VERSION ""

NS_ :

BS_:

BU_: HVESP01 HVESS

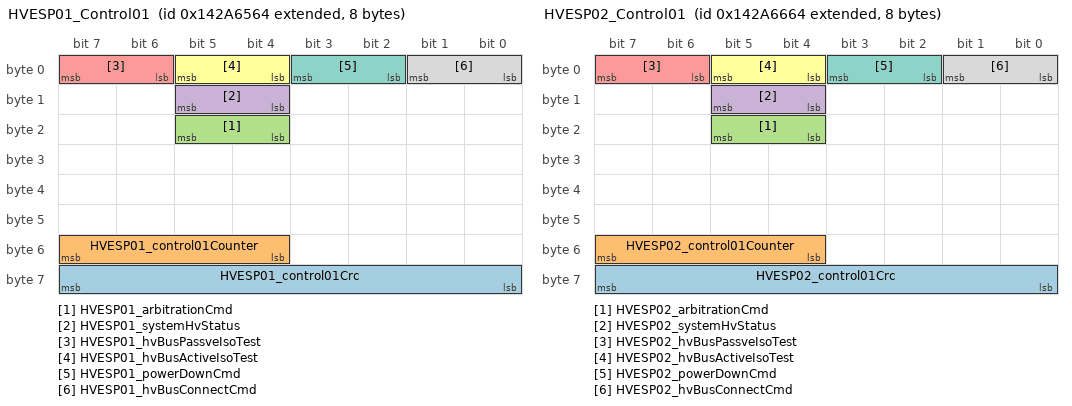
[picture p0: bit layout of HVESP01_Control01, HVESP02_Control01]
BO_ 2485806436 HVESP01_Control01: 8 HVESS
 SG_ HVESP01_control01Crc : 56|8@1+ (1,0) [0|255] ""  HVESS
 SG_ HVESP01_control01Counter : 52|4@1+ (1,0) [0|15] ""  HVESS
 SG_ HVESP01_arbitrationCmd : 20|2@1+ (1,0) [0|3] ""  HVESS
 SG_ HVESP01_systemHvStatus : 12|2@1+ (1,0) [0|3] ""  HVESS
 SG_ HVESP01_hvBusPassveIsoTest : 6|2@1+ (1,0) [0|3] ""  HVESS
 SG_ HVESP01_hvBusActiveIsoTest : 4|2@1+ (1,0) [0|3] ""  HVESS
 SG_ HVESP01_powerDownCmd : 2|2@1+ (1,0) [0|3] ""  HVESS
 SG_ HVESP01_hvBusConnectCmd : 0|2@1+ (1,0) [0|3] ""  HVESS

BO_ 2485806692 HVESP02_Control01: 8 HVESS
 SG_ HVESP02_control01Crc : 56|8@1+ (1,0) [0|255] ""  HVESS
 SG_ HVESP02_control01Counter : 52|4@1+ (1,0) [0|15] ""  HVESS
 SG_ HVESP02_arbitrationCmd : 20|2@1+ (1,0) [0|3] ""  HVESS
 SG_ HVESP02_systemHvStatus : 12|2@1+ (1,0) [0|3] ""  HVESS
 SG_ HVESP02_hvBusPassveIsoTest : 6|2@1+ (1,0) [0|3] ""  HVESS
 SG_ HVESP02_hvBusActiveIsoTest : 4|2@1+ (1,0) [0|3] ""  HVESS
 SG_ HVESP02_powerDownCmd : 2|2@1+ (1,0) [0|3] ""  HVESS
 SG_ HVESP02_hvBusConnectCmd : 0|2@1+ (1,0) [0|3] ""  HVESS

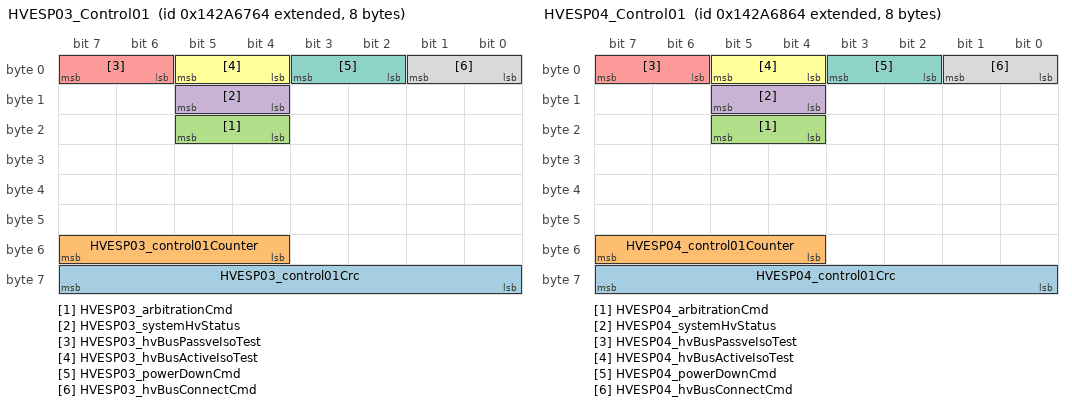
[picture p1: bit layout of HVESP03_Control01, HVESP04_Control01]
BO_ 2485806948 HVESP03_Control01: 8 HVESS
 SG_ HVESP03_control01Crc : 56|8@1+ (1,0) [0|255] ""  HVESS
 SG_ HVESP03_control01Counter : 52|4@1+ (1,0) [0|15] ""  HVESS
 SG_ HVESP03_arbitrationCmd : 20|2@1+ (1,0) [0|3] ""  HVESS
 SG_ HVESP03_systemHvStatus : 12|2@1+ (1,0) [0|3] ""  HVESS
 SG_ HVESP03_hvBusPassveIsoTest : 6|2@1+ (1,0) [0|3] ""  HVESS
 SG_ HVESP03_hvBusActiveIsoTest : 4|2@1+ (1,0) [0|3] ""  HVESS
 SG_ HVESP03_powerDownCmd : 2|2@1+ (1,0) [0|3] ""  HVESS
 SG_ HVESP03_hvBusConnectCmd : 0|2@1+ (1,0) [0|3] ""  HVESS

BO_ 2485807204 HVESP04_Control01: 8 HVESS
 SG_ HVESP04_control01Crc : 56|8@1+ (1,0) [0|255] ""  HVESS
 SG_ HVESP04_control01Counter : 52|4@1+ (1,0) [0|15] ""  HVESS
 SG_ HVESP04_arbitrationCmd : 20|2@1+ (1,0) [0|3] ""  HVESS
 SG_ HVESP04_systemHvStatus : 12|2@1+ (1,0) [0|3] ""  HVESS
 SG_ HVESP04_hvBusPassveIsoTest : 6|2@1+ (1,0) [0|3] ""  HVESS
 SG_ HVESP04_hvBusActiveIsoTest : 4|2@1+ (1,0) [0|3] ""  HVESS
 SG_ HVESP04_powerDownCmd : 2|2@1+ (1,0) [0|3] ""  HVESS
 SG_ HVESP04_hvBusConnectCmd : 0|2@1+ (1,0) [0|3] ""  HVESS

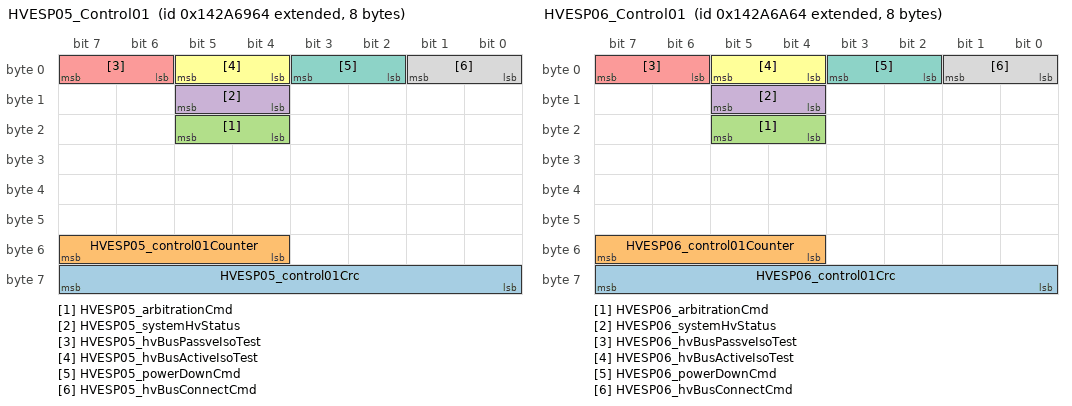
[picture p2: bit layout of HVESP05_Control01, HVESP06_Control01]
BO_ 2485807460 HVESP05_Control01: 8 HVESS
 SG_ HVESP05_control01Crc : 56|8@1+ (1,0) [0|255] ""  HVESS
 SG_ HVESP05_control01Counter : 52|4@1+ (1,0) [0|15] ""  HVESS
 SG_ HVESP05_arbitrationCmd : 20|2@1+ (1,0) [0|3] ""  HVESS
 SG_ HVESP05_systemHvStatus : 12|2@1+ (1,0) [0|3] ""  HVESS
 SG_ HVESP05_hvBusPassveIsoTest : 6|2@1+ (1,0) [0|3] ""  HVESS
 SG_ HVESP05_hvBusActiveIsoTest : 4|2@1+ (1,0) [0|3] ""  HVESS
 SG_ HVESP05_powerDownCmd : 2|2@1+ (1,0) [0|3] ""  HVESS
 SG_ HVESP05_hvBusConnectCmd : 0|2@1+ (1,0) [0|3] ""  HVESS

BO_ 2485807716 HVESP06_Control01: 8 HVESS
 SG_ HVESP06_control01Crc : 56|8@1+ (1,0) [0|255] ""  HVESS
 SG_ HVESP06_control01Counter : 52|4@1+ (1,0) [0|15] ""  HVESS
 SG_ HVESP06_arbitrationCmd : 20|2@1+ (1,0) [0|3] ""  HVESS
 SG_ HVESP06_systemHvStatus : 12|2@1+ (1,0) [0|3] ""  HVESS
 SG_ HVESP06_hvBusPassveIsoTest : 6|2@1+ (1,0) [0|3] ""  HVESS
 SG_ HVESP06_hvBusActiveIsoTest : 4|2@1+ (1,0) [0|3] ""  HVESS
 SG_ HVESP06_powerDownCmd : 2|2@1+ (1,0) [0|3] ""  HVESS
 SG_ HVESP06_hvBusConnectCmd : 0|2@1+ (1,0) [0|3] ""  HVESS

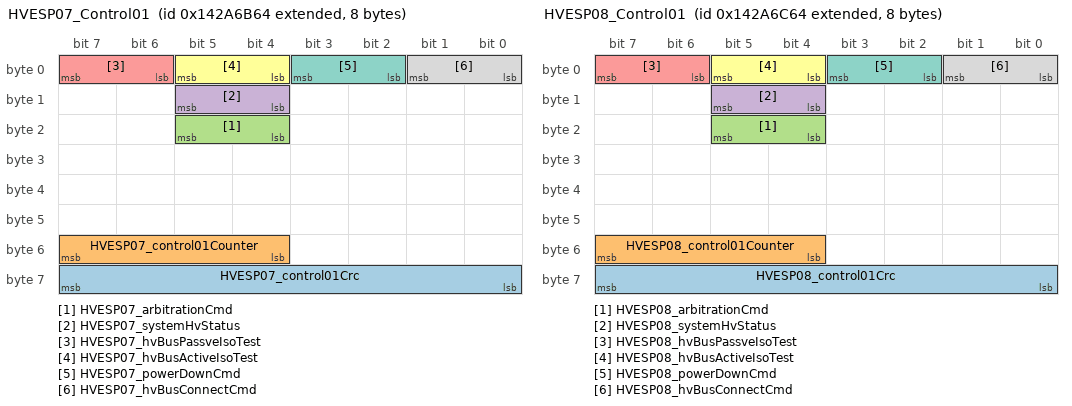
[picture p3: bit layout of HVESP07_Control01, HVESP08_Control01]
BO_ 2485807972 HVESP07_Control01: 8 HVESS
 SG_ HVESP07_control01Crc : 56|8@1+ (1,0) [0|255] ""  HVESS
 SG_ HVESP07_control01Counter : 52|4@1+ (1,0) [0|15] ""  HVESS
 SG_ HVESP07_arbitrationCmd : 20|2@1+ (1,0) [0|3] ""  HVESS
 SG_ HVESP07_systemHvStatus : 12|2@1+ (1,0) [0|3] ""  HVESS
 SG_ HVESP07_hvBusPassveIsoTest : 6|2@1+ (1,0) [0|3] ""  HVESS
 SG_ HVESP07_hvBusActiveIsoTest : 4|2@1+ (1,0) [0|3] ""  HVESS
 SG_ HVESP07_powerDownCmd : 2|2@1+ (1,0) [0|3] ""  HVESS
 SG_ HVESP07_hvBusConnectCmd : 0|2@1+ (1,0) [0|3] ""  HVESS

BO_ 2485808228 HVESP08_Control01: 8 HVESS
 SG_ HVESP08_control01Crc : 56|8@1+ (1,0) [0|255] ""  HVESS
 SG_ HVESP08_control01Counter : 52|4@1+ (1,0) [0|15] ""  HVESS
 SG_ HVESP08_arbitrationCmd : 20|2@1+ (1,0) [0|3] ""  HVESS
 SG_ HVESP08_systemHvStatus : 12|2@1+ (1,0) [0|3] ""  HVESS
 SG_ HVESP08_hvBusPassveIsoTest : 6|2@1+ (1,0) [0|3] ""  HVESS
 SG_ HVESP08_hvBusActiveIsoTest : 4|2@1+ (1,0) [0|3] ""  HVESS
 SG_ HVESP08_powerDownCmd : 2|2@1+ (1,0) [0|3] ""  HVESS
 SG_ HVESP08_hvBusConnectCmd : 0|2@1+ (1,0) [0|3] ""  HVESS

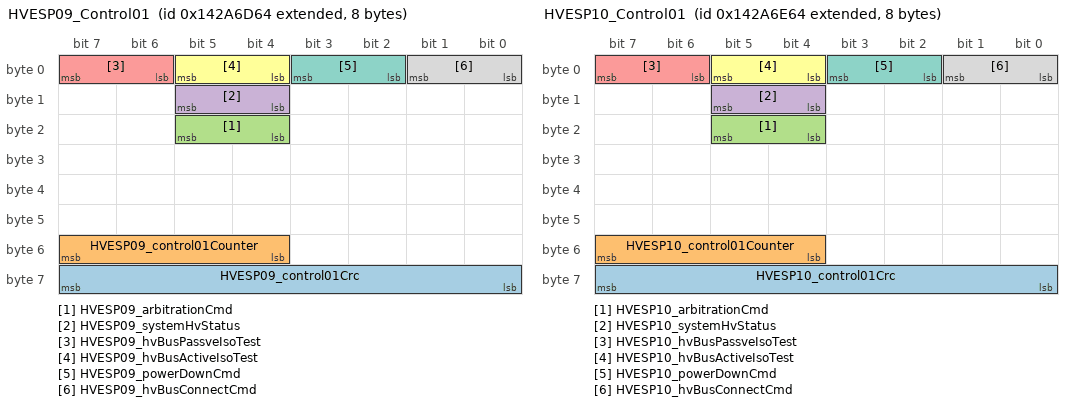
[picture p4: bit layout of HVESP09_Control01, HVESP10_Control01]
BO_ 2485808484 HVESP09_Control01: 8 HVESS
 SG_ HVESP09_control01Crc : 56|8@1+ (1,0) [0|255] ""  HVESS
 SG_ HVESP09_control01Counter : 52|4@1+ (1,0) [0|15] ""  HVESS
 SG_ HVESP09_arbitrationCmd : 20|2@1+ (1,0) [0|3] ""  HVESS
 SG_ HVESP09_systemHvStatus : 12|2@1+ (1,0) [0|3] ""  HVESS
 SG_ HVESP09_hvBusPassveIsoTest : 6|2@1+ (1,0) [0|3] ""  HVESS
 SG_ HVESP09_hvBusActiveIsoTest : 4|2@1+ (1,0) [0|3] ""  HVESS
 SG_ HVESP09_powerDownCmd : 2|2@1+ (1,0) [0|3] ""  HVESS
 SG_ HVESP09_hvBusConnectCmd : 0|2@1+ (1,0) [0|3] ""  HVESS

BO_ 2485808740 HVESP10_Control01: 8 HVESS
 SG_ HVESP10_control01Crc : 56|8@1+ (1,0) [0|255] ""  HVESS
 SG_ HVESP10_control01Counter : 52|4@1+ (1,0) [0|15] ""  HVESS
 SG_ HVESP10_arbitrationCmd : 20|2@1+ (1,0) [0|3] ""  HVESS
 SG_ HVESP10_systemHvStatus : 12|2@1+ (1,0) [0|3] ""  HVESS
 SG_ HVESP10_hvBusPassveIsoTest : 6|2@1+ (1,0) [0|3] ""  HVESS
 SG_ HVESP10_hvBusActiveIsoTest : 4|2@1+ (1,0) [0|3] ""  HVESS
 SG_ HVESP10_powerDownCmd : 2|2@1+ (1,0) [0|3] ""  HVESS
 SG_ HVESP10_hvBusConnectCmd : 0|2@1+ (1,0) [0|3] ""  HVESS

BO_ 2498859365 HVESP01_Data01_1: 8 HVESP01
 SG_ HVESP01_current_1 : 48|16@1+ (0.05,-1600) [-1600|1612.75] "A"  HVESP01
 SG_ HVESP01_voltageLevel_1 : 32|16@1+ (0.05,0) [0|3212.75] "V"  HVESP01
 SG_ HVESP01_availableDischargePower_1 : 0|16@1+ (0.05,0) [0|3212.75] "kW"  HVESP01
 SG_ HVESP01_availableChargePower_1 : 16|16@1+ (0.05,0) [0|3212.75] "kW"  HVESP01

BO_ 2498859366 HVESP01_Data01_2: 8 HVESP01
 SG_ HVESP01_current_2 : 48|16@1+ (0.05,-1600) [-1600|1612.75] "A"  HVESP01
 SG_ HVESP01_voltageLevel_2 : 32|16@1+ (0.05,0) [0|3212.75] "V"  HVESP01
 SG_ HVESP01_availableDischargePower_2 : 0|16@1+ (0.05,0) [0|3212.75] "kW"  HVESP01
 SG_ HVESP01_availableChargePower_2 : 16|16@1+ (0.05,0) [0|3212.75] "kW"  HVESP01

BO_ 2498859367 HVESP01_Data01_3: 8 HVESP01
 SG_ HVESP01_current_3 : 48|16@1+ (0.05,-1600) [-1600|1612.75] "A"  HVESP01
 SG_ HVESP01_voltageLevel_3 : 32|16@1+ (0.05,0) [0|3212.75] "V"  HVESP01
 SG_ HVESP01_availableDischargePower_3 : 0|16@1+ (0.05,0) [0|3212.75] "kW"  HVESP01
 SG_ HVESP01_availableChargePower_3 : 16|16@1+ (0.05,0) [0|3212.75] "kW"  HVESP01

BO_ 2498859368 HVESP01_Data01_4: 8 HVESP01
 SG_ HVESP01_current_4 : 48|16@1+ (0.05,-1600) [-1600|1612.75] "A"  HVESP01
 SG_ HVESP01_voltageLevel_4 : 32|16@1+ (0.05,0) [0|3212.75] "V"  HVESP01
 SG_ HVESP01_availableDischargePower_4 : 0|16@1+ (0.05,0) [0|3212.75] "kW"  HVESP01
 SG_ HVESP01_availableChargePower_4 : 16|16@1+ (0.05,0) [0|3212.75] "kW"  HVESP01

BO_ 2498859369 HVESP01_Data01_5: 8 HVESP01
 SG_ HVESP01_current_5 : 48|16@1+ (0.05,-1600) [-1600|1612.75] "A"  HVESP01
 SG_ HVESP01_voltageLevel_5 : 32|16@1+ (0.05,0) [0|3212.75] "V"  HVESP01
 SG_ HVESP01_availableDischargePower_5 : 0|16@1+ (0.05,0) [0|3212.75] "kW"  HVESP01
 SG_ HVESP01_availableChargePower_5 : 16|16@1+ (0.05,0) [0|3212.75] "kW"  HVESP01

BO_ 2498859370 HVESP01_Data01_6: 8 HVESP01
 SG_ HVESP01_current_6 : 48|16@1+ (0.05,-1600) [-1600|1612.75] "A"  HVESP01
 SG_ HVESP01_voltageLevel_6 : 32|16@1+ (0.05,0) [0|3212.75] "V"  HVESP01
 SG_ HVESP01_availableDischargePower_6 : 0|16@1+ (0.05,0) [0|3212.75] "kW"  HVESP01
 SG_ HVESP01_availableChargePower_6 : 16|16@1+ (0.05,0) [0|3212.75] "kW"  HVESP01

BO_ 2498859371 HVESP01_Data01_7: 8 HVESP01
 SG_ HVESP01_current_7 : 48|16@1+ (0.05,-1600) [-1600|1612.75] "A"  HVESP01
 SG_ HVESP01_voltageLevel_7 : 32|16@1+ (0.05,0) [0|3212.75] "V"  HVESP01
 SG_ HVESP01_availableDischargePower_7 : 0|16@1+ (0.05,0) [0|3212.75] "kW"  HVESP01
 SG_ HVESP01_availableChargePower_7 : 16|16@1+ (0.05,0) [0|3212.75] "kW"  HVESP01

BO_ 2498859372 HVESP01_Data01_8: 8 HVESP01
 SG_ HVESP01_current_8 : 48|16@1+ (0.05,-1600) [-1600|1612.75] "A"  HVESP01
 SG_ HVESP01_voltageLevel_8 : 32|16@1+ (0.05,0) [0|3212.75] "V"  HVESP01
 SG_ HVESP01_availableDischargePower_8 : 0|16@1+ (0.05,0) [0|3212.75] "kW"  HVESP01
 SG_ HVESP01_availableChargePower_8 : 16|16@1+ (0.05,0) [0|3212.75] "kW"  HVESP01

BO_ 2498859621 HVESP01_Data02_1: 8 HVESP01
 SG_ HVESP01_FaultLevel_1 : 56|4@1+ (1,0) [0|15] ""  HVESP01
 SG_ HVESP01_lowestCellVoltage_1 : 32|16@1+ (0.001,0) [0|64.255] "V"  HVESP01
 SG_ HVESP01_highestCellVoltage_1 : 16|16@1+ (0.001,0) [0|64.255] "V"  HVESP01
 SG_ HVESP01_fastUpdateSoc_1 : 0|16@1+ (0.0015625,0) [0|100.3984375] "%"  HVESP01

BO_ 2498859622 HVESP01_Data02_2: 8 HVESP01
 SG_ HVESP01_FaultLevel_2 : 56|4@1+ (1,0) [0|15] ""  HVESP01
 SG_ HVESP01_lowestCellVoltage_2 : 32|16@1+ (0.001,0) [0|64.255] "V"  HVESP01
 SG_ HVESP01_highestCellVoltage_2 : 16|16@1+ (0.001,0) [0|64.255] "V"  HVESP01
 SG_ HVESP01_fastUpdateSoc_2 : 0|16@1+ (0.0015625,0) [0|100.3984375] "%"  HVESP01

BO_ 2498859623 HVESP01_Data02_3: 8 HVESP01
 SG_ HVESP01_FaultLevel_3 : 56|4@1+ (1,0) [0|15] ""  HVESP01
 SG_ HVESP01_lowestCellVoltage_3 : 32|16@1+ (0.001,0) [0|64.255] "V"  HVESP01
 SG_ HVESP01_highestCellVoltage_3 : 16|16@1+ (0.001,0) [0|64.255] "V"  HVESP01
 SG_ HVESP01_fastUpdateSoc_3 : 0|16@1+ (0.0015625,0) [0|100.3984375] "%"  HVESP01

BO_ 2498859624 HVESP01_Data02_4: 8 HVESP01
 SG_ HVESP01_FaultLevel_4 : 56|4@1+ (1,0) [0|15] ""  HVESP01
 SG_ HVESP01_lowestCellVoltage_4 : 32|16@1+ (0.001,0) [0|64.255] "V"  HVESP01
 SG_ HVESP01_highestCellVoltage_4 : 16|16@1+ (0.001,0) [0|64.255] "V"  HVESP01
 SG_ HVESP01_fastUpdateSoc_4 : 0|16@1+ (0.0015625,0) [0|100.3984375] "%"  HVESP01

BO_ 2498859625 HVESP01_Data02_5: 8 HVESP01
 SG_ HVESP01_FaultLevel_5 : 56|4@1+ (1,0) [0|15] ""  HVESP01
 SG_ HVESP01_lowestCellVoltage_5 : 32|16@1+ (0.001,0) [0|64.255] "V"  HVESP01
 SG_ HVESP01_highestCellVoltage_5 : 16|16@1+ (0.001,0) [0|64.255] "V"  HVESP01
 SG_ HVESP01_fastUpdateSoc_5 : 0|16@1+ (0.0015625,0) [0|100.3984375] "%"  HVESP01

BO_ 2498859626 HVESP01_Data02_6: 8 HVESP01
 SG_ HVESP01_FaultLevel_6 : 56|4@1+ (1,0) [0|15] ""  HVESP01
 SG_ HVESP01_lowestCellVoltage_6 : 32|16@1+ (0.001,0) [0|64.255] "V"  HVESP01
 SG_ HVESP01_highestCellVoltage_6 : 16|16@1+ (0.001,0) [0|64.255] "V"  HVESP01
 SG_ HVESP01_fastUpdateSoc_6 : 0|16@1+ (0.0015625,0) [0|100.3984375] "%"  HVESP01

BO_ 2498859627 HVESP01_Data02_7: 8 HVESP01
 SG_ HVESP01_FaultLevel_7 : 56|4@1+ (1,0) [0|15] ""  HVESP01
 SG_ HVESP01_lowestCellVoltage_7 : 32|16@1+ (0.001,0) [0|64.255] "V"  HVESP01
 SG_ HVESP01_highestCellVoltage_7 : 16|16@1+ (0.001,0) [0|64.255] "V"  HVESP01
 SG_ HVESP01_fastUpdateSoc_7 : 0|16@1+ (0.0015625,0) [0|100.3984375] "%"  HVESP01

BO_ 2498859628 HVESP01_Data02_8: 8 HVESP01
 SG_ HVESP01_FaultLevel_8 : 56|4@1+ (1,0) [0|15] ""  HVESP01
 SG_ HVESP01_lowestCellVoltage_8 : 32|16@1+ (0.001,0) [0|64.255] "V"  HVESP01
 SG_ HVESP01_highestCellVoltage_8 : 16|16@1+ (0.001,0) [0|64.255] "V"  HVESP01
 SG_ HVESP01_fastUpdateSoc_8 : 0|16@1+ (0.0015625,0) [0|100.3984375] "%"  HVESP01

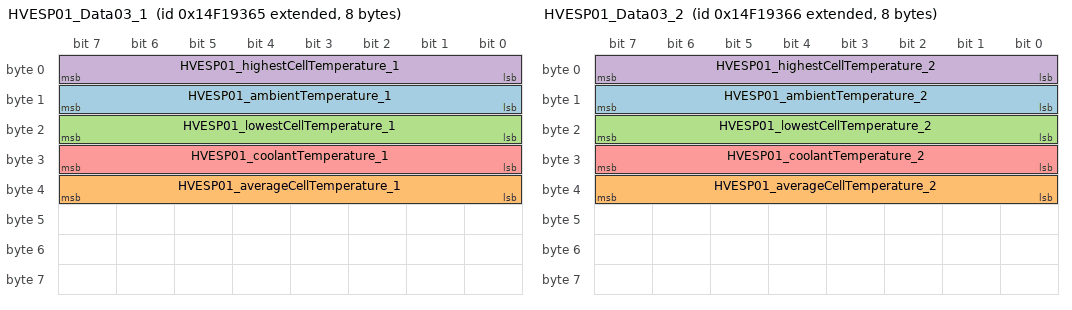
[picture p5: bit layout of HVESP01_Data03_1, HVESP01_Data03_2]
BO_ 2498859877 HVESP01_Data03_1: 8 HVESP01
 SG_ HVESP01_ambientTemperature_1 : 8|8@1- (1,25) [-103|152] "C"  HVESP01
 SG_ HVESP01_averageCellTemperature_1 : 32|8@1- (1,25) [-103|152] "C"  HVESP01
 SG_ HVESP01_lowestCellTemperature_1 : 16|8@1- (1,25) [-103|152] "C"  HVESP01
 SG_ HVESP01_highestCellTemperature_1 : 0|8@1- (1,25) [-103|152] "C"  HVESP01
 SG_ HVESP01_coolantTemperature_1 : 24|8@1- (1,25) [-103|152] "C"  HVESP01

BO_ 2498859878 HVESP01_Data03_2: 8 HVESP01
 SG_ HVESP01_ambientTemperature_2 : 8|8@1- (1,25) [-103|152] "C"  HVESP01
 SG_ HVESP01_averageCellTemperature_2 : 32|8@1- (1,25) [-103|152] "C"  HVESP01
 SG_ HVESP01_lowestCellTemperature_2 : 16|8@1- (1,25) [-103|152] "C"  HVESP01
 SG_ HVESP01_highestCellTemperature_2 : 0|8@1- (1,25) [-103|152] "C"  HVESP01
 SG_ HVESP01_coolantTemperature_2 : 24|8@1- (1,25) [-103|152] "C"  HVESP01

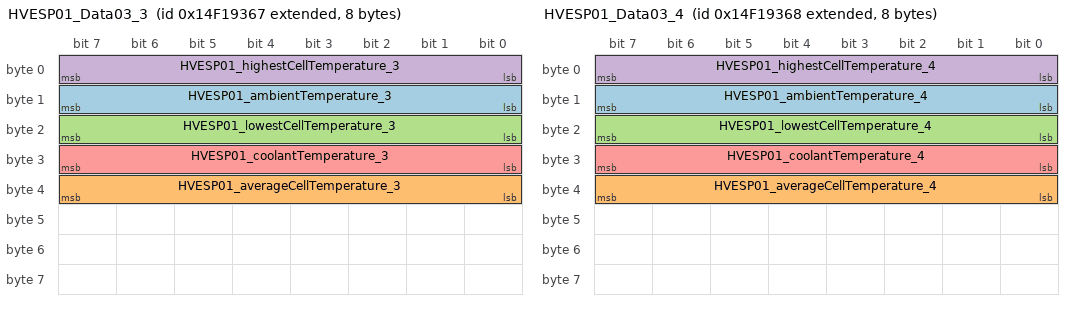
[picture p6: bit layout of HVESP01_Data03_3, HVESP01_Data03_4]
BO_ 2498859879 HVESP01_Data03_3: 8 HVESP01
 SG_ HVESP01_ambientTemperature_3 : 8|8@1- (1,25) [-103|152] "C"  HVESP01
 SG_ HVESP01_averageCellTemperature_3 : 32|8@1- (1,25) [-103|152] "C"  HVESP01
 SG_ HVESP01_lowestCellTemperature_3 : 16|8@1- (1,25) [-103|152] "C"  HVESP01
 SG_ HVESP01_highestCellTemperature_3 : 0|8@1- (1,25) [-103|152] "C"  HVESP01
 SG_ HVESP01_coolantTemperature_3 : 24|8@1- (1,25) [-103|152] "C"  HVESP01

BO_ 2498859880 HVESP01_Data03_4: 8 HVESP01
 SG_ HVESP01_ambientTemperature_4 : 8|8@1- (1,25) [-103|152] "C"  HVESP01
 SG_ HVESP01_averageCellTemperature_4 : 32|8@1- (1,25) [-103|152] "C"  HVESP01
 SG_ HVESP01_lowestCellTemperature_4 : 16|8@1- (1,25) [-103|152] "C"  HVESP01
 SG_ HVESP01_highestCellTemperature_4 : 0|8@1- (1,25) [-103|152] "C"  HVESP01
 SG_ HVESP01_coolantTemperature_4 : 24|8@1- (1,25) [-103|152] "C"  HVESP01

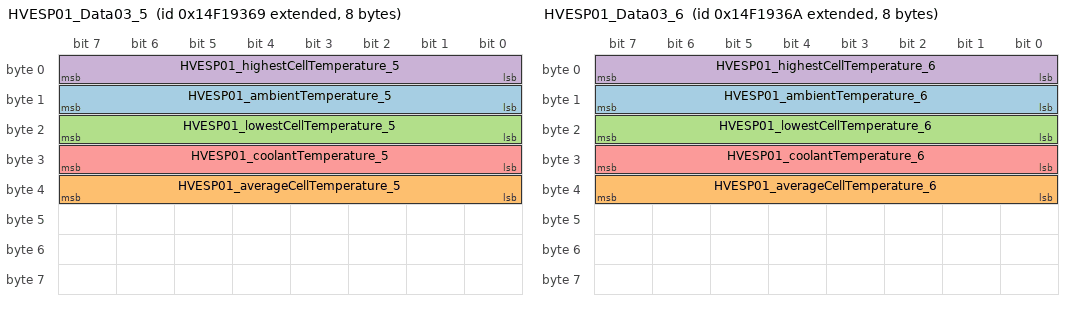
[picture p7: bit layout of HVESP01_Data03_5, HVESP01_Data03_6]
BO_ 2498859881 HVESP01_Data03_5: 8 HVESP01
 SG_ HVESP01_ambientTemperature_5 : 8|8@1- (1,25) [-103|152] "C"  HVESP01
 SG_ HVESP01_averageCellTemperature_5 : 32|8@1- (1,25) [-103|152] "C"  HVESP01
 SG_ HVESP01_lowestCellTemperature_5 : 16|8@1- (1,25) [-103|152] "C"  HVESP01
 SG_ HVESP01_highestCellTemperature_5 : 0|8@1- (1,25) [-103|152] "C"  HVESP01
 SG_ HVESP01_coolantTemperature_5 : 24|8@1- (1,25) [-103|152] "C"  HVESP01

BO_ 2498859882 HVESP01_Data03_6: 8 HVESP01
 SG_ HVESP01_ambientTemperature_6 : 8|8@1- (1,25) [-103|152] "C"  HVESP01
 SG_ HVESP01_averageCellTemperature_6 : 32|8@1- (1,25) [-103|152] "C"  HVESP01
 SG_ HVESP01_lowestCellTemperature_6 : 16|8@1- (1,25) [-103|152] "C"  HVESP01
 SG_ HVESP01_highestCellTemperature_6 : 0|8@1- (1,25) [-103|152] "C"  HVESP01
 SG_ HVESP01_coolantTemperature_6 : 24|8@1- (1,25) [-103|152] "C"  HVESP01

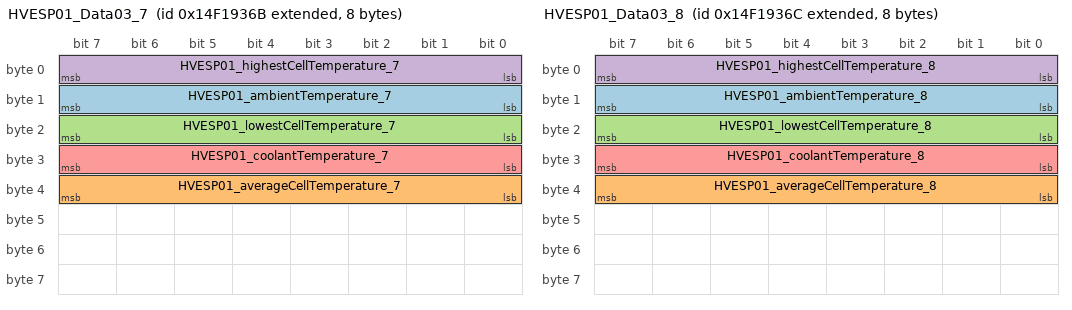
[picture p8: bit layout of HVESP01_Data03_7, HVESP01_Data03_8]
BO_ 2498859883 HVESP01_Data03_7: 8 HVESP01
 SG_ HVESP01_ambientTemperature_7 : 8|8@1- (1,25) [-103|152] "C"  HVESP01
 SG_ HVESP01_averageCellTemperature_7 : 32|8@1- (1,25) [-103|152] "C"  HVESP01
 SG_ HVESP01_lowestCellTemperature_7 : 16|8@1- (1,25) [-103|152] "C"  HVESP01
 SG_ HVESP01_highestCellTemperature_7 : 0|8@1- (1,25) [-103|152] "C"  HVESP01
 SG_ HVESP01_coolantTemperature_7 : 24|8@1- (1,25) [-103|152] "C"  HVESP01

BO_ 2498859884 HVESP01_Data03_8: 8 HVESP01
 SG_ HVESP01_ambientTemperature_8 : 8|8@1- (1,25) [-103|152] "C"  HVESP01
 SG_ HVESP01_averageCellTemperature_8 : 32|8@1- (1,25) [-103|152] "C"  HVESP01
 SG_ HVESP01_lowestCellTemperature_8 : 16|8@1- (1,25) [-103|152] "C"  HVESP01
 SG_ HVESP01_highestCellTemperature_8 : 0|8@1- (1,25) [-103|152] "C"  HVESP01
 SG_ HVESP01_coolantTemperature_8 : 24|8@1- (1,25) [-103|152] "C"  HVESP01

BO_ 2498860389 HVESP01_Data05_1: 8 HVESP01
 SG_ HVESP01_highestSoc_1 : 48|16@1+ (0.0015625,0) [0|100.3984375] "%"  HVESP01
 SG_ HVESP01_lowestSoc_1 : 32|16@1+ (0.0015625,0) [0|100.3984375] "%"  HVESP01
 SG_ HVESP01_chargeCurrentLimit_1 : 16|16@1+ (0.05,-1600) [-1600|1612.75] "A"  HVESP01
 SG_ HVESP01_dischargeCurrentLimit_1 : 0|16@1+ (0.05,-1600) [-1600|1612.75] "A"  HVESP01

BO_ 2498860390 HVESP01_Data05_2: 8 HVESP01
 SG_ HVESP01_highestSoc_2 : 48|16@1+ (0.0015625,0) [0|100.3984375] "%"  HVESP01
 SG_ HVESP01_lowestSoc_2 : 32|16@1+ (0.0015625,0) [0|100.3984375] "%"  HVESP01
 SG_ HVESP01_chargeCurrentLimit_2 : 16|16@1+ (0.05,-1600) [-1600|1612.75] "A"  HVESP01
 SG_ HVESP01_dischargeCurrentLimit_2 : 0|16@1+ (0.05,-1600) [-1600|1612.75] "A"  HVESP01

BO_ 2498860391 HVESP01_Data05_3: 8 HVESP01
 SG_ HVESP01_highestSoc_3 : 48|16@1+ (0.0015625,0) [0|100.3984375] "%"  HVESP01
 SG_ HVESP01_lowestSoc_3 : 32|16@1+ (0.0015625,0) [0|100.3984375] "%"  HVESP01
 SG_ HVESP01_chargeCurrentLimit_3 : 16|16@1+ (0.05,-1600) [-1600|1612.75] "A"  HVESP01
 SG_ HVESP01_dischargeCurrentLimit_3 : 0|16@1+ (0.05,-1600) [-1600|1612.75] "A"  HVESP01

BO_ 2498860392 HVESP01_Data05_4: 8 HVESP01
 SG_ HVESP01_highestSoc_4 : 48|16@1+ (0.0015625,0) [0|100.3984375] "%"  HVESP01
 SG_ HVESP01_lowestSoc_4 : 32|16@1+ (0.0015625,0) [0|100.3984375] "%"  HVESP01
 SG_ HVESP01_chargeCurrentLimit_4 : 16|16@1+ (0.05,-1600) [-1600|1612.75] "A"  HVESP01
 SG_ HVESP01_dischargeCurrentLimit_4 : 0|16@1+ (0.05,-1600) [-1600|1612.75] "A"  HVESP01

BO_ 2498860393 HVESP01_Data05_5: 8 HVESP01
 SG_ HVESP01_highestSoc_5 : 48|16@1+ (0.0015625,0) [0|100.3984375] "%"  HVESP01
 SG_ HVESP01_lowestSoc_5 : 32|16@1+ (0.0015625,0) [0|100.3984375] "%"  HVESP01
 SG_ HVESP01_chargeCurrentLimit_5 : 16|16@1+ (0.05,-1600) [-1600|1612.75] "A"  HVESP01
 SG_ HVESP01_dischargeCurrentLimit_5 : 0|16@1+ (0.05,-1600) [-1600|1612.75] "A"  HVESP01

BO_ 2498860394 HVESP01_Data05_6: 8 HVESP01
 SG_ HVESP01_highestSoc_6 : 48|16@1+ (0.0015625,0) [0|100.3984375] "%"  HVESP01
 SG_ HVESP01_lowestSoc_6 : 32|16@1+ (0.0015625,0) [0|100.3984375] "%"  HVESP01
 SG_ HVESP01_chargeCurrentLimit_6 : 16|16@1+ (0.05,-1600) [-1600|1612.75] "A"  HVESP01
 SG_ HVESP01_dischargeCurrentLimit_6 : 0|16@1+ (0.05,-1600) [-1600|1612.75] "A"  HVESP01

BO_ 2498860395 HVESP01_Data05_7: 8 HVESP01
 SG_ HVESP01_highestSoc_7 : 48|16@1+ (0.0015625,0) [0|100.3984375] "%"  HVESP01
 SG_ HVESP01_lowestSoc_7 : 32|16@1+ (0.0015625,0) [0|100.3984375] "%"  HVESP01
 SG_ HVESP01_chargeCurrentLimit_7 : 16|16@1+ (0.05,-1600) [-1600|1612.75] "A"  HVESP01
 SG_ HVESP01_dischargeCurrentLimit_7 : 0|16@1+ (0.05,-1600) [-1600|1612.75] "A"  HVESP01

BO_ 2498860396 HVESP01_Data05_8: 8 HVESP01
 SG_ HVESP01_highestSoc_8 : 48|16@1+ (0.0015625,0) [0|100.3984375] "%"  HVESP01
 SG_ HVESP01_lowestSoc_8 : 32|16@1+ (0.0015625,0) [0|100.3984375] "%"  HVESP01
 SG_ HVESP01_chargeCurrentLimit_8 : 16|16@1+ (0.05,-1600) [-1600|1612.75] "A"  HVESP01
 SG_ HVESP01_dischargeCurrentLimit_8 : 0|16@1+ (0.05,-1600) [-1600|1612.75] "A"  HVESP01

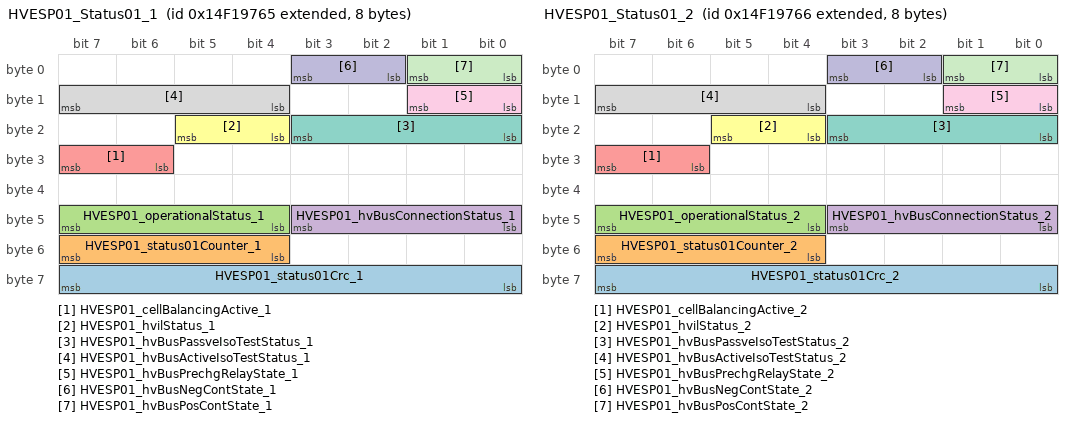
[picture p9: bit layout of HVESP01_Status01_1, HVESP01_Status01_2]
BO_ 2498860901 HVESP01_Status01_1: 8 HVESP01
 SG_ HVESP01_status01Crc_1 : 56|8@1+ (1,0) [0|255] "count"  HVESP01
 SG_ HVESP01_status01Counter_1 : 52|4@1+ (1,0) [0|15] ""  HVESP01
 SG_ HVESP01_operationalStatus_1 : 44|4@1+ (1,0) [0|15] ""  HVESP01
 SG_ HVESP01_hvBusConnectionStatus_1 : 40|4@1+ (1,0) [0|15] ""  HVESP01
 SG_ HVESP01_cellBalancingActive_1 : 30|2@1+ (1,0) [0|3] ""  HVESP01
 SG_ HVESP01_hvilStatus_1 : 20|2@1+ (1,0) [0|3] ""  HVESP01
 SG_ HVESP01_hvBusPassveIsoTestStatus_1 : 16|4@1+ (1,0) [0|15] ""  HVESP01
 SG_ HVESP01_hvBusActiveIsoTestStatus_1 : 12|4@1+ (1,0) [0|15] ""  HVESP01
 SG_ HVESP01_hvBusPrechgRelayState_1 : 8|2@1+ (1,0) [0|3] "V"  HVESP01
 SG_ HVESP01_hvBusNegContState_1 : 2|2@1+ (1,0) [0|3] "V"  HVESP01
 SG_ HVESP01_hvBusPosContState_1 : 0|2@1+ (1,0) [0|3] "V"  HVESP01

BO_ 2498860902 HVESP01_Status01_2: 8 HVESP01
 SG_ HVESP01_status01Crc_2 : 56|8@1+ (1,0) [0|255] "count"  HVESP01
 SG_ HVESP01_status01Counter_2 : 52|4@1+ (1,0) [0|15] ""  HVESP01
 SG_ HVESP01_operationalStatus_2 : 44|4@1+ (1,0) [0|15] ""  HVESP01
 SG_ HVESP01_hvBusConnectionStatus_2 : 40|4@1+ (1,0) [0|15] ""  HVESP01
 SG_ HVESP01_cellBalancingActive_2 : 30|2@1+ (1,0) [0|3] ""  HVESP01
 SG_ HVESP01_hvilStatus_2 : 20|2@1+ (1,0) [0|3] ""  HVESP01
 SG_ HVESP01_hvBusPassveIsoTestStatus_2 : 16|4@1+ (1,0) [0|15] ""  HVESP01
 SG_ HVESP01_hvBusActiveIsoTestStatus_2 : 12|4@1+ (1,0) [0|15] ""  HVESP01
 SG_ HVESP01_hvBusPrechgRelayState_2 : 8|2@1+ (1,0) [0|3] "V"  HVESP01
 SG_ HVESP01_hvBusNegContState_2 : 2|2@1+ (1,0) [0|3] "V"  HVESP01
 SG_ HVESP01_hvBusPosContState_2 : 0|2@1+ (1,0) [0|3] "V"  HVESP01

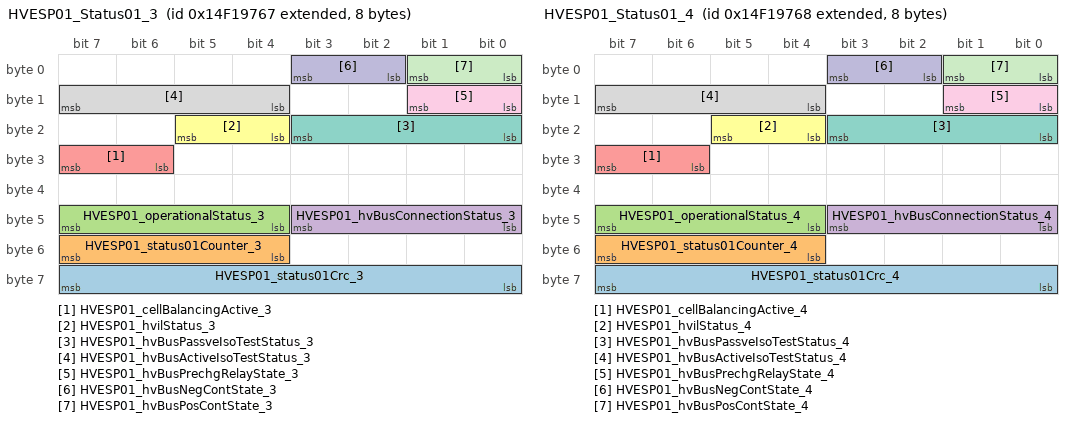
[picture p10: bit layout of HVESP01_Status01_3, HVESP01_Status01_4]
BO_ 2498860903 HVESP01_Status01_3: 8 HVESP01
 SG_ HVESP01_status01Crc_3 : 56|8@1+ (1,0) [0|255] "count"  HVESP01
 SG_ HVESP01_status01Counter_3 : 52|4@1+ (1,0) [0|15] ""  HVESP01
 SG_ HVESP01_operationalStatus_3 : 44|4@1+ (1,0) [0|15] ""  HVESP01
 SG_ HVESP01_hvBusConnectionStatus_3 : 40|4@1+ (1,0) [0|15] ""  HVESP01
 SG_ HVESP01_cellBalancingActive_3 : 30|2@1+ (1,0) [0|3] ""  HVESP01
 SG_ HVESP01_hvilStatus_3 : 20|2@1+ (1,0) [0|3] ""  HVESP01
 SG_ HVESP01_hvBusPassveIsoTestStatus_3 : 16|4@1+ (1,0) [0|15] ""  HVESP01
 SG_ HVESP01_hvBusActiveIsoTestStatus_3 : 12|4@1+ (1,0) [0|15] ""  HVESP01
 SG_ HVESP01_hvBusPrechgRelayState_3 : 8|2@1+ (1,0) [0|3] "V"  HVESP01
 SG_ HVESP01_hvBusNegContState_3 : 2|2@1+ (1,0) [0|3] "V"  HVESP01
 SG_ HVESP01_hvBusPosContState_3 : 0|2@1+ (1,0) [0|3] "V"  HVESP01

BO_ 2498860904 HVESP01_Status01_4: 8 HVESP01
 SG_ HVESP01_status01Crc_4 : 56|8@1+ (1,0) [0|255] "count"  HVESP01
 SG_ HVESP01_status01Counter_4 : 52|4@1+ (1,0) [0|15] ""  HVESP01
 SG_ HVESP01_operationalStatus_4 : 44|4@1+ (1,0) [0|15] ""  HVESP01
 SG_ HVESP01_hvBusConnectionStatus_4 : 40|4@1+ (1,0) [0|15] ""  HVESP01
 SG_ HVESP01_cellBalancingActive_4 : 30|2@1+ (1,0) [0|3] ""  HVESP01
 SG_ HVESP01_hvilStatus_4 : 20|2@1+ (1,0) [0|3] ""  HVESP01
 SG_ HVESP01_hvBusPassveIsoTestStatus_4 : 16|4@1+ (1,0) [0|15] ""  HVESP01
 SG_ HVESP01_hvBusActiveIsoTestStatus_4 : 12|4@1+ (1,0) [0|15] ""  HVESP01
 SG_ HVESP01_hvBusPrechgRelayState_4 : 8|2@1+ (1,0) [0|3] "V"  HVESP01
 SG_ HVESP01_hvBusNegContState_4 : 2|2@1+ (1,0) [0|3] "V"  HVESP01
 SG_ HVESP01_hvBusPosContState_4 : 0|2@1+ (1,0) [0|3] "V"  HVESP01

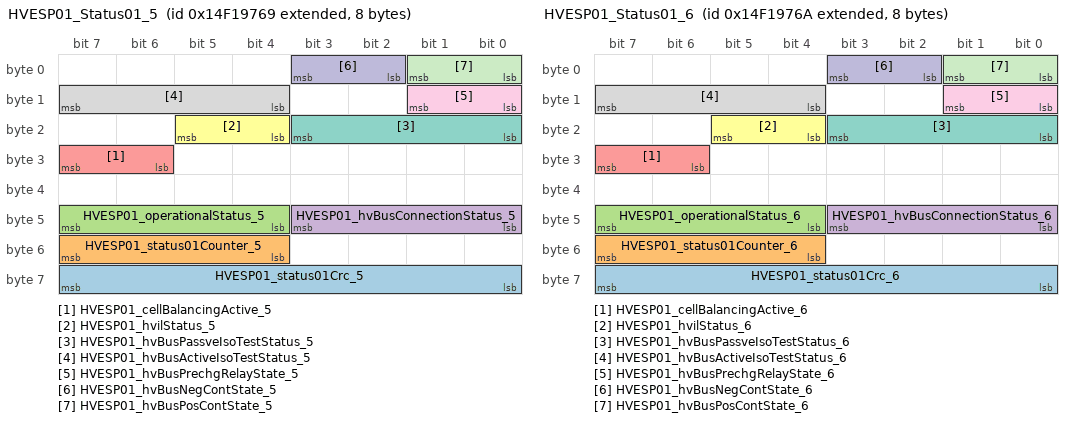
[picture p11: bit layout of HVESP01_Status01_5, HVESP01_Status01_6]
BO_ 2498860905 HVESP01_Status01_5: 8 HVESP01
 SG_ HVESP01_status01Crc_5 : 56|8@1+ (1,0) [0|255] "count"  HVESP01
 SG_ HVESP01_status01Counter_5 : 52|4@1+ (1,0) [0|15] ""  HVESP01
 SG_ HVESP01_operationalStatus_5 : 44|4@1+ (1,0) [0|15] ""  HVESP01
 SG_ HVESP01_hvBusConnectionStatus_5 : 40|4@1+ (1,0) [0|15] ""  HVESP01
 SG_ HVESP01_cellBalancingActive_5 : 30|2@1+ (1,0) [0|3] ""  HVESP01
 SG_ HVESP01_hvilStatus_5 : 20|2@1+ (1,0) [0|3] ""  HVESP01
 SG_ HVESP01_hvBusPassveIsoTestStatus_5 : 16|4@1+ (1,0) [0|15] ""  HVESP01
 SG_ HVESP01_hvBusActiveIsoTestStatus_5 : 12|4@1+ (1,0) [0|15] ""  HVESP01
 SG_ HVESP01_hvBusPrechgRelayState_5 : 8|2@1+ (1,0) [0|3] "V"  HVESP01
 SG_ HVESP01_hvBusNegContState_5 : 2|2@1+ (1,0) [0|3] "V"  HVESP01
 SG_ HVESP01_hvBusPosContState_5 : 0|2@1+ (1,0) [0|3] "V"  HVESP01

BO_ 2498860906 HVESP01_Status01_6: 8 HVESP01
 SG_ HVESP01_status01Crc_6 : 56|8@1+ (1,0) [0|255] "count"  HVESP01
 SG_ HVESP01_status01Counter_6 : 52|4@1+ (1,0) [0|15] ""  HVESP01
 SG_ HVESP01_operationalStatus_6 : 44|4@1+ (1,0) [0|15] ""  HVESP01
 SG_ HVESP01_hvBusConnectionStatus_6 : 40|4@1+ (1,0) [0|15] ""  HVESP01
 SG_ HVESP01_cellBalancingActive_6 : 30|2@1+ (1,0) [0|3] ""  HVESP01
 SG_ HVESP01_hvilStatus_6 : 20|2@1+ (1,0) [0|3] ""  HVESP01
 SG_ HVESP01_hvBusPassveIsoTestStatus_6 : 16|4@1+ (1,0) [0|15] ""  HVESP01
 SG_ HVESP01_hvBusActiveIsoTestStatus_6 : 12|4@1+ (1,0) [0|15] ""  HVESP01
 SG_ HVESP01_hvBusPrechgRelayState_6 : 8|2@1+ (1,0) [0|3] "V"  HVESP01
 SG_ HVESP01_hvBusNegContState_6 : 2|2@1+ (1,0) [0|3] "V"  HVESP01
 SG_ HVESP01_hvBusPosContState_6 : 0|2@1+ (1,0) [0|3] "V"  HVESP01

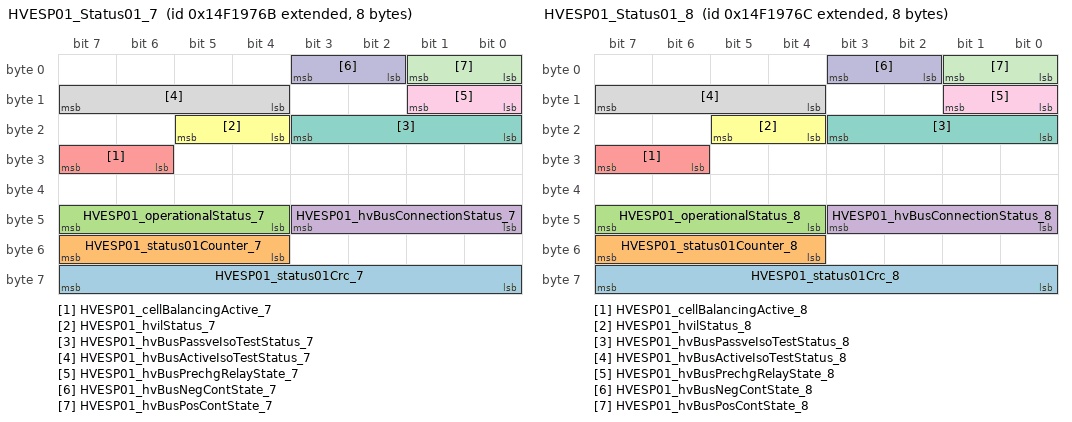
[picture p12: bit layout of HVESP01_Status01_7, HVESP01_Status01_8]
BO_ 2498860907 HVESP01_Status01_7: 8 HVESP01
 SG_ HVESP01_status01Crc_7 : 56|8@1+ (1,0) [0|255] "count"  HVESP01
 SG_ HVESP01_status01Counter_7 : 52|4@1+ (1,0) [0|15] ""  HVESP01
 SG_ HVESP01_operationalStatus_7 : 44|4@1+ (1,0) [0|15] ""  HVESP01
 SG_ HVESP01_hvBusConnectionStatus_7 : 40|4@1+ (1,0) [0|15] ""  HVESP01
 SG_ HVESP01_cellBalancingActive_7 : 30|2@1+ (1,0) [0|3] ""  HVESP01
 SG_ HVESP01_hvilStatus_7 : 20|2@1+ (1,0) [0|3] ""  HVESP01
 SG_ HVESP01_hvBusPassveIsoTestStatus_7 : 16|4@1+ (1,0) [0|15] ""  HVESP01
 SG_ HVESP01_hvBusActiveIsoTestStatus_7 : 12|4@1+ (1,0) [0|15] ""  HVESP01
 SG_ HVESP01_hvBusPrechgRelayState_7 : 8|2@1+ (1,0) [0|3] "V"  HVESP01
 SG_ HVESP01_hvBusNegContState_7 : 2|2@1+ (1,0) [0|3] "V"  HVESP01
 SG_ HVESP01_hvBusPosContState_7 : 0|2@1+ (1,0) [0|3] "V"  HVESP01

BO_ 2498860908 HVESP01_Status01_8: 8 HVESP01
 SG_ HVESP01_status01Crc_8 : 56|8@1+ (1,0) [0|255] "count"  HVESP01
 SG_ HVESP01_status01Counter_8 : 52|4@1+ (1,0) [0|15] ""  HVESP01
 SG_ HVESP01_operationalStatus_8 : 44|4@1+ (1,0) [0|15] ""  HVESP01
 SG_ HVESP01_hvBusConnectionStatus_8 : 40|4@1+ (1,0) [0|15] ""  HVESP01
 SG_ HVESP01_cellBalancingActive_8 : 30|2@1+ (1,0) [0|3] ""  HVESP01
 SG_ HVESP01_hvilStatus_8 : 20|2@1+ (1,0) [0|3] ""  HVESP01
 SG_ HVESP01_hvBusPassveIsoTestStatus_8 : 16|4@1+ (1,0) [0|15] ""  HVESP01
 SG_ HVESP01_hvBusActiveIsoTestStatus_8 : 12|4@1+ (1,0) [0|15] ""  HVESP01
 SG_ HVESP01_hvBusPrechgRelayState_8 : 8|2@1+ (1,0) [0|3] "V"  HVESP01
 SG_ HVESP01_hvBusNegContState_8 : 2|2@1+ (1,0) [0|3] "V"  HVESP01
 SG_ HVESP01_hvBusPosContState_8 : 0|2@1+ (1,0) [0|3] "V"  HVESP01

BO_ 2498861157 HVESP01_Data07_1: 8 HVESP01
 SG_ HVESP01_maxChargeVoltageLimit_1 : 48|16@1+ (0.05,0) [0|3212.75] "V"  HVESP01
 SG_ HVESP01_chargeEnergyCapacity_1 : 24|24@1+ (0.001,0) [0|16449.535] "kWh"  HVESP01
 SG_ HVESP01_dischargeEnergyCapacity_1 : 0|24@1+ (0.001,0) [0|16449.535] "kWh"  HVESP01

BO_ 2498861158 HVESP01_Data07_2: 8 HVESP01
 SG_ HVESP01_maxChargeVoltageLimit_2 : 48|16@1+ (0.05,0) [0|3212.75] "V"  HVESP01
 SG_ HVESP01_chargeEnergyCapacity_2 : 24|24@1+ (0.001,0) [0|16449.535] "kWh"  HVESP01
 SG_ HVESP01_dischargeEnergyCapacity_2 : 0|24@1+ (0.001,0) [0|16449.535] "kWh"  HVESP01

BO_ 2498861159 HVESP01_Data07_3: 8 HVESP01
 SG_ HVESP01_maxChargeVoltageLimit_3 : 48|16@1+ (0.05,0) [0|3212.75] "V"  HVESP01
 SG_ HVESP01_chargeEnergyCapacity_3 : 24|24@1+ (0.001,0) [0|16449.535] "kWh"  HVESP01
 SG_ HVESP01_dischargeEnergyCapacity_3 : 0|24@1+ (0.001,0) [0|16449.535] "kWh"  HVESP01

BO_ 2498861160 HVESP01_Data07_4: 8 HVESP01
 SG_ HVESP01_maxChargeVoltageLimit_4 : 48|16@1+ (0.05,0) [0|3212.75] "V"  HVESP01
 SG_ HVESP01_chargeEnergyCapacity_4 : 24|24@1+ (0.001,0) [0|16449.535] "kWh"  HVESP01
 SG_ HVESP01_dischargeEnergyCapacity_4 : 0|24@1+ (0.001,0) [0|16449.535] "kWh"  HVESP01

BO_ 2498861161 HVESP01_Data07_5: 8 HVESP01
 SG_ HVESP01_maxChargeVoltageLimit_5 : 48|16@1+ (0.05,0) [0|3212.75] "V"  HVESP01
 SG_ HVESP01_chargeEnergyCapacity_5 : 24|24@1+ (0.001,0) [0|16449.535] "kWh"  HVESP01
 SG_ HVESP01_dischargeEnergyCapacity_5 : 0|24@1+ (0.001,0) [0|16449.535] "kWh"  HVESP01

BO_ 2498861162 HVESP01_Data07_6: 8 HVESP01
 SG_ HVESP01_maxChargeVoltageLimit_6 : 48|16@1+ (0.05,0) [0|3212.75] "V"  HVESP01
 SG_ HVESP01_chargeEnergyCapacity_6 : 24|24@1+ (0.001,0) [0|16449.535] "kWh"  HVESP01
 SG_ HVESP01_dischargeEnergyCapacity_6 : 0|24@1+ (0.001,0) [0|16449.535] "kWh"  HVESP01

BO_ 2498861163 HVESP01_Data07_7: 8 HVESP01
 SG_ HVESP01_maxChargeVoltageLimit_7 : 48|16@1+ (0.05,0) [0|3212.75] "V"  HVESP01
 SG_ HVESP01_chargeEnergyCapacity_7 : 24|24@1+ (0.001,0) [0|16449.535] "kWh"  HVESP01
 SG_ HVESP01_dischargeEnergyCapacity_7 : 0|24@1+ (0.001,0) [0|16449.535] "kWh"  HVESP01

BO_ 2498861164 HVESP01_Data07_8: 8 HVESP01
 SG_ HVESP01_maxChargeVoltageLimit_8 : 48|16@1+ (0.05,0) [0|3212.75] "V"  HVESP01
 SG_ HVESP01_chargeEnergyCapacity_8 : 24|24@1+ (0.001,0) [0|16449.535] "kWh"  HVESP01
 SG_ HVESP01_dischargeEnergyCapacity_8 : 0|24@1+ (0.001,0) [0|16449.535] "kWh"  HVESP01

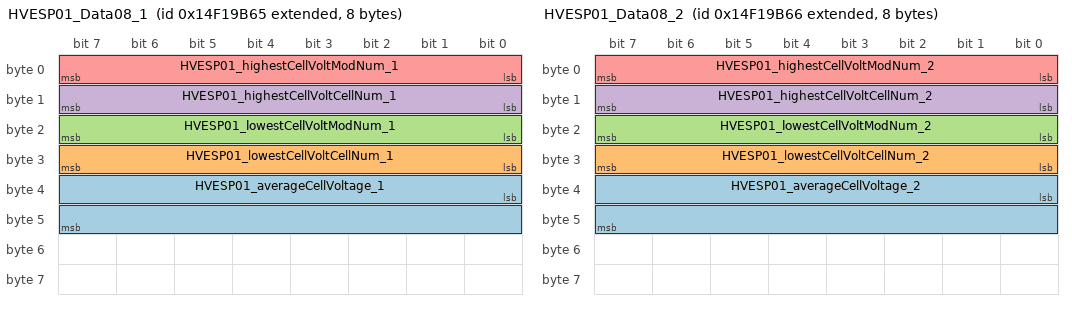
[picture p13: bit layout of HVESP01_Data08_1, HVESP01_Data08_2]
BO_ 2498861925 HVESP01_Data08_1: 8 HVESP01
 SG_ HVESP01_averageCellVoltage_1 : 32|16@1+ (0.001,0) [0|64.255] "V"  HVESP01
 SG_ HVESP01_lowestCellVoltCellNum_1 : 24|8@1+ (1,0) [0|250] "count"  HVESP01
 SG_ HVESP01_lowestCellVoltModNum_1 : 16|8@1+ (1,0) [0|250] "count"  HVESP01
 SG_ HVESP01_highestCellVoltCellNum_1 : 8|8@1+ (1,0) [0|250] "count"  HVESP01
 SG_ HVESP01_highestCellVoltModNum_1 : 0|8@1+ (1,0) [0|250] "count"  HVESP01

BO_ 2498861926 HVESP01_Data08_2: 8 HVESP01
 SG_ HVESP01_averageCellVoltage_2 : 32|16@1+ (0.001,0) [0|64.255] "V"  HVESP01
 SG_ HVESP01_lowestCellVoltCellNum_2 : 24|8@1+ (1,0) [0|250] "count"  HVESP01
 SG_ HVESP01_lowestCellVoltModNum_2 : 16|8@1+ (1,0) [0|250] "count"  HVESP01
 SG_ HVESP01_highestCellVoltCellNum_2 : 8|8@1+ (1,0) [0|250] "count"  HVESP01
 SG_ HVESP01_highestCellVoltModNum_2 : 0|8@1+ (1,0) [0|250] "count"  HVESP01

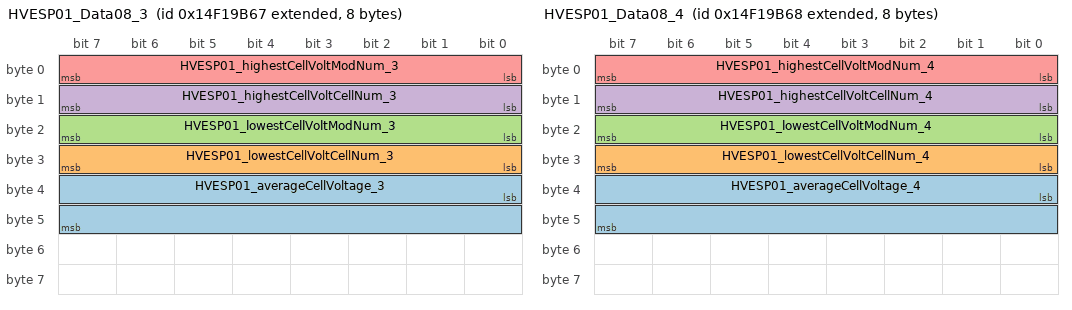
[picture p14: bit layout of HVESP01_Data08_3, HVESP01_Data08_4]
BO_ 2498861927 HVESP01_Data08_3: 8 HVESP01
 SG_ HVESP01_averageCellVoltage_3 : 32|16@1+ (0.001,0) [0|64.255] "V"  HVESP01
 SG_ HVESP01_lowestCellVoltCellNum_3 : 24|8@1+ (1,0) [0|250] "count"  HVESP01
 SG_ HVESP01_lowestCellVoltModNum_3 : 16|8@1+ (1,0) [0|250] "count"  HVESP01
 SG_ HVESP01_highestCellVoltCellNum_3 : 8|8@1+ (1,0) [0|250] "count"  HVESP01
 SG_ HVESP01_highestCellVoltModNum_3 : 0|8@1+ (1,0) [0|250] "count"  HVESP01

BO_ 2498861928 HVESP01_Data08_4: 8 HVESP01
 SG_ HVESP01_averageCellVoltage_4 : 32|16@1+ (0.001,0) [0|64.255] "V"  HVESP01
 SG_ HVESP01_lowestCellVoltCellNum_4 : 24|8@1+ (1,0) [0|250] "count"  HVESP01
 SG_ HVESP01_lowestCellVoltModNum_4 : 16|8@1+ (1,0) [0|250] "count"  HVESP01
 SG_ HVESP01_highestCellVoltCellNum_4 : 8|8@1+ (1,0) [0|250] "count"  HVESP01
 SG_ HVESP01_highestCellVoltModNum_4 : 0|8@1+ (1,0) [0|250] "count"  HVESP01

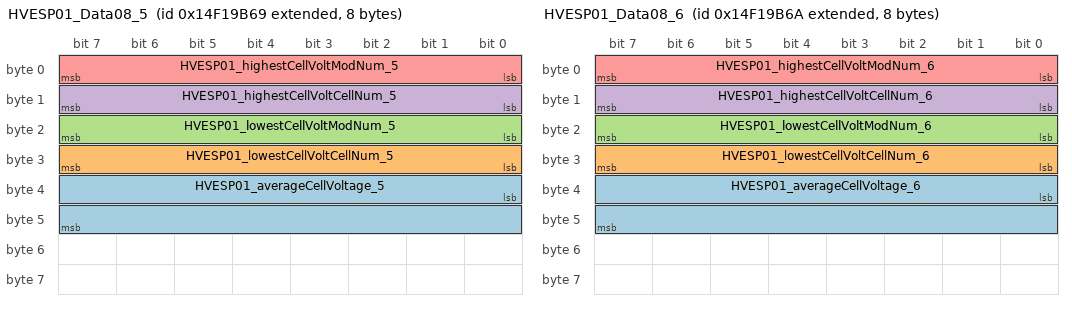
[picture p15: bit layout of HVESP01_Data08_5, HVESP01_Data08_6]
BO_ 2498861929 HVESP01_Data08_5: 8 HVESP01
 SG_ HVESP01_averageCellVoltage_5 : 32|16@1+ (0.001,0) [0|64.255] "V"  HVESP01
 SG_ HVESP01_lowestCellVoltCellNum_5 : 24|8@1+ (1,0) [0|250] "count"  HVESP01
 SG_ HVESP01_lowestCellVoltModNum_5 : 16|8@1+ (1,0) [0|250] "count"  HVESP01
 SG_ HVESP01_highestCellVoltCellNum_5 : 8|8@1+ (1,0) [0|250] "count"  HVESP01
 SG_ HVESP01_highestCellVoltModNum_5 : 0|8@1+ (1,0) [0|250] "count"  HVESP01

BO_ 2498861930 HVESP01_Data08_6: 8 HVESP01
 SG_ HVESP01_averageCellVoltage_6 : 32|16@1+ (0.001,0) [0|64.255] "V"  HVESP01
 SG_ HVESP01_lowestCellVoltCellNum_6 : 24|8@1+ (1,0) [0|250] "count"  HVESP01
 SG_ HVESP01_lowestCellVoltModNum_6 : 16|8@1+ (1,0) [0|250] "count"  HVESP01
 SG_ HVESP01_highestCellVoltCellNum_6 : 8|8@1+ (1,0) [0|250] "count"  HVESP01
 SG_ HVESP01_highestCellVoltModNum_6 : 0|8@1+ (1,0) [0|250] "count"  HVESP01

BO_ 2498861931 HVESP01_Data08_7: 8 HVESP01
 SG_ HVESP01_averageCellVoltage_7 : 32|16@1+ (0.001,0) [0|64.255] "V"  HVESP01
 SG_ HVESP01_lowestCellVoltCellNum_7 : 24|8@1+ (1,0) [0|250] "count"  HVESP01
 SG_ HVESP01_lowestCellVoltModNum_7 : 16|8@1+ (1,0) [0|250] "count"  HVESP01
 SG_ HVESP01_highestCellVoltCellNum_7 : 8|8@1+ (1,0) [0|250] "count"  HVESP01
 SG_ HVESP01_highestCellVoltModNum_7 : 0|8@1+ (1,0) [0|250] "count"  HVESP01

BO_ 2498861932 HVESP01_Data08_8: 8 HVESP01
 SG_ HVESP01_averageCellVoltage_8 : 32|16@1+ (0.001,0) [0|64.255] "V"  HVESP01
 SG_ HVESP01_lowestCellVoltCellNum_8 : 24|8@1+ (1,0) [0|250] "count"  HVESP01
 SG_ HVESP01_lowestCellVoltModNum_8 : 16|8@1+ (1,0) [0|250] "count"  HVESP01
 SG_ HVESP01_highestCellVoltCellNum_8 : 8|8@1+ (1,0) [0|250] "count"  HVESP01
 SG_ HVESP01_highestCellVoltModNum_8 : 0|8@1+ (1,0) [0|250] "count"  HVESP01

BO_ 2498862181 HVESP01_Data09_1: 8 HVESP01
 SG_ HVESP01_lowestCellTempModNum_1 : 16|8@1+ (1,0) [0|250] "count"  HVESP01
 SG_ HVESP01_highestCellTempModNum_1 : 0|8@1+ (1,0) [0|250] "count"  HVESP01

BO_ 2498862182 HVESP01_Data09_2: 8 HVESP01
 SG_ HVESP01_lowestCellTempModNum_2 : 16|8@1+ (1,0) [0|250] "count"  HVESP01
 SG_ HVESP01_highestCellTempModNum_2 : 0|8@1+ (1,0) [0|250] "count"  HVESP01

BO_ 2498862183 HVESP01_Data09_3: 8 HVESP01
 SG_ HVESP01_lowestCellTempModNum_3 : 16|8@1+ (1,0) [0|250] "count"  HVESP01
 SG_ HVESP01_highestCellTempModNum_3 : 0|8@1+ (1,0) [0|250] "count"  HVESP01

BO_ 2498862184 HVESP01_Data09_4: 8 HVESP01
 SG_ HVESP01_lowestCellTempModNum_4 : 16|8@1+ (1,0) [0|250] "count"  HVESP01
 SG_ HVESP01_highestCellTempModNum_4 : 0|8@1+ (1,0) [0|250] "count"  HVESP01

BO_ 2498862185 HVESP01_Data09_5: 8 HVESP01
 SG_ HVESP01_lowestCellTempModNum_5 : 16|8@1+ (1,0) [0|250] "count"  HVESP01
 SG_ HVESP01_highestCellTempModNum_5 : 0|8@1+ (1,0) [0|250] "count"  HVESP01

BO_ 2498862186 HVESP01_Data09_6: 8 HVESP01
 SG_ HVESP01_lowestCellTempModNum_6 : 16|8@1+ (1,0) [0|250] "count"  HVESP01
 SG_ HVESP01_highestCellTempModNum_6 : 0|8@1+ (1,0) [0|250] "count"  HVESP01

BO_ 2498862187 HVESP01_Data09_7: 8 HVESP01
 SG_ HVESP01_lowestCellTempModNum_7 : 16|8@1+ (1,0) [0|250] "count"  HVESP01
 SG_ HVESP01_highestCellTempModNum_7 : 0|8@1+ (1,0) [0|250] "count"  HVESP01

BO_ 2498862188 HVESP01_Data09_8: 8 HVESP01
 SG_ HVESP01_lowestCellTempModNum_8 : 16|8@1+ (1,0) [0|250] "count"  HVESP01
 SG_ HVESP01_highestCellTempModNum_8 : 0|8@1+ (1,0) [0|250] "count"  HVESP01

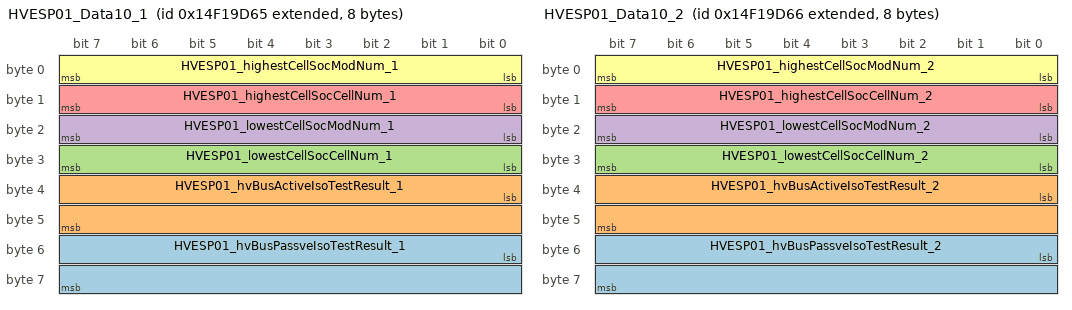
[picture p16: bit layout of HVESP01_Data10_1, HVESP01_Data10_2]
BO_ 2498862437 HVESP01_Data10_1: 8 HVESP01
 SG_ HVESP01_hvBusPassveIsoTestResult_1 : 48|16@1+ (0.1,0) [0|6425.5] "ohm per V"  HVESP01
 SG_ HVESP01_hvBusActiveIsoTestResult_1 : 32|16@1+ (0.1,0) [0|6425.5] "ohm per V"  HVESP01
 SG_ HVESP01_lowestCellSocCellNum_1 : 24|8@1+ (1,0) [0|250] "count"  HVESP01
 SG_ HVESP01_lowestCellSocModNum_1 : 16|8@1+ (1,0) [0|250] "count"  HVESP01
 SG_ HVESP01_highestCellSocCellNum_1 : 8|8@1+ (1,0) [0|250] "count"  HVESP01
 SG_ HVESP01_highestCellSocModNum_1 : 0|8@1+ (1,0) [0|250] "count"  HVESP01

BO_ 2498862438 HVESP01_Data10_2: 8 HVESP01
 SG_ HVESP01_hvBusPassveIsoTestResult_2 : 48|16@1+ (0.1,0) [0|6425.5] "ohm per V"  HVESP01
 SG_ HVESP01_hvBusActiveIsoTestResult_2 : 32|16@1+ (0.1,0) [0|6425.5] "ohm per V"  HVESP01
 SG_ HVESP01_lowestCellSocCellNum_2 : 24|8@1+ (1,0) [0|250] "count"  HVESP01
 SG_ HVESP01_lowestCellSocModNum_2 : 16|8@1+ (1,0) [0|250] "count"  HVESP01
 SG_ HVESP01_highestCellSocCellNum_2 : 8|8@1+ (1,0) [0|250] "count"  HVESP01
 SG_ HVESP01_highestCellSocModNum_2 : 0|8@1+ (1,0) [0|250] "count"  HVESP01

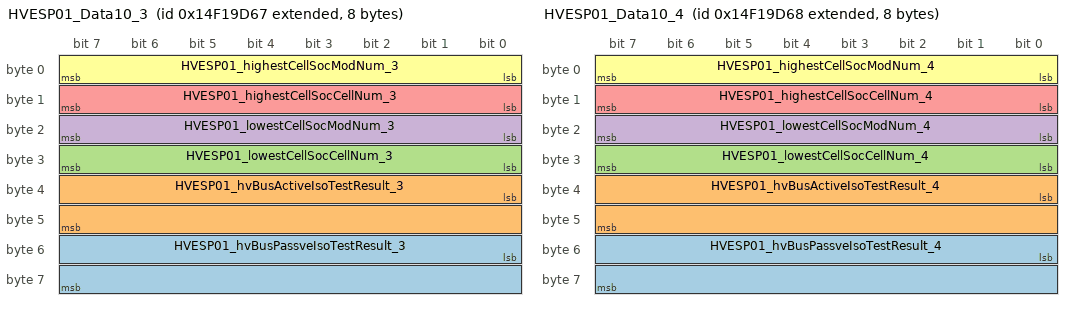
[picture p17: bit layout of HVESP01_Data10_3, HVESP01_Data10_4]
BO_ 2498862439 HVESP01_Data10_3: 8 HVESP01
 SG_ HVESP01_hvBusPassveIsoTestResult_3 : 48|16@1+ (0.1,0) [0|6425.5] "ohm per V"  HVESP01
 SG_ HVESP01_hvBusActiveIsoTestResult_3 : 32|16@1+ (0.1,0) [0|6425.5] "ohm per V"  HVESP01
 SG_ HVESP01_lowestCellSocCellNum_3 : 24|8@1+ (1,0) [0|250] "count"  HVESP01
 SG_ HVESP01_lowestCellSocModNum_3 : 16|8@1+ (1,0) [0|250] "count"  HVESP01
 SG_ HVESP01_highestCellSocCellNum_3 : 8|8@1+ (1,0) [0|250] "count"  HVESP01
 SG_ HVESP01_highestCellSocModNum_3 : 0|8@1+ (1,0) [0|250] "count"  HVESP01

BO_ 2498862440 HVESP01_Data10_4: 8 HVESP01
 SG_ HVESP01_hvBusPassveIsoTestResult_4 : 48|16@1+ (0.1,0) [0|6425.5] "ohm per V"  HVESP01
 SG_ HVESP01_hvBusActiveIsoTestResult_4 : 32|16@1+ (0.1,0) [0|6425.5] "ohm per V"  HVESP01
 SG_ HVESP01_lowestCellSocCellNum_4 : 24|8@1+ (1,0) [0|250] "count"  HVESP01
 SG_ HVESP01_lowestCellSocModNum_4 : 16|8@1+ (1,0) [0|250] "count"  HVESP01
 SG_ HVESP01_highestCellSocCellNum_4 : 8|8@1+ (1,0) [0|250] "count"  HVESP01
 SG_ HVESP01_highestCellSocModNum_4 : 0|8@1+ (1,0) [0|250] "count"  HVESP01

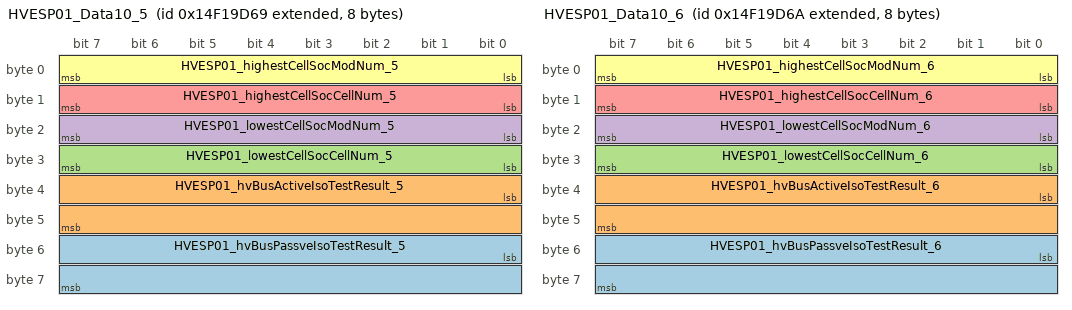
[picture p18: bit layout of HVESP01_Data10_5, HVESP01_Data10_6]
BO_ 2498862441 HVESP01_Data10_5: 8 HVESP01
 SG_ HVESP01_hvBusPassveIsoTestResult_5 : 48|16@1+ (0.1,0) [0|6425.5] "ohm per V"  HVESP01
 SG_ HVESP01_hvBusActiveIsoTestResult_5 : 32|16@1+ (0.1,0) [0|6425.5] "ohm per V"  HVESP01
 SG_ HVESP01_lowestCellSocCellNum_5 : 24|8@1+ (1,0) [0|250] "count"  HVESP01
 SG_ HVESP01_lowestCellSocModNum_5 : 16|8@1+ (1,0) [0|250] "count"  HVESP01
 SG_ HVESP01_highestCellSocCellNum_5 : 8|8@1+ (1,0) [0|250] "count"  HVESP01
 SG_ HVESP01_highestCellSocModNum_5 : 0|8@1+ (1,0) [0|250] "count"  HVESP01

BO_ 2498862442 HVESP01_Data10_6: 8 HVESP01
 SG_ HVESP01_hvBusPassveIsoTestResult_6 : 48|16@1+ (0.1,0) [0|6425.5] "ohm per V"  HVESP01
 SG_ HVESP01_hvBusActiveIsoTestResult_6 : 32|16@1+ (0.1,0) [0|6425.5] "ohm per V"  HVESP01
 SG_ HVESP01_lowestCellSocCellNum_6 : 24|8@1+ (1,0) [0|250] "count"  HVESP01
 SG_ HVESP01_lowestCellSocModNum_6 : 16|8@1+ (1,0) [0|250] "count"  HVESP01
 SG_ HVESP01_highestCellSocCellNum_6 : 8|8@1+ (1,0) [0|250] "count"  HVESP01
 SG_ HVESP01_highestCellSocModNum_6 : 0|8@1+ (1,0) [0|250] "count"  HVESP01

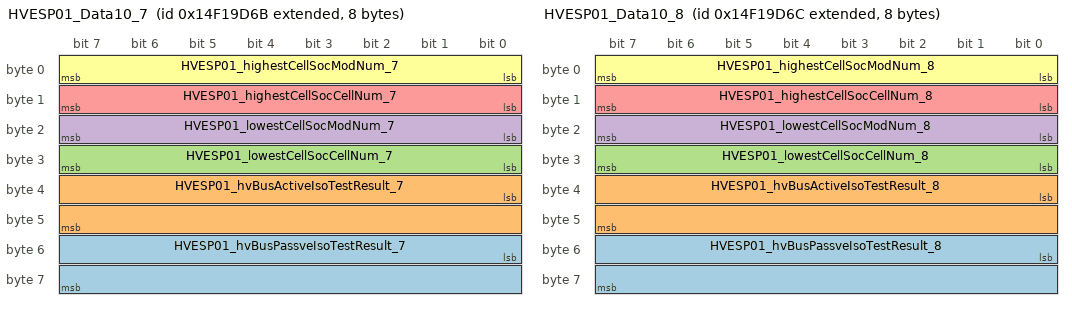
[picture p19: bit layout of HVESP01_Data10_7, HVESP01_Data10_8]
BO_ 2498862443 HVESP01_Data10_7: 8 HVESP01
 SG_ HVESP01_hvBusPassveIsoTestResult_7 : 48|16@1+ (0.1,0) [0|6425.5] "ohm per V"  HVESP01
 SG_ HVESP01_hvBusActiveIsoTestResult_7 : 32|16@1+ (0.1,0) [0|6425.5] "ohm per V"  HVESP01
 SG_ HVESP01_lowestCellSocCellNum_7 : 24|8@1+ (1,0) [0|250] "count"  HVESP01
 SG_ HVESP01_lowestCellSocModNum_7 : 16|8@1+ (1,0) [0|250] "count"  HVESP01
 SG_ HVESP01_highestCellSocCellNum_7 : 8|8@1+ (1,0) [0|250] "count"  HVESP01
 SG_ HVESP01_highestCellSocModNum_7 : 0|8@1+ (1,0) [0|250] "count"  HVESP01

BO_ 2498862444 HVESP01_Data10_8: 8 HVESP01
 SG_ HVESP01_hvBusPassveIsoTestResult_8 : 48|16@1+ (0.1,0) [0|6425.5] "ohm per V"  HVESP01
 SG_ HVESP01_hvBusActiveIsoTestResult_8 : 32|16@1+ (0.1,0) [0|6425.5] "ohm per V"  HVESP01
 SG_ HVESP01_lowestCellSocCellNum_8 : 24|8@1+ (1,0) [0|250] "count"  HVESP01
 SG_ HVESP01_lowestCellSocModNum_8 : 16|8@1+ (1,0) [0|250] "count"  HVESP01
 SG_ HVESP01_highestCellSocCellNum_8 : 8|8@1+ (1,0) [0|250] "count"  HVESP01
 SG_ HVESP01_highestCellSocModNum_8 : 0|8@1+ (1,0) [0|250] "count"  HVESP01

BO_ 2499500389 HVESP01_History_1: 8 HVESP01
 SG_ HVESP01_lowestCellSohcCellNum_1 : 16|8@1+ (1,0) [0|255] "count"  HVESP01
 SG_ HVESP01_highestCellSohcCellNum_1 : 8|8@1+ (1,0) [0|255] "count"  HVESP01
 SG_ HVESP01_stateOfHealth_1 : 0|8@1+ (0.4,0) [0|100] "%"  HVESP01

BO_ 2499500390 HVESP01_History_2: 8 HVESP01
 SG_ HVESP01_lowestCellSohcCellNum_2 : 16|8@1+ (1,0) [0|255] "count"  HVESP01
 SG_ HVESP01_highestCellSohcCellNum_2 : 8|8@1+ (1,0) [0|255] "count"  HVESP01
 SG_ HVESP01_stateOfHealth_2 : 0|8@1+ (0.4,0) [0|100] "%"  HVESP01

BO_ 2499500391 HVESP01_History_3: 8 HVESP01
 SG_ HVESP01_lowestCellSohcCellNum_3 : 16|8@1+ (1,0) [0|255] "count"  HVESP01
 SG_ HVESP01_highestCellSohcCellNum_3 : 8|8@1+ (1,0) [0|255] "count"  HVESP01
 SG_ HVESP01_stateOfHealth_3 : 0|8@1+ (0.4,0) [0|100] "%"  HVESP01

BO_ 2499500392 HVESP01_History_4: 8 HVESP01
 SG_ HVESP01_lowestCellSohcCellNum_4 : 16|8@1+ (1,0) [0|255] "count"  HVESP01
 SG_ HVESP01_highestCellSohcCellNum_4 : 8|8@1+ (1,0) [0|255] "count"  HVESP01
 SG_ HVESP01_stateOfHealth_4 : 0|8@1+ (0.4,0) [0|100] "%"  HVESP01

BO_ 2499500393 HVESP01_History_5: 8 HVESP01
 SG_ HVESP01_lowestCellSohcCellNum_5 : 16|8@1+ (1,0) [0|255] "count"  HVESP01
 SG_ HVESP01_highestCellSohcCellNum_5 : 8|8@1+ (1,0) [0|255] "count"  HVESP01
 SG_ HVESP01_stateOfHealth_5 : 0|8@1+ (0.4,0) [0|100] "%"  HVESP01

BO_ 2499500394 HVESP01_History_6: 8 HVESP01
 SG_ HVESP01_lowestCellSohcCellNum_6 : 16|8@1+ (1,0) [0|255] "count"  HVESP01
 SG_ HVESP01_highestCellSohcCellNum_6 : 8|8@1+ (1,0) [0|255] "count"  HVESP01
 SG_ HVESP01_stateOfHealth_6 : 0|8@1+ (0.4,0) [0|100] "%"  HVESP01

BO_ 2499500395 HVESP01_History_7: 8 HVESP01
 SG_ HVESP01_lowestCellSohcCellNum_7 : 16|8@1+ (1,0) [0|255] "count"  HVESP01
 SG_ HVESP01_highestCellSohcCellNum_7 : 8|8@1+ (1,0) [0|255] "count"  HVESP01
 SG_ HVESP01_stateOfHealth_7 : 0|8@1+ (0.4,0) [0|100] "%"  HVESP01

BO_ 2499500396 HVESP01_History_8: 8 HVESP01
 SG_ HVESP01_lowestCellSohcCellNum_8 : 16|8@1+ (1,0) [0|255] "count"  HVESP01
 SG_ HVESP01_highestCellSohcCellNum_8 : 8|8@1+ (1,0) [0|255] "count"  HVESP01
 SG_ HVESP01_stateOfHealth_8 : 0|8@1+ (0.4,0) [0|100] "%"  HVESP01

BO_ 2499739749 HVESP01_HVIL_1: 8 HVESP01
 SG_ HVESP01_hvilSinkCrrnt_1 : 24|6@1+ (1,0) [0|50] "mA"  HVESP01
 SG_ HVESP01_hvilSourceVolt_1 : 8|6@1+ (0.1,0) [0|6.3] "Volts"  HVESP01
 SG_ HVESP01_hvilSourceCurrent_1 : 16|5@1+ (1,0) [0|29] "mA"  HVESP01

BO_ 2499739750 HVESP01_HVIL_2: 8 HVESP01
 SG_ HVESP01_hvilSinkCrrnt_2 : 24|6@1+ (1,0) [0|50] "mA"  HVESP01
 SG_ HVESP01_hvilSourceVolt_2 : 8|6@1+ (0.1,0) [0|6.3] "Volts"  HVESP01
 SG_ HVESP01_hvilSourceCurrent_2 : 16|5@1+ (1,0) [0|29] "mA"  HVESP01

BO_ 2499739751 HVESP01_HVIL_3: 8 HVESP01
 SG_ HVESP01_hvilSinkCrrnt_3 : 24|6@1+ (1,0) [0|50] "mA"  HVESP01
 SG_ HVESP01_hvilSourceVolt_3 : 8|6@1+ (0.1,0) [0|6.3] "Volts"  HVESP01
 SG_ HVESP01_hvilSourceCurrent_3 : 16|5@1+ (1,0) [0|29] "mA"  HVESP01

BO_ 2499739752 HVESP01_HVIL_4: 8 HVESP01
 SG_ HVESP01_hvilSinkCrrnt_4 : 24|6@1+ (1,0) [0|50] "mA"  HVESP01
 SG_ HVESP01_hvilSourceVolt_4 : 8|6@1+ (0.1,0) [0|6.3] "Volts"  HVESP01
 SG_ HVESP01_hvilSourceCurrent_4 : 16|5@1+ (1,0) [0|29] "mA"  HVESP01

BO_ 2499739753 HVESP01_HVIL_5: 8 HVESP01
 SG_ HVESP01_hvilSinkCrrnt_5 : 24|6@1+ (1,0) [0|50] "mA"  HVESP01
 SG_ HVESP01_hvilSourceVolt_5 : 8|6@1+ (0.1,0) [0|6.3] "Volts"  HVESP01
 SG_ HVESP01_hvilSourceCurrent_5 : 16|5@1+ (1,0) [0|29] "mA"  HVESP01

BO_ 2499739754 HVESP01_HVIL_6: 8 HVESP01
 SG_ HVESP01_hvilSinkCrrnt_6 : 24|6@1+ (1,0) [0|50] "mA"  HVESP01
 SG_ HVESP01_hvilSourceVolt_6 : 8|6@1+ (0.1,0) [0|6.3] "Volts"  HVESP01
 SG_ HVESP01_hvilSourceCurrent_6 : 16|5@1+ (1,0) [0|29] "mA"  HVESP01

BO_ 2499739755 HVESP01_HVIL_7: 8 HVESP01
 SG_ HVESP01_hvilSinkCrrnt_7 : 24|6@1+ (1,0) [0|50] "mA"  HVESP01
 SG_ HVESP01_hvilSourceVolt_7 : 8|6@1+ (0.1,0) [0|6.3] "Volts"  HVESP01
 SG_ HVESP01_hvilSourceCurrent_7 : 16|5@1+ (1,0) [0|29] "mA"  HVESP01

BO_ 2499739756 HVESP01_HVIL_8: 8 HVESP01
 SG_ HVESP01_hvilSinkCrrnt_8 : 24|6@1+ (1,0) [0|50] "mA"  HVESP01
 SG_ HVESP01_hvilSourceVolt_8 : 8|6@1+ (0.1,0) [0|6.3] "Volts"  HVESP01
 SG_ HVESP01_hvilSourceCurrent_8 : 16|5@1+ (1,0) [0|29] "mA"  HVESP01

BO_ 2499740005 HVESP01_LimitsDischarge_1: 8 HVESP01
 SG_ HVESP01_LimitDschrgPwrLongTerm_1 : 48|12@1+ (1,0) [0|4095] "kW"  HVESP01
 SG_ HVESP01_LimitDschrgPwrShortTerm_1 : 16|12@1+ (1,0) [0|4095] "kW"  HVESP01
 SG_ HVESP01_LimitDschrgPwrMidTerm_1 : 32|12@1+ (1,0) [0|4095] "kW"  HVESP01

BO_ 2499740006 HVESP01_LimitsDischarge_2: 8 HVESP01
 SG_ HVESP01_LimitDschrgPwrLongTerm_2 : 48|12@1+ (1,0) [0|4095] "kW"  HVESP01
 SG_ HVESP01_LimitDschrgPwrShortTerm_2 : 16|12@1+ (1,0) [0|4095] "kW"  HVESP01
 SG_ HVESP01_LimitDschrgPwrMidTerm_2 : 32|12@1+ (1,0) [0|4095] "kW"  HVESP01

BO_ 2499740007 HVESP01_LimitsDischarge_3: 8 HVESP01
 SG_ HVESP01_LimitDschrgPwrLongTerm_3 : 48|12@1+ (1,0) [0|4095] "kW"  HVESP01
 SG_ HVESP01_LimitDschrgPwrShortTerm_3 : 16|12@1+ (1,0) [0|4095] "kW"  HVESP01
 SG_ HVESP01_LimitDschrgPwrMidTerm_3 : 32|12@1+ (1,0) [0|4095] "kW"  HVESP01

BO_ 2499740008 HVESP01_LimitsDischarge_4: 8 HVESP01
 SG_ HVESP01_LimitDschrgPwrLongTerm_4 : 48|12@1+ (1,0) [0|4095] "kW"  HVESP01
 SG_ HVESP01_LimitDschrgPwrShortTerm_4 : 16|12@1+ (1,0) [0|4095] "kW"  HVESP01
 SG_ HVESP01_LimitDschrgPwrMidTerm_4 : 32|12@1+ (1,0) [0|4095] "kW"  HVESP01

BO_ 2499740009 HVESP01_LimitsDischarge_5: 8 HVESP01
 SG_ HVESP01_LimitDschrgPwrLongTerm_5 : 48|12@1+ (1,0) [0|4095] "kW"  HVESP01
 SG_ HVESP01_LimitDschrgPwrShortTerm_5 : 16|12@1+ (1,0) [0|4095] "kW"  HVESP01
 SG_ HVESP01_LimitDschrgPwrMidTerm_5 : 32|12@1+ (1,0) [0|4095] "kW"  HVESP01

BO_ 2499740010 HVESP01_LimitsDischarge_6: 8 HVESP01
 SG_ HVESP01_LimitDschrgPwrLongTerm_6 : 48|12@1+ (1,0) [0|4095] "kW"  HVESP01
 SG_ HVESP01_LimitDschrgPwrShortTerm_6 : 16|12@1+ (1,0) [0|4095] "kW"  HVESP01
 SG_ HVESP01_LimitDschrgPwrMidTerm_6 : 32|12@1+ (1,0) [0|4095] "kW"  HVESP01

BO_ 2499740011 HVESP01_LimitsDischarge_7: 8 HVESP01
 SG_ HVESP01_LimitDschrgPwrLongTerm_7 : 48|12@1+ (1,0) [0|4095] "kW"  HVESP01
 SG_ HVESP01_LimitDschrgPwrShortTerm_7 : 16|12@1+ (1,0) [0|4095] "kW"  HVESP01
 SG_ HVESP01_LimitDschrgPwrMidTerm_7 : 32|12@1+ (1,0) [0|4095] "kW"  HVESP01

BO_ 2499740012 HVESP01_LimitsDischarge_8: 8 HVESP01
 SG_ HVESP01_LimitDschrgPwrLongTerm_8 : 48|12@1+ (1,0) [0|4095] "kW"  HVESP01
 SG_ HVESP01_LimitDschrgPwrShortTerm_8 : 16|12@1+ (1,0) [0|4095] "kW"  HVESP01
 SG_ HVESP01_LimitDschrgPwrMidTerm_8 : 32|12@1+ (1,0) [0|4095] "kW"  HVESP01

BO_ 2499740261 HVESP01_LimitsRegen_1: 8 HVESP01
 SG_ HVESP01_LimitRegenPwrLongTerm_1 : 48|12@1+ (1,0) [0|4095] "kW"  HVESP01
 SG_ HVESP01_LimitRegenPwrMidTerm_1 : 32|12@1+ (1,0) [0|4095] "kW"  HVESP01
 SG_ HVESP01_LimitRegenPwrShortTerm_1 : 16|12@1+ (1,0) [0|4095] "kW"  HVESP01

BO_ 2499740262 HVESP01_LimitsRegen_2: 8 HVESP01
 SG_ HVESP01_LimitRegenPwrLongTerm_2 : 48|12@1+ (1,0) [0|4095] "kW"  HVESP01
 SG_ HVESP01_LimitRegenPwrMidTerm_2 : 32|12@1+ (1,0) [0|4095] "kW"  HVESP01
 SG_ HVESP01_LimitRegenPwrShortTerm_2 : 16|12@1+ (1,0) [0|4095] "kW"  HVESP01

BO_ 2499740263 HVESP01_LimitsRegen_3: 8 HVESP01
 SG_ HVESP01_LimitRegenPwrLongTerm_3 : 48|12@1+ (1,0) [0|4095] "kW"  HVESP01
 SG_ HVESP01_LimitRegenPwrMidTerm_3 : 32|12@1+ (1,0) [0|4095] "kW"  HVESP01
 SG_ HVESP01_LimitRegenPwrShortTerm_3 : 16|12@1+ (1,0) [0|4095] "kW"  HVESP01

BO_ 2499740264 HVESP01_LimitsRegen_4: 8 HVESP01
 SG_ HVESP01_LimitRegenPwrLongTerm_4 : 48|12@1+ (1,0) [0|4095] "kW"  HVESP01
 SG_ HVESP01_LimitRegenPwrMidTerm_4 : 32|12@1+ (1,0) [0|4095] "kW"  HVESP01
 SG_ HVESP01_LimitRegenPwrShortTerm_4 : 16|12@1+ (1,0) [0|4095] "kW"  HVESP01

BO_ 2499740265 HVESP01_LimitsRegen_5: 8 HVESP01
 SG_ HVESP01_LimitRegenPwrLongTerm_5 : 48|12@1+ (1,0) [0|4095] "kW"  HVESP01
 SG_ HVESP01_LimitRegenPwrMidTerm_5 : 32|12@1+ (1,0) [0|4095] "kW"  HVESP01
 SG_ HVESP01_LimitRegenPwrShortTerm_5 : 16|12@1+ (1,0) [0|4095] "kW"  HVESP01

BO_ 2499740266 HVESP01_LimitsRegen_6: 8 HVESP01
 SG_ HVESP01_LimitRegenPwrLongTerm_6 : 48|12@1+ (1,0) [0|4095] "kW"  HVESP01
 SG_ HVESP01_LimitRegenPwrMidTerm_6 : 32|12@1+ (1,0) [0|4095] "kW"  HVESP01
 SG_ HVESP01_LimitRegenPwrShortTerm_6 : 16|12@1+ (1,0) [0|4095] "kW"  HVESP01

BO_ 2499740267 HVESP01_LimitsRegen_7: 8 HVESP01
 SG_ HVESP01_LimitRegenPwrLongTerm_7 : 48|12@1+ (1,0) [0|4095] "kW"  HVESP01
 SG_ HVESP01_LimitRegenPwrMidTerm_7 : 32|12@1+ (1,0) [0|4095] "kW"  HVESP01
 SG_ HVESP01_LimitRegenPwrShortTerm_7 : 16|12@1+ (1,0) [0|4095] "kW"  HVESP01

BO_ 2499740268 HVESP01_LimitsRegen_8: 8 HVESP01
 SG_ HVESP01_LimitRegenPwrLongTerm_8 : 48|12@1+ (1,0) [0|4095] "kW"  HVESP01
 SG_ HVESP01_LimitRegenPwrMidTerm_8 : 32|12@1+ (1,0) [0|4095] "kW"  HVESP01
 SG_ HVESP01_LimitRegenPwrShortTerm_8 : 16|12@1+ (1,0) [0|4095] "kW"  HVESP01

BO_ 2499740517 HVESP01_Sohr_1: 8 HVESP01
 SG_ HVESP01_packSOHR_1 : 32|8@1+ (0.4,0) [0|100] "%"  HVESP01
 SG_ HVESP01_lowestCellSohrCellNum_1 : 24|8@1+ (1,0) [0|250] "count"  HVESP01

BO_ 2499740518 HVESP01_Sohr_2: 8 HVESP01
 SG_ HVESP01_packSOHR_2 : 32|8@1+ (0.4,0) [0|100] "%"  HVESP01
 SG_ HVESP01_lowestCellSohrCellNum_2 : 24|8@1+ (1,0) [0|250] "count"  HVESP01

BO_ 2499740519 HVESP01_Sohr_3: 8 HVESP01
 SG_ HVESP01_packSOHR_3 : 32|8@1+ (0.4,0) [0|100] "%"  HVESP01
 SG_ HVESP01_lowestCellSohrCellNum_3 : 24|8@1+ (1,0) [0|250] "count"  HVESP01

BO_ 2499740520 HVESP01_Sohr_4: 8 HVESP01
 SG_ HVESP01_packSOHR_4 : 32|8@1+ (0.4,0) [0|100] "%"  HVESP01
 SG_ HVESP01_lowestCellSohrCellNum_4 : 24|8@1+ (1,0) [0|250] "count"  HVESP01

BO_ 2499740521 HVESP01_Sohr_5: 8 HVESP01
 SG_ HVESP01_packSOHR_5 : 32|8@1+ (0.4,0) [0|100] "%"  HVESP01
 SG_ HVESP01_lowestCellSohrCellNum_5 : 24|8@1+ (1,0) [0|250] "count"  HVESP01

BO_ 2499740522 HVESP01_Sohr_6: 8 HVESP01
 SG_ HVESP01_packSOHR_6 : 32|8@1+ (0.4,0) [0|100] "%"  HVESP01
 SG_ HVESP01_lowestCellSohrCellNum_6 : 24|8@1+ (1,0) [0|250] "count"  HVESP01

BO_ 2499740523 HVESP01_Sohr_7: 8 HVESP01
 SG_ HVESP01_packSOHR_7 : 32|8@1+ (0.4,0) [0|100] "%"  HVESP01
 SG_ HVESP01_lowestCellSohrCellNum_7 : 24|8@1+ (1,0) [0|250] "count"  HVESP01

BO_ 2499740524 HVESP01_Sohr_8: 8 HVESP01
 SG_ HVESP01_packSOHR_8 : 32|8@1+ (0.4,0) [0|100] "%"  HVESP01
 SG_ HVESP01_lowestCellSohrCellNum_8 : 24|8@1+ (1,0) [0|250] "count"  HVESP01

BO_ 2499740773 HVESP01_SpeakerClaim_1: 8 HVESP01
 SG_ HVESP01_speakerClaimFlag_1 : 0|8@1+ (1,0) [0|255] ""  HVESP01
 SG_ HVESP01_expectedSpeakerID_1 : 8|8@1+ (1,0) [0|255] ""  HVESP01
 SG_ HVESP01_SystemState_1 : 16|4@1+ (1,0) [0|15] ""  HVESP01

BO_ 2499740774 HVESP01_SpeakerClaim_2: 8 HVESP01
 SG_ HVESP01_speakerClaimFlag_2 : 0|8@1+ (1,0) [0|255] ""  HVESP01
 SG_ HVESP01_expectedSpeakerID_2 : 8|8@1+ (1,0) [0|255] ""  HVESP01
 SG_ HVESP01_SystemState_2 : 16|4@1+ (1,0) [0|15] ""  HVESP01

BO_ 2499740775 HVESP01_SpeakerClaim_3: 8 HVESP01
 SG_ HVESP01_speakerClaimFlag_3 : 0|8@1+ (1,0) [0|255] ""  HVESP01
 SG_ HVESP01_expectedSpeakerID_3 : 8|8@1+ (1,0) [0|255] ""  HVESP01
 SG_ HVESP01_SystemState_3 : 16|4@1+ (1,0) [0|15] ""  HVESP01

BO_ 2499740776 HVESP01_SpeakerClaim_4: 8 HVESP01
 SG_ HVESP01_speakerClaimFlag_4 : 0|8@1+ (1,0) [0|255] ""  HVESP01
 SG_ HVESP01_expectedSpeakerID_4 : 8|8@1+ (1,0) [0|255] ""  HVESP01
 SG_ HVESP01_SystemState_4 : 16|4@1+ (1,0) [0|15] ""  HVESP01

BO_ 2499740777 HVESP01_SpeakerClaim_5: 8 HVESP01
 SG_ HVESP01_speakerClaimFlag_5 : 0|8@1+ (1,0) [0|255] ""  HVESP01
 SG_ HVESP01_expectedSpeakerID_5 : 8|8@1+ (1,0) [0|255] ""  HVESP01
 SG_ HVESP01_SystemState_5 : 16|4@1+ (1,0) [0|15] ""  HVESP01

BO_ 2499740778 HVESP01_SpeakerClaim_6: 8 HVESP01
 SG_ HVESP01_speakerClaimFlag_6 : 0|8@1+ (1,0) [0|255] ""  HVESP01
 SG_ HVESP01_expectedSpeakerID_6 : 8|8@1+ (1,0) [0|255] ""  HVESP01
 SG_ HVESP01_SystemState_6 : 16|4@1+ (1,0) [0|15] ""  HVESP01

BO_ 2499740779 HVESP01_SpeakerClaim_7: 8 HVESP01
 SG_ HVESP01_speakerClaimFlag_7 : 0|8@1+ (1,0) [0|255] ""  HVESP01
 SG_ HVESP01_expectedSpeakerID_7 : 8|8@1+ (1,0) [0|255] ""  HVESP01
 SG_ HVESP01_SystemState_7 : 16|4@1+ (1,0) [0|15] ""  HVESP01

BO_ 2499740780 HVESP01_SpeakerClaim_8: 8 HVESP01
 SG_ HVESP01_speakerClaimFlag_8 : 0|8@1+ (1,0) [0|255] ""  HVESP01
 SG_ HVESP01_expectedSpeakerID_8 : 8|8@1+ (1,0) [0|255] ""  HVESP01
 SG_ HVESP01_SystemState_8 : 16|4@1+ (1,0) [0|15] ""  HVESP01

BO_ 2499741029 HVESP01_brickSOC_1: 8 HVESP01
 SG_ HVESP01_brickSOC_01_1 m0: 8|14@1+ (1,0) [0|100] "%"  HVESP01
 SG_ HVESP01_brickSOC_02_1 m0: 22|14@1+ (1,0) [0|100] "%"  HVESP01
 SG_ HVESP01_brickSOC_03_1 m0: 36|14@1+ (1,0) [0|100] "%"  HVESP01
 SG_ HVESP01_brickSOC_04_1 m0: 50|14@1+ (1,0) [0|100] "%"  HVESP01
 SG_ HVESP01_brickSOC_05_1 m1: 8|14@1+ (1,0) [0|100] "%"  HVESP01
 SG_ HVESP01_brickSOC_06_1 m1: 22|14@1+ (1,0) [0|100] "%"  HVESP01
 SG_ HVESP01_brickSOC_07_1 m1: 36|14@1+ (1,0) [0|100] "%"  HVESP01
 SG_ HVESP01_brickSOC_08_1 m1: 50|14@1+ (1,0) [0|100] "%"  HVESP01
 SG_ HVESP01_brickSOC_09_1 m2: 8|14@1+ (1,0) [0|100] "%"  HVESP01
 SG_ HVESP01_brickSOC_10_1 m2: 22|14@1+ (1,0) [0|100] "%"  HVESP01
 SG_ HVESP01_brickSOC_11_1 m2: 36|14@1+ (1,0) [0|100] "%"  HVESP01
 SG_ HVESP01_brickSOC_12_1 m2: 50|14@1+ (1,0) [0|100] "%"  HVESP01
 SG_ HVESP01_brickSOC_13_1 m3: 8|14@1+ (1,0) [0|100] "%"  HVESP01
 SG_ HVESP01_brickSOC_14_1 m3: 22|14@1+ (1,0) [0|100] "%"  HVESP01
 SG_ HVESP01_brickSOC_15_1 m3: 36|14@1+ (1,0) [0|100] "%"  HVESP01
 SG_ HVESP01_brickSOC_16_1 m3: 50|14@1+ (1,0) [0|100] "%"  HVESP01
 SG_ HVESP01_brickSOC_17_1 m4: 8|14@1+ (1,0) [0|100] "%"  HVESP01
 SG_ HVESP01_brickSOC_18_1 m4: 22|14@1+ (1,0) [0|100] "%"  HVESP01
 SG_ HVESP01_brickSOC_19_1 m4: 36|14@1+ (1,0) [0|100] "%"  HVESP01
 SG_ HVESP01_brickSOC_20_1 m4: 50|14@1+ (1,0) [0|100] "%"  HVESP01
 SG_ HVESP01_brickSOC_21_1 m5: 8|14@1+ (1,0) [0|100] "%"  HVESP01
 SG_ HVESP01_brickSOC_22_1 m5: 22|14@1+ (1,0) [0|100] "%"  HVESP01
 SG_ HVESP01_brickSOC_23_1 m5: 36|14@1+ (1,0) [0|100] "%"  HVESP01
 SG_ HVESP01_brickSOC_24_1 m5: 50|14@1+ (1,0) [0|100] "%"  HVESP01
 SG_ HVESP01_brickSOC_25_1 m6: 8|14@1+ (1,0) [0|100] "%"  HVESP01
 SG_ HVESP01_brickSOC_26_1 m6: 22|14@1+ (1,0) [0|100] "%"  HVESP01
 SG_ HVESP01_brickSOC_27_1 m6: 36|14@1+ (1,0) [0|100] "%"  HVESP01
 SG_ HVESP01_brickSOC_28_1 m6: 50|14@1+ (1,0) [0|100] "%"  HVESP01
 SG_ HVESP01_brickSOC_29_1 m7: 8|14@1+ (1,0) [0|100] "%"  HVESP01
 SG_ HVESP01_brickSOC_30_1 m7: 22|14@1+ (1,0) [0|100] "%"  HVESP01
 SG_ HVESP01_brickSOC_31_1 m7: 36|14@1+ (1,0) [0|100] "%"  HVESP01
 SG_ HVESP01_brickSOC_32_1 m7: 50|14@1+ (1,0) [0|100] "%"  HVESP01
 SG_ HVESP01_brickSOC_33_1 m8: 8|14@1+ (1,0) [0|100] "%"  HVESP01
 SG_ HVESP01_brickSOC_34_1 m8: 22|14@1+ (1,0) [0|100] "%"  HVESP01
 SG_ HVESP01_brickSOC_35_1 m8: 36|14@1+ (1,0) [0|100] "%"  HVESP01
 SG_ HVESP01_brickSOC_36_1 m8: 50|14@1+ (1,0) [0|100] "%"  HVESP01
 SG_ HVESP01_brickSOC_37_1 m9: 8|14@1+ (1,0) [0|100] "%"  HVESP01
 SG_ HVESP01_brickSOC_38_1 m9: 22|14@1+ (1,0) [0|100] "%"  HVESP01
 SG_ HVESP01_brickSOC_39_1 m9: 36|14@1+ (1,0) [0|100] "%"  HVESP01
 SG_ HVESP01_brickSOC_40_1 m9: 50|14@1+ (1,0) [0|100] "%"  HVESP01
 SG_ HVESP01_brickSOC_41_1 m10: 8|14@1+ (1,0) [0|100] "%"  HVESP01
 SG_ HVESP01_brickSOC_42_1 m10: 22|14@1+ (1,0) [0|100] "%"  HVESP01
 SG_ HVESP01_brickSOC_43_1 m10: 36|14@1+ (1,0) [0|100] "%"  HVESP01
 SG_ HVESP01_brickSOC_44_1 m10: 50|14@1+ (1,0) [0|100] "%"  HVESP01
 SG_ HVESP01_brickSOC_45_1 m11: 8|14@1+ (1,0) [0|100] "%"  HVESP01
 SG_ HVESP01_brickSOC_46_1 m11: 22|14@1+ (1,0) [0|100] "%"  HVESP01
 SG_ HVESP01_brickSOC_47_1 m11: 36|14@1+ (1,0) [0|100] "%"  HVESP01
 SG_ HVESP01_brickSOC_48_1 m11: 50|14@1+ (1,0) [0|100] "%"  HVESP01
 SG_ HVESP01_brickSOC_49_1 m12: 8|14@1+ (1,0) [0|100] "%"  HVESP01
 SG_ HVESP01_brickSOC_50_1 m12: 22|14@1+ (1,0) [0|100] "%"  HVESP01
 SG_ HVESP01_brickSOC_51_1 m12: 36|14@1+ (1,0) [0|100] "%"  HVESP01
 SG_ HVESP01_brickSOC_52_1 m12: 50|14@1+ (1,0) [0|100] "%"  HVESP01
 SG_ HVESP01_brickSOC_53_1 m13: 8|14@1+ (1,0) [0|100] "%"  HVESP01
 SG_ HVESP01_brickSOC_54_1 m13: 22|14@1+ (1,0) [0|100] "%"  HVESP01
 SG_ HVESP01_brickSOC_55_1 m13: 36|14@1+ (1,0) [0|100] "%"  HVESP01
 SG_ HVESP01_brickSOC_56_1 m13: 50|14@1+ (1,0) [0|100] "%"  HVESP01
 SG_ HVESP01_brickSOC_57_1 m14: 8|14@1+ (1,0) [0|100] "%"  HVESP01
 SG_ HVESP01_brickSOC_58_1 m14: 22|14@1+ (1,0) [0|100] "%"  HVESP01
 SG_ HVESP01_brickSOC_59_1 m14: 36|14@1+ (1,0) [0|100] "%"  HVESP01
 SG_ HVESP01_brickSOC_60_1 m14: 50|14@1+ (1,0) [0|100] "%"  HVESP01
 SG_ HVESP01_brickSOC_61_1 m15: 8|14@1+ (1,0) [0|100] "%"  HVESP01
 SG_ HVESP01_brickSOC_62_1 m15: 22|14@1+ (1,0) [0|100] "%"  HVESP01
 SG_ HVESP01_brickSOC_63_1 m15: 36|14@1+ (1,0) [0|100] "%"  HVESP01
 SG_ HVESP01_brickSOC_64_1 m15: 50|14@1+ (1,0) [0|100] "%"  HVESP01
 SG_ HVESP01_brickSOC_65_1 m16: 8|14@1+ (1,0) [0|100] "%"  HVESP01
 SG_ HVESP01_brickSOC_66_1 m16: 22|14@1+ (1,0) [0|100] "%"  HVESP01
 SG_ HVESP01_brickSOC_67_1 m16: 36|14@1+ (1,0) [0|100] "%"  HVESP01
 SG_ HVESP01_brickSOC_68_1 m16: 50|14@1+ (1,0) [0|100] "%"  HVESP01
 SG_ HVESP01_brickSOC_69_1 m17: 8|14@1+ (1,0) [0|100] "%"  HVESP01
 SG_ HVESP01_brickSOC_70_1 m17: 22|14@1+ (1,0) [0|100] "%"  HVESP01
 SG_ HVESP01_brickSOC_71_1 m17: 36|14@1+ (1,0) [0|100] "%"  HVESP01
 SG_ HVESP01_brickSOC_72_1 m17: 50|14@1+ (1,0) [0|100] "%"  HVESP01
 SG_ HVESP01_brickSOC_73_1 m18: 8|14@1+ (1,0) [0|100] "%"  HVESP01
 SG_ HVESP01_brickSOC_74_1 m18: 22|14@1+ (1,0) [0|100] "%"  HVESP01
 SG_ HVESP01_brickSOC_75_1 m18: 36|14@1+ (1,0) [0|100] "%"  HVESP01
 SG_ HVESP01_brickSOC_76_1 m18: 50|14@1+ (1,0) [0|100] "%"  HVESP01
 SG_ HVESP01_brickSOC_77_1 m19: 8|14@1+ (1,0) [0|100] "%"  HVESP01
 SG_ HVESP01_brickSOC_78_1 m19: 22|14@1+ (1,0) [0|100] "%"  HVESP01
 SG_ HVESP01_brickSOC_79_1 m19: 36|14@1+ (1,0) [0|100] "%"  HVESP01
 SG_ HVESP01_brickSOC_80_1 m19: 50|14@1+ (1,0) [0|100] "%"  HVESP01
 SG_ HVESP01_brickSOC_81_1 m20: 8|14@1+ (1,0) [0|100] "%"  HVESP01
 SG_ HVESP01_brickSOC_82_1 m20: 22|14@1+ (1,0) [0|100] "%"  HVESP01
 SG_ HVESP01_brickSOC_83_1 m20: 36|14@1+ (1,0) [0|100] "%"  HVESP01
 SG_ HVESP01_brickSOC_84_1 m20: 50|14@1+ (1,0) [0|100] "%"  HVESP01
 SG_ HVESP01_brickSOC_85_1 m21: 8|14@1+ (1,0) [0|100] "%"  HVESP01
 SG_ HVESP01_brickSOC_86_1 m21: 22|14@1+ (1,0) [0|100] "%"  HVESP01
 SG_ HVESP01_brickSOC_87_1 m21: 36|14@1+ (1,0) [0|100] "%"  HVESP01
 SG_ HVESP01_brickSOC_88_1 m21: 50|14@1+ (1,0) [0|100] "%"  HVESP01
 SG_ HVESP01_brickSOC_89_1 m22: 8|14@1+ (1,0) [0|100] "%"  HVESP01
 SG_ HVESP01_brickSOC_90_1 m22: 22|14@1+ (1,0) [0|100] "%"  HVESP01
 SG_ HVESP01_brickSOC_91_1 m22: 36|14@1+ (1,0) [0|100] "%"  HVESP01
 SG_ HVESP01_brickSOC_92_1 m22: 50|14@1+ (1,0) [0|100] "%"  HVESP01
 SG_ HVESP01_brickSOC_93_1 m23: 8|14@1+ (1,0) [0|100] "%"  HVESP01
 SG_ HVESP01_brickSOC_94_1 m23: 22|14@1+ (1,0) [0|100] "%"  HVESP01
 SG_ HVESP01_brickSOC_95_1 m23: 36|14@1+ (1,0) [0|100] "%"  HVESP01
 SG_ HVESP01_brickSOC_96_1 m23: 50|14@1+ (1,0) [0|100] "%"  HVESP01
 SG_ HVESP01_brickSOC_97_1 m24: 8|14@1+ (1,0) [0|100] "%"  HVESP01
 SG_ HVESP01_brickSOC_98_1 m24: 22|14@1+ (1,0) [0|100] "%"  HVESP01
 SG_ HVESP01_brickSOC_99_1 m24: 36|14@1+ (1,0) [0|100] "%"  HVESP01
 SG_ HVESP01_brickSOC_100_1 m24: 50|14@1+ (1,0) [0|100] "%"  HVESP01
 SG_ HVESP01_brickSOC_101_1 m25: 8|14@1+ (1,0) [0|100] "%"  HVESP01
 SG_ HVESP01_brickSOC_102_1 m25: 22|14@1+ (1,0) [0|100] "%"  HVESP01
 SG_ HVESP01_brickSOC_103_1 m25: 36|14@1+ (1,0) [0|100] "%"  HVESP01
 SG_ HVESP01_brickSOC_104_1 m25: 50|14@1+ (1,0) [0|100] "%"  HVESP01
 SG_ HVESP01_brickSOC_105_1 m26: 8|14@1+ (1,0) [0|100] "%"  HVESP01
 SG_ HVESP01_brickSOC_106_1 m26: 22|14@1+ (1,0) [0|100] "%"  HVESP01
 SG_ HVESP01_brickSOC_107_1 m26: 36|14@1+ (1,0) [0|100] "%"  HVESP01
 SG_ HVESP01_brickSOC_108_1 m26: 50|14@1+ (1,0) [0|100] "%"  HVESP01
 SG_ HVESP01_brickSOC_109_1 m27: 8|14@1+ (1,0) [0|100] "%"  HVESP01
 SG_ HVESP01_brickSOC_110_1 m27: 22|14@1+ (1,0) [0|100] "%"  HVESP01
 SG_ HVESP01_brickSOC_111_1 m27: 36|14@1+ (1,0) [0|100] "%"  HVESP01
 SG_ HVESP01_brickSOC_112_1 m27: 50|14@1+ (1,0) [0|100] "%"  HVESP01
 SG_ HVESP01_brickSOC_113_1 m28: 8|14@1+ (1,0) [0|100] "%"  HVESP01
 SG_ HVESP01_brickSOC_114_1 m28: 22|14@1+ (1,0) [0|100] "%"  HVESP01
 SG_ HVESP01_brickSOC_115_1 m28: 36|14@1+ (1,0) [0|100] "%"  HVESP01
 SG_ HVESP01_brickSOC_116_1 m28: 50|14@1+ (1,0) [0|100] "%"  HVESP01
 SG_ HVESP01_brickSOC_117_1 m29: 8|14@1+ (1,0) [0|100] "%"  HVESP01
 SG_ HVESP01_brickSOC_118_1 m29: 22|14@1+ (1,0) [0|100] "%"  HVESP01
 SG_ HVESP01_brickSOC_119_1 m29: 36|14@1+ (1,0) [0|100] "%"  HVESP01
 SG_ HVESP01_brickSOC_120_1 m29: 50|14@1+ (1,0) [0|100] "%"  HVESP01
 SG_ HVESP01_brickSOC_121_1 m30: 8|14@1+ (1,0) [0|100] "%"  HVESP01
 SG_ HVESP01_brickSOC_122_1 m30: 22|14@1+ (1,0) [0|100] "%"  HVESP01
 SG_ HVESP01_brickSOC_123_1 m30: 36|14@1+ (1,0) [0|100] "%"  HVESP01
 SG_ HVESP01_brickSOC_124_1 m30: 50|14@1+ (1,0) [0|100] "%"  HVESP01
 SG_ HVESP01_brickSOC_125_1 m31: 8|14@1+ (1,0) [0|100] "%"  HVESP01
 SG_ HVESP01_brickSOC_126_1 m31: 22|14@1+ (1,0) [0|100] "%"  HVESP01
 SG_ HVESP01_brickSOC_127_1 m31: 36|14@1+ (1,0) [0|100] "%"  HVESP01
 SG_ HVESP01_brickSOC_128_1 m31: 50|14@1+ (1,0) [0|100] "%"  HVESP01
 SG_ HVESP01_brickSOC_129_1 m32: 8|14@1+ (1,0) [0|100] "%"  HVESP01
 SG_ HVESP01_brickSOC_130_1 m32: 22|14@1+ (1,0) [0|100] "%"  HVESP01
 SG_ HVESP01_brickSOC_131_1 m32: 36|14@1+ (1,0) [0|100] "%"  HVESP01
 SG_ HVESP01_brickSOC_132_1 m32: 50|14@1+ (1,0) [0|100] "%"  HVESP01
 SG_ HVESP01_brickSOC_133_1 m33: 8|14@1+ (1,0) [0|100] "%"  HVESP01
 SG_ HVESP01_brickSOC_134_1 m33: 22|14@1+ (1,0) [0|100] "%"  HVESP01
 SG_ HVESP01_brickSOC_135_1 m33: 36|14@1+ (1,0) [0|100] "%"  HVESP01
 SG_ HVESP01_brickSOC_136_1 m33: 50|14@1+ (1,0) [0|100] "%"  HVESP01
 SG_ HVESP01_brickSOC_137_1 m34: 8|14@1+ (1,0) [0|100] "%"  HVESP01
 SG_ HVESP01_brickSOC_138_1 m34: 22|14@1+ (1,0) [0|100] "%"  HVESP01
 SG_ HVESP01_brickSOC_139_1 m34: 36|14@1+ (1,0) [0|100] "%"  HVESP01
 SG_ HVESP01_brickSOC_140_1 m34: 50|14@1+ (1,0) [0|100] "%"  HVESP01
 SG_ HVESP01_brickSOC_141_1 m35: 8|14@1+ (1,0) [0|100] "%"  HVESP01
 SG_ HVESP01_brickSOC_142_1 m35: 22|14@1+ (1,0) [0|100] "%"  HVESP01
 SG_ HVESP01_brickSOC_143_1 m35: 36|14@1+ (1,0) [0|100] "%"  HVESP01
 SG_ HVESP01_brickSOC_144_1 m35: 50|14@1+ (1,0) [0|100] "%"  HVESP01
 SG_ HVESP01_brickSOC_145_1 m36: 8|14@1+ (1,0) [0|100] "%"  HVESP01
 SG_ HVESP01_brickSOC_146_1 m36: 22|14@1+ (1,0) [0|100] "%"  HVESP01
 SG_ HVESP01_brickSOC_147_1 m36: 36|14@1+ (1,0) [0|100] "%"  HVESP01
 SG_ HVESP01_brickSOC_148_1 m36: 50|14@1+ (1,0) [0|100] "%"  HVESP01
 SG_ HVESP01_brickSOC_149_1 m37: 8|14@1+ (1,0) [0|100] "%"  HVESP01
 SG_ HVESP01_brickSOC_150_1 m37: 22|14@1+ (1,0) [0|100] "%"  HVESP01
 SG_ HVESP01_brickSOC_151_1 m37: 36|14@1+ (1,0) [0|100] "%"  HVESP01
 SG_ HVESP01_brickSOC_152_1 m37: 50|14@1+ (1,0) [0|100] "%"  HVESP01
 SG_ HVESP01_brickSOC_153_1 m38: 8|14@1+ (1,0) [0|100] "%"  HVESP01
 SG_ HVESP01_brickSOC_154_1 m38: 22|14@1+ (1,0) [0|100] "%"  HVESP01
 SG_ HVESP01_brickSOC_155_1 m38: 36|14@1+ (1,0) [0|100] "%"  HVESP01
 SG_ HVESP01_brickSOC_156_1 m38: 50|14@1+ (1,0) [0|100] "%"  HVESP01
 SG_ HVESP01_brickSOC_157_1 m39: 8|14@1+ (1,0) [0|100] "%"  HVESP01
 SG_ HVESP01_brickSOC_158_1 m39: 22|14@1+ (1,0) [0|100] "%"  HVESP01
 SG_ HVESP01_brickSOC_159_1 m39: 36|14@1+ (1,0) [0|100] "%"  HVESP01
 SG_ HVESP01_brickSOC_160_1 m39: 50|14@1+ (1,0) [0|100] "%"  HVESP01
 SG_ HVESP01_brickSOC_161_1 m40: 8|14@1+ (1,0) [0|100] "%"  HVESP01
 SG_ HVESP01_brickSOC_162_1 m40: 22|14@1+ (1,0) [0|100] "%"  HVESP01
 SG_ HVESP01_brickSOC_163_1 m40: 36|14@1+ (1,0) [0|100] "%"  HVESP01
 SG_ HVESP01_brickSOC_164_1 m40: 50|14@1+ (1,0) [0|100] "%"  HVESP01
 SG_ HVESP01_brickSOC_165_1 m41: 8|14@1+ (1,0) [0|100] "%"  HVESP01
 SG_ HVESP01_brickSOC_166_1 m41: 22|14@1+ (1,0) [0|100] "%"  HVESP01
 SG_ HVESP01_brickSOC_167_1 m41: 36|14@1+ (1,0) [0|100] "%"  HVESP01
 SG_ HVESP01_brickSOC_168_1 m41: 50|14@1+ (1,0) [0|100] "%"  HVESP01
 SG_ HVESP01_brickSOC_169_1 m42: 8|14@1+ (1,0) [0|100] "%"  HVESP01
 SG_ HVESP01_brickSOC_170_1 m42: 22|14@1+ (1,0) [0|100] "%"  HVESP01
 SG_ HVESP01_brickSOC_171_1 m42: 36|14@1+ (1,0) [0|100] "%"  HVESP01
 SG_ HVESP01_brickSOC_172_1 m42: 50|14@1+ (1,0) [0|100] "%"  HVESP01
 SG_ HVESP01_brickSOC_173_1 m43: 8|14@1+ (1,0) [0|100] "%"  HVESP01
 SG_ HVESP01_brickSOC_174_1 m43: 22|14@1+ (1,0) [0|100] "%"  HVESP01
 SG_ HVESP01_brickSOC_175_1 m43: 36|14@1+ (1,0) [0|100] "%"  HVESP01
 SG_ HVESP01_brickSOC_176_1 m43: 50|14@1+ (1,0) [0|100] "%"  HVESP01
 SG_ HVESP01_brickSOC_177_1 m44: 8|14@1+ (1,0) [0|100] "%"  HVESP01
 SG_ HVESP01_brickSOC_178_1 m44: 22|14@1+ (1,0) [0|100] "%"  HVESP01
 SG_ HVESP01_brickSOC_179_1 m44: 36|14@1+ (1,0) [0|100] "%"  HVESP01
 SG_ HVESP01_brickSOC_180_1 m44: 50|14@1+ (1,0) [0|100] "%"  HVESP01
 SG_ HVESP01_brickSOC_181_1 m45: 8|14@1+ (1,0) [0|100] "%"  HVESP01
 SG_ HVESP01_brickSOC_182_1 m45: 22|14@1+ (1,0) [0|100] "%"  HVESP01
 SG_ HVESP01_brickSOC_183_1 m45: 36|14@1+ (1,0) [0|100] "%"  HVESP01
 SG_ HVESP01_brickSOC_184_1 m45: 50|14@1+ (1,0) [0|100] "%"  HVESP01
 SG_ HVESP01_brickSOC_185_1 m46: 8|14@1+ (1,0) [0|100] "%"  HVESP01
 SG_ HVESP01_brickSOC_186_1 m46: 22|14@1+ (1,0) [0|100] "%"  HVESP01
 SG_ HVESP01_brickSOC_187_1 m46: 36|14@1+ (1,0) [0|100] "%"  HVESP01
 SG_ HVESP01_brickSOC_188_1 m46: 50|14@1+ (1,0) [0|100] "%"  HVESP01
 SG_ HVESP01_brickSOC_189_1 m47: 8|14@1+ (1,0) [0|100] "%"  HVESP01
 SG_ HVESP01_brickSOC_190_1 m47: 22|14@1+ (1,0) [0|100] "%"  HVESP01
 SG_ HVESP01_brickSOC_191_1 m47: 36|14@1+ (1,0) [0|100] "%"  HVESP01
 SG_ HVESP01_brickSOC_192_1 m47: 50|14@1+ (1,0) [0|100] "%"  HVESP01
 SG_ multiplexorsoc_1 M: 0|8@1+ (1,0) [0|255] ""  HVESP01

BO_ 2499741030 HVESP01_brickSOC_2: 8 HVESP01
 SG_ HVESP01_brickSOC_01_2 m0: 8|14@1+ (1,0) [0|100] "%"  HVESP01
 SG_ HVESP01_brickSOC_02_2 m0: 22|14@1+ (1,0) [0|100] "%"  HVESP01
 SG_ HVESP01_brickSOC_03_2 m0: 36|14@1+ (1,0) [0|100] "%"  HVESP01
 SG_ HVESP01_brickSOC_04_2 m0: 50|14@1+ (1,0) [0|100] "%"  HVESP01
 SG_ HVESP01_brickSOC_05_2 m1: 8|14@1+ (1,0) [0|100] "%"  HVESP01
 SG_ HVESP01_brickSOC_06_2 m1: 22|14@1+ (1,0) [0|100] "%"  HVESP01
 SG_ HVESP01_brickSOC_07_2 m1: 36|14@1+ (1,0) [0|100] "%"  HVESP01
 SG_ HVESP01_brickSOC_08_2 m1: 50|14@1+ (1,0) [0|100] "%"  HVESP01
 SG_ HVESP01_brickSOC_09_2 m2: 8|14@1+ (1,0) [0|100] "%"  HVESP01
 SG_ HVESP01_brickSOC_10_2 m2: 22|14@1+ (1,0) [0|100] "%"  HVESP01
 SG_ HVESP01_brickSOC_11_2 m2: 36|14@1+ (1,0) [0|100] "%"  HVESP01
 SG_ HVESP01_brickSOC_12_2 m2: 50|14@1+ (1,0) [0|100] "%"  HVESP01
 SG_ HVESP01_brickSOC_13_2 m3: 8|14@1+ (1,0) [0|100] "%"  HVESP01
 SG_ HVESP01_brickSOC_14_2 m3: 22|14@1+ (1,0) [0|100] "%"  HVESP01
 SG_ HVESP01_brickSOC_15_2 m3: 36|14@1+ (1,0) [0|100] "%"  HVESP01
 SG_ HVESP01_brickSOC_16_2 m3: 50|14@1+ (1,0) [0|100] "%"  HVESP01
 SG_ HVESP01_brickSOC_17_2 m4: 8|14@1+ (1,0) [0|100] "%"  HVESP01
 SG_ HVESP01_brickSOC_18_2 m4: 22|14@1+ (1,0) [0|100] "%"  HVESP01
 SG_ HVESP01_brickSOC_19_2 m4: 36|14@1+ (1,0) [0|100] "%"  HVESP01
 SG_ HVESP01_brickSOC_20_2 m4: 50|14@1+ (1,0) [0|100] "%"  HVESP01
 SG_ HVESP01_brickSOC_21_2 m5: 8|14@1+ (1,0) [0|100] "%"  HVESP01
 SG_ HVESP01_brickSOC_22_2 m5: 22|14@1+ (1,0) [0|100] "%"  HVESP01
 SG_ HVESP01_brickSOC_23_2 m5: 36|14@1+ (1,0) [0|100] "%"  HVESP01
 SG_ HVESP01_brickSOC_24_2 m5: 50|14@1+ (1,0) [0|100] "%"  HVESP01
 SG_ HVESP01_brickSOC_25_2 m6: 8|14@1+ (1,0) [0|100] "%"  HVESP01
 SG_ HVESP01_brickSOC_26_2 m6: 22|14@1+ (1,0) [0|100] "%"  HVESP01
 SG_ HVESP01_brickSOC_27_2 m6: 36|14@1+ (1,0) [0|100] "%"  HVESP01
 SG_ HVESP01_brickSOC_28_2 m6: 50|14@1+ (1,0) [0|100] "%"  HVESP01
 SG_ HVESP01_brickSOC_29_2 m7: 8|14@1+ (1,0) [0|100] "%"  HVESP01
 SG_ HVESP01_brickSOC_30_2 m7: 22|14@1+ (1,0) [0|100] "%"  HVESP01
 SG_ HVESP01_brickSOC_31_2 m7: 36|14@1+ (1,0) [0|100] "%"  HVESP01
 SG_ HVESP01_brickSOC_32_2 m7: 50|14@1+ (1,0) [0|100] "%"  HVESP01
 SG_ HVESP01_brickSOC_33_2 m8: 8|14@1+ (1,0) [0|100] "%"  HVESP01
 SG_ HVESP01_brickSOC_34_2 m8: 22|14@1+ (1,0) [0|100] "%"  HVESP01
 SG_ HVESP01_brickSOC_35_2 m8: 36|14@1+ (1,0) [0|100] "%"  HVESP01
 SG_ HVESP01_brickSOC_36_2 m8: 50|14@1+ (1,0) [0|100] "%"  HVESP01
 SG_ HVESP01_brickSOC_37_2 m9: 8|14@1+ (1,0) [0|100] "%"  HVESP01
 SG_ HVESP01_brickSOC_38_2 m9: 22|14@1+ (1,0) [0|100] "%"  HVESP01
 SG_ HVESP01_brickSOC_39_2 m9: 36|14@1+ (1,0) [0|100] "%"  HVESP01
 SG_ HVESP01_brickSOC_40_2 m9: 50|14@1+ (1,0) [0|100] "%"  HVESP01
 SG_ HVESP01_brickSOC_41_2 m10: 8|14@1+ (1,0) [0|100] "%"  HVESP01
 SG_ HVESP01_brickSOC_42_2 m10: 22|14@1+ (1,0) [0|100] "%"  HVESP01
 SG_ HVESP01_brickSOC_43_2 m10: 36|14@1+ (1,0) [0|100] "%"  HVESP01
 SG_ HVESP01_brickSOC_44_2 m10: 50|14@1+ (1,0) [0|100] "%"  HVESP01
 SG_ HVESP01_brickSOC_45_2 m11: 8|14@1+ (1,0) [0|100] "%"  HVESP01
 SG_ HVESP01_brickSOC_46_2 m11: 22|14@1+ (1,0) [0|100] "%"  HVESP01
 SG_ HVESP01_brickSOC_47_2 m11: 36|14@1+ (1,0) [0|100] "%"  HVESP01
 SG_ HVESP01_brickSOC_48_2 m11: 50|14@1+ (1,0) [0|100] "%"  HVESP01
 SG_ HVESP01_brickSOC_49_2 m12: 8|14@1+ (1,0) [0|100] "%"  HVESP01
 SG_ HVESP01_brickSOC_50_2 m12: 22|14@1+ (1,0) [0|100] "%"  HVESP01
 SG_ HVESP01_brickSOC_51_2 m12: 36|14@1+ (1,0) [0|100] "%"  HVESP01
 SG_ HVESP01_brickSOC_52_2 m12: 50|14@1+ (1,0) [0|100] "%"  HVESP01
 SG_ HVESP01_brickSOC_53_2 m13: 8|14@1+ (1,0) [0|100] "%"  HVESP01
 SG_ HVESP01_brickSOC_54_2 m13: 22|14@1+ (1,0) [0|100] "%"  HVESP01
 SG_ HVESP01_brickSOC_55_2 m13: 36|14@1+ (1,0) [0|100] "%"  HVESP01
 SG_ HVESP01_brickSOC_56_2 m13: 50|14@1+ (1,0) [0|100] "%"  HVESP01
 SG_ HVESP01_brickSOC_57_2 m14: 8|14@1+ (1,0) [0|100] "%"  HVESP01
 SG_ HVESP01_brickSOC_58_2 m14: 22|14@1+ (1,0) [0|100] "%"  HVESP01
 SG_ HVESP01_brickSOC_59_2 m14: 36|14@1+ (1,0) [0|100] "%"  HVESP01
 SG_ HVESP01_brickSOC_60_2 m14: 50|14@1+ (1,0) [0|100] "%"  HVESP01
 SG_ HVESP01_brickSOC_61_2 m15: 8|14@1+ (1,0) [0|100] "%"  HVESP01
 SG_ HVESP01_brickSOC_62_2 m15: 22|14@1+ (1,0) [0|100] "%"  HVESP01
 SG_ HVESP01_brickSOC_63_2 m15: 36|14@1+ (1,0) [0|100] "%"  HVESP01
 SG_ HVESP01_brickSOC_64_2 m15: 50|14@1+ (1,0) [0|100] "%"  HVESP01
 SG_ HVESP01_brickSOC_65_2 m16: 8|14@1+ (1,0) [0|100] "%"  HVESP01
 SG_ HVESP01_brickSOC_66_2 m16: 22|14@1+ (1,0) [0|100] "%"  HVESP01
 SG_ HVESP01_brickSOC_67_2 m16: 36|14@1+ (1,0) [0|100] "%"  HVESP01
 SG_ HVESP01_brickSOC_68_2 m16: 50|14@1+ (1,0) [0|100] "%"  HVESP01
 SG_ HVESP01_brickSOC_69_2 m17: 8|14@1+ (1,0) [0|100] "%"  HVESP01
 SG_ HVESP01_brickSOC_70_2 m17: 22|14@1+ (1,0) [0|100] "%"  HVESP01
 SG_ HVESP01_brickSOC_71_2 m17: 36|14@1+ (1,0) [0|100] "%"  HVESP01
 SG_ HVESP01_brickSOC_72_2 m17: 50|14@1+ (1,0) [0|100] "%"  HVESP01
 SG_ HVESP01_brickSOC_73_2 m18: 8|14@1+ (1,0) [0|100] "%"  HVESP01
 SG_ HVESP01_brickSOC_74_2 m18: 22|14@1+ (1,0) [0|100] "%"  HVESP01
 SG_ HVESP01_brickSOC_75_2 m18: 36|14@1+ (1,0) [0|100] "%"  HVESP01
 SG_ HVESP01_brickSOC_76_2 m18: 50|14@1+ (1,0) [0|100] "%"  HVESP01
 SG_ HVESP01_brickSOC_77_2 m19: 8|14@1+ (1,0) [0|100] "%"  HVESP01
 SG_ HVESP01_brickSOC_78_2 m19: 22|14@1+ (1,0) [0|100] "%"  HVESP01
 SG_ HVESP01_brickSOC_79_2 m19: 36|14@1+ (1,0) [0|100] "%"  HVESP01
 SG_ HVESP01_brickSOC_80_2 m19: 50|14@1+ (1,0) [0|100] "%"  HVESP01
 SG_ HVESP01_brickSOC_81_2 m20: 8|14@1+ (1,0) [0|100] "%"  HVESP01
 SG_ HVESP01_brickSOC_82_2 m20: 22|14@1+ (1,0) [0|100] "%"  HVESP01
 SG_ HVESP01_brickSOC_83_2 m20: 36|14@1+ (1,0) [0|100] "%"  HVESP01
 SG_ HVESP01_brickSOC_84_2 m20: 50|14@1+ (1,0) [0|100] "%"  HVESP01
 SG_ HVESP01_brickSOC_85_2 m21: 8|14@1+ (1,0) [0|100] "%"  HVESP01
 SG_ HVESP01_brickSOC_86_2 m21: 22|14@1+ (1,0) [0|100] "%"  HVESP01
 SG_ HVESP01_brickSOC_87_2 m21: 36|14@1+ (1,0) [0|100] "%"  HVESP01
 SG_ HVESP01_brickSOC_88_2 m21: 50|14@1+ (1,0) [0|100] "%"  HVESP01
 SG_ HVESP01_brickSOC_89_2 m22: 8|14@1+ (1,0) [0|100] "%"  HVESP01
 SG_ HVESP01_brickSOC_90_2 m22: 22|14@1+ (1,0) [0|100] "%"  HVESP01
 SG_ HVESP01_brickSOC_91_2 m22: 36|14@1+ (1,0) [0|100] "%"  HVESP01
 SG_ HVESP01_brickSOC_92_2 m22: 50|14@1+ (1,0) [0|100] "%"  HVESP01
 SG_ HVESP01_brickSOC_93_2 m23: 8|14@1+ (1,0) [0|100] "%"  HVESP01
 SG_ HVESP01_brickSOC_94_2 m23: 22|14@1+ (1,0) [0|100] "%"  HVESP01
 SG_ HVESP01_brickSOC_95_2 m23: 36|14@1+ (1,0) [0|100] "%"  HVESP01
 SG_ HVESP01_brickSOC_96_2 m23: 50|14@1+ (1,0) [0|100] "%"  HVESP01
 SG_ HVESP01_brickSOC_97_2 m24: 8|14@1+ (1,0) [0|100] "%"  HVESP01
 SG_ HVESP01_brickSOC_98_2 m24: 22|14@1+ (1,0) [0|100] "%"  HVESP01
 SG_ HVESP01_brickSOC_99_2 m24: 36|14@1+ (1,0) [0|100] "%"  HVESP01
 SG_ HVESP01_brickSOC_100_2 m24: 50|14@1+ (1,0) [0|100] "%"  HVESP01
 SG_ HVESP01_brickSOC_101_2 m25: 8|14@1+ (1,0) [0|100] "%"  HVESP01
 SG_ HVESP01_brickSOC_102_2 m25: 22|14@1+ (1,0) [0|100] "%"  HVESP01
 SG_ HVESP01_brickSOC_103_2 m25: 36|14@1+ (1,0) [0|100] "%"  HVESP01
 SG_ HVESP01_brickSOC_104_2 m25: 50|14@1+ (1,0) [0|100] "%"  HVESP01
 SG_ HVESP01_brickSOC_105_2 m26: 8|14@1+ (1,0) [0|100] "%"  HVESP01
 SG_ HVESP01_brickSOC_106_2 m26: 22|14@1+ (1,0) [0|100] "%"  HVESP01
 SG_ HVESP01_brickSOC_107_2 m26: 36|14@1+ (1,0) [0|100] "%"  HVESP01
 SG_ HVESP01_brickSOC_108_2 m26: 50|14@1+ (1,0) [0|100] "%"  HVESP01
 SG_ HVESP01_brickSOC_109_2 m27: 8|14@1+ (1,0) [0|100] "%"  HVESP01
 SG_ HVESP01_brickSOC_110_2 m27: 22|14@1+ (1,0) [0|100] "%"  HVESP01
 SG_ HVESP01_brickSOC_111_2 m27: 36|14@1+ (1,0) [0|100] "%"  HVESP01
 SG_ HVESP01_brickSOC_112_2 m27: 50|14@1+ (1,0) [0|100] "%"  HVESP01
 SG_ HVESP01_brickSOC_113_2 m28: 8|14@1+ (1,0) [0|100] "%"  HVESP01
 SG_ HVESP01_brickSOC_114_2 m28: 22|14@1+ (1,0) [0|100] "%"  HVESP01
 SG_ HVESP01_brickSOC_115_2 m28: 36|14@1+ (1,0) [0|100] "%"  HVESP01
 SG_ HVESP01_brickSOC_116_2 m28: 50|14@1+ (1,0) [0|100] "%"  HVESP01
 SG_ HVESP01_brickSOC_117_2 m29: 8|14@1+ (1,0) [0|100] "%"  HVESP01
 SG_ HVESP01_brickSOC_118_2 m29: 22|14@1+ (1,0) [0|100] "%"  HVESP01
 SG_ HVESP01_brickSOC_119_2 m29: 36|14@1+ (1,0) [0|100] "%"  HVESP01
 SG_ HVESP01_brickSOC_120_2 m29: 50|14@1+ (1,0) [0|100] "%"  HVESP01
 SG_ HVESP01_brickSOC_121_2 m30: 8|14@1+ (1,0) [0|100] "%"  HVESP01
 SG_ HVESP01_brickSOC_122_2 m30: 22|14@1+ (1,0) [0|100] "%"  HVESP01
 SG_ HVESP01_brickSOC_123_2 m30: 36|14@1+ (1,0) [0|100] "%"  HVESP01
 SG_ HVESP01_brickSOC_124_2 m30: 50|14@1+ (1,0) [0|100] "%"  HVESP01
 SG_ HVESP01_brickSOC_125_2 m31: 8|14@1+ (1,0) [0|100] "%"  HVESP01
 SG_ HVESP01_brickSOC_126_2 m31: 22|14@1+ (1,0) [0|100] "%"  HVESP01
 SG_ HVESP01_brickSOC_127_2 m31: 36|14@1+ (1,0) [0|100] "%"  HVESP01
 SG_ HVESP01_brickSOC_128_2 m31: 50|14@1+ (1,0) [0|100] "%"  HVESP01
 SG_ HVESP01_brickSOC_129_2 m32: 8|14@1+ (1,0) [0|100] "%"  HVESP01
 SG_ HVESP01_brickSOC_130_2 m32: 22|14@1+ (1,0) [0|100] "%"  HVESP01
 SG_ HVESP01_brickSOC_131_2 m32: 36|14@1+ (1,0) [0|100] "%"  HVESP01
 SG_ HVESP01_brickSOC_132_2 m32: 50|14@1+ (1,0) [0|100] "%"  HVESP01
 SG_ HVESP01_brickSOC_133_2 m33: 8|14@1+ (1,0) [0|100] "%"  HVESP01
 SG_ HVESP01_brickSOC_134_2 m33: 22|14@1+ (1,0) [0|100] "%"  HVESP01
 SG_ HVESP01_brickSOC_135_2 m33: 36|14@1+ (1,0) [0|100] "%"  HVESP01
 SG_ HVESP01_brickSOC_136_2 m33: 50|14@1+ (1,0) [0|100] "%"  HVESP01
 SG_ HVESP01_brickSOC_137_2 m34: 8|14@1+ (1,0) [0|100] "%"  HVESP01
 SG_ HVESP01_brickSOC_138_2 m34: 22|14@1+ (1,0) [0|100] "%"  HVESP01
 SG_ HVESP01_brickSOC_139_2 m34: 36|14@1+ (1,0) [0|100] "%"  HVESP01
 SG_ HVESP01_brickSOC_140_2 m34: 50|14@1+ (1,0) [0|100] "%"  HVESP01
 SG_ HVESP01_brickSOC_141_2 m35: 8|14@1+ (1,0) [0|100] "%"  HVESP01
 SG_ HVESP01_brickSOC_142_2 m35: 22|14@1+ (1,0) [0|100] "%"  HVESP01
 SG_ HVESP01_brickSOC_143_2 m35: 36|14@1+ (1,0) [0|100] "%"  HVESP01
 SG_ HVESP01_brickSOC_144_2 m35: 50|14@1+ (1,0) [0|100] "%"  HVESP01
 SG_ HVESP01_brickSOC_145_2 m36: 8|14@1+ (1,0) [0|100] "%"  HVESP01
 SG_ HVESP01_brickSOC_146_2 m36: 22|14@1+ (1,0) [0|100] "%"  HVESP01
 SG_ HVESP01_brickSOC_147_2 m36: 36|14@1+ (1,0) [0|100] "%"  HVESP01
 SG_ HVESP01_brickSOC_148_2 m36: 50|14@1+ (1,0) [0|100] "%"  HVESP01
 SG_ HVESP01_brickSOC_149_2 m37: 8|14@1+ (1,0) [0|100] "%"  HVESP01
 SG_ HVESP01_brickSOC_150_2 m37: 22|14@1+ (1,0) [0|100] "%"  HVESP01
 SG_ HVESP01_brickSOC_151_2 m37: 36|14@1+ (1,0) [0|100] "%"  HVESP01
 SG_ HVESP01_brickSOC_152_2 m37: 50|14@1+ (1,0) [0|100] "%"  HVESP01
 SG_ HVESP01_brickSOC_153_2 m38: 8|14@1+ (1,0) [0|100] "%"  HVESP01
 SG_ HVESP01_brickSOC_154_2 m38: 22|14@1+ (1,0) [0|100] "%"  HVESP01
 SG_ HVESP01_brickSOC_155_2 m38: 36|14@1+ (1,0) [0|100] "%"  HVESP01
 SG_ HVESP01_brickSOC_156_2 m38: 50|14@1+ (1,0) [0|100] "%"  HVESP01
 SG_ HVESP01_brickSOC_157_2 m39: 8|14@1+ (1,0) [0|100] "%"  HVESP01
 SG_ HVESP01_brickSOC_158_2 m39: 22|14@1+ (1,0) [0|100] "%"  HVESP01
 SG_ HVESP01_brickSOC_159_2 m39: 36|14@1+ (1,0) [0|100] "%"  HVESP01
 SG_ HVESP01_brickSOC_160_2 m39: 50|14@1+ (1,0) [0|100] "%"  HVESP01
 SG_ HVESP01_brickSOC_161_2 m40: 8|14@1+ (1,0) [0|100] "%"  HVESP01
 SG_ HVESP01_brickSOC_162_2 m40: 22|14@1+ (1,0) [0|100] "%"  HVESP01
 SG_ HVESP01_brickSOC_163_2 m40: 36|14@1+ (1,0) [0|100] "%"  HVESP01
 SG_ HVESP01_brickSOC_164_2 m40: 50|14@1+ (1,0) [0|100] "%"  HVESP01
 SG_ HVESP01_brickSOC_165_2 m41: 8|14@1+ (1,0) [0|100] "%"  HVESP01
 SG_ HVESP01_brickSOC_166_2 m41: 22|14@1+ (1,0) [0|100] "%"  HVESP01
 SG_ HVESP01_brickSOC_167_2 m41: 36|14@1+ (1,0) [0|100] "%"  HVESP01
 SG_ HVESP01_brickSOC_168_2 m41: 50|14@1+ (1,0) [0|100] "%"  HVESP01
 SG_ HVESP01_brickSOC_169_2 m42: 8|14@1+ (1,0) [0|100] "%"  HVESP01
 SG_ HVESP01_brickSOC_170_2 m42: 22|14@1+ (1,0) [0|100] "%"  HVESP01
 SG_ HVESP01_brickSOC_171_2 m42: 36|14@1+ (1,0) [0|100] "%"  HVESP01
 SG_ HVESP01_brickSOC_172_2 m42: 50|14@1+ (1,0) [0|100] "%"  HVESP01
 SG_ HVESP01_brickSOC_173_2 m43: 8|14@1+ (1,0) [0|100] "%"  HVESP01
 SG_ HVESP01_brickSOC_174_2 m43: 22|14@1+ (1,0) [0|100] "%"  HVESP01
 SG_ HVESP01_brickSOC_175_2 m43: 36|14@1+ (1,0) [0|100] "%"  HVESP01
 SG_ HVESP01_brickSOC_176_2 m43: 50|14@1+ (1,0) [0|100] "%"  HVESP01
 SG_ HVESP01_brickSOC_177_2 m44: 8|14@1+ (1,0) [0|100] "%"  HVESP01
 SG_ HVESP01_brickSOC_178_2 m44: 22|14@1+ (1,0) [0|100] "%"  HVESP01
 SG_ HVESP01_brickSOC_179_2 m44: 36|14@1+ (1,0) [0|100] "%"  HVESP01
 SG_ HVESP01_brickSOC_180_2 m44: 50|14@1+ (1,0) [0|100] "%"  HVESP01
 SG_ HVESP01_brickSOC_181_2 m45: 8|14@1+ (1,0) [0|100] "%"  HVESP01
 SG_ HVESP01_brickSOC_182_2 m45: 22|14@1+ (1,0) [0|100] "%"  HVESP01
 SG_ HVESP01_brickSOC_183_2 m45: 36|14@1+ (1,0) [0|100] "%"  HVESP01
 SG_ HVESP01_brickSOC_184_2 m45: 50|14@1+ (1,0) [0|100] "%"  HVESP01
 SG_ HVESP01_brickSOC_185_2 m46: 8|14@1+ (1,0) [0|100] "%"  HVESP01
 SG_ HVESP01_brickSOC_186_2 m46: 22|14@1+ (1,0) [0|100] "%"  HVESP01
 SG_ HVESP01_brickSOC_187_2 m46: 36|14@1+ (1,0) [0|100] "%"  HVESP01
 SG_ HVESP01_brickSOC_188_2 m46: 50|14@1+ (1,0) [0|100] "%"  HVESP01
 SG_ HVESP01_brickSOC_189_2 m47: 8|14@1+ (1,0) [0|100] "%"  HVESP01
 SG_ HVESP01_brickSOC_190_2 m47: 22|14@1+ (1,0) [0|100] "%"  HVESP01
 SG_ HVESP01_brickSOC_191_2 m47: 36|14@1+ (1,0) [0|100] "%"  HVESP01
 SG_ HVESP01_brickSOC_192_2 m47: 50|14@1+ (1,0) [0|100] "%"  HVESP01
 SG_ multiplexorsoc_2 M: 0|8@1+ (1,0) [0|255] ""  HVESP01

BO_ 2499741031 HVESP01_brickSOC_3: 8 HVESP01
 SG_ HVESP01_brickSOC_01_3 m0: 8|14@1+ (1,0) [0|100] "%"  HVESP01
 SG_ HVESP01_brickSOC_02_3 m0: 22|14@1+ (1,0) [0|100] "%"  HVESP01
 SG_ HVESP01_brickSOC_03_3 m0: 36|14@1+ (1,0) [0|100] "%"  HVESP01
 SG_ HVESP01_brickSOC_04_3 m0: 50|14@1+ (1,0) [0|100] "%"  HVESP01
 SG_ HVESP01_brickSOC_05_3 m1: 8|14@1+ (1,0) [0|100] "%"  HVESP01
 SG_ HVESP01_brickSOC_06_3 m1: 22|14@1+ (1,0) [0|100] "%"  HVESP01
 SG_ HVESP01_brickSOC_07_3 m1: 36|14@1+ (1,0) [0|100] "%"  HVESP01
 SG_ HVESP01_brickSOC_08_3 m1: 50|14@1+ (1,0) [0|100] "%"  HVESP01
 SG_ HVESP01_brickSOC_09_3 m2: 8|14@1+ (1,0) [0|100] "%"  HVESP01
 SG_ HVESP01_brickSOC_10_3 m2: 22|14@1+ (1,0) [0|100] "%"  HVESP01
 SG_ HVESP01_brickSOC_11_3 m2: 36|14@1+ (1,0) [0|100] "%"  HVESP01
 SG_ HVESP01_brickSOC_12_3 m2: 50|14@1+ (1,0) [0|100] "%"  HVESP01
 SG_ HVESP01_brickSOC_13_3 m3: 8|14@1+ (1,0) [0|100] "%"  HVESP01
 SG_ HVESP01_brickSOC_14_3 m3: 22|14@1+ (1,0) [0|100] "%"  HVESP01
 SG_ HVESP01_brickSOC_15_3 m3: 36|14@1+ (1,0) [0|100] "%"  HVESP01
 SG_ HVESP01_brickSOC_16_3 m3: 50|14@1+ (1,0) [0|100] "%"  HVESP01
 SG_ HVESP01_brickSOC_17_3 m4: 8|14@1+ (1,0) [0|100] "%"  HVESP01
 SG_ HVESP01_brickSOC_18_3 m4: 22|14@1+ (1,0) [0|100] "%"  HVESP01
 SG_ HVESP01_brickSOC_19_3 m4: 36|14@1+ (1,0) [0|100] "%"  HVESP01
 SG_ HVESP01_brickSOC_20_3 m4: 50|14@1+ (1,0) [0|100] "%"  HVESP01
 SG_ HVESP01_brickSOC_21_3 m5: 8|14@1+ (1,0) [0|100] "%"  HVESP01
 SG_ HVESP01_brickSOC_22_3 m5: 22|14@1+ (1,0) [0|100] "%"  HVESP01
 SG_ HVESP01_brickSOC_23_3 m5: 36|14@1+ (1,0) [0|100] "%"  HVESP01
 SG_ HVESP01_brickSOC_24_3 m5: 50|14@1+ (1,0) [0|100] "%"  HVESP01
 SG_ HVESP01_brickSOC_25_3 m6: 8|14@1+ (1,0) [0|100] "%"  HVESP01
 SG_ HVESP01_brickSOC_26_3 m6: 22|14@1+ (1,0) [0|100] "%"  HVESP01
 SG_ HVESP01_brickSOC_27_3 m6: 36|14@1+ (1,0) [0|100] "%"  HVESP01
 SG_ HVESP01_brickSOC_28_3 m6: 50|14@1+ (1,0) [0|100] "%"  HVESP01
 SG_ HVESP01_brickSOC_29_3 m7: 8|14@1+ (1,0) [0|100] "%"  HVESP01
 SG_ HVESP01_brickSOC_30_3 m7: 22|14@1+ (1,0) [0|100] "%"  HVESP01
 SG_ HVESP01_brickSOC_31_3 m7: 36|14@1+ (1,0) [0|100] "%"  HVESP01
 SG_ HVESP01_brickSOC_32_3 m7: 50|14@1+ (1,0) [0|100] "%"  HVESP01
 SG_ HVESP01_brickSOC_33_3 m8: 8|14@1+ (1,0) [0|100] "%"  HVESP01
 SG_ HVESP01_brickSOC_34_3 m8: 22|14@1+ (1,0) [0|100] "%"  HVESP01
 SG_ HVESP01_brickSOC_35_3 m8: 36|14@1+ (1,0) [0|100] "%"  HVESP01
 SG_ HVESP01_brickSOC_36_3 m8: 50|14@1+ (1,0) [0|100] "%"  HVESP01
 SG_ HVESP01_brickSOC_37_3 m9: 8|14@1+ (1,0) [0|100] "%"  HVESP01
 SG_ HVESP01_brickSOC_38_3 m9: 22|14@1+ (1,0) [0|100] "%"  HVESP01
 SG_ HVESP01_brickSOC_39_3 m9: 36|14@1+ (1,0) [0|100] "%"  HVESP01
 SG_ HVESP01_brickSOC_40_3 m9: 50|14@1+ (1,0) [0|100] "%"  HVESP01
 SG_ HVESP01_brickSOC_41_3 m10: 8|14@1+ (1,0) [0|100] "%"  HVESP01
 SG_ HVESP01_brickSOC_42_3 m10: 22|14@1+ (1,0) [0|100] "%"  HVESP01
 SG_ HVESP01_brickSOC_43_3 m10: 36|14@1+ (1,0) [0|100] "%"  HVESP01
 SG_ HVESP01_brickSOC_44_3 m10: 50|14@1+ (1,0) [0|100] "%"  HVESP01
 SG_ HVESP01_brickSOC_45_3 m11: 8|14@1+ (1,0) [0|100] "%"  HVESP01
 SG_ HVESP01_brickSOC_46_3 m11: 22|14@1+ (1,0) [0|100] "%"  HVESP01
 SG_ HVESP01_brickSOC_47_3 m11: 36|14@1+ (1,0) [0|100] "%"  HVESP01
 SG_ HVESP01_brickSOC_48_3 m11: 50|14@1+ (1,0) [0|100] "%"  HVESP01
 SG_ HVESP01_brickSOC_49_3 m12: 8|14@1+ (1,0) [0|100] "%"  HVESP01
 SG_ HVESP01_brickSOC_50_3 m12: 22|14@1+ (1,0) [0|100] "%"  HVESP01
 SG_ HVESP01_brickSOC_51_3 m12: 36|14@1+ (1,0) [0|100] "%"  HVESP01
 SG_ HVESP01_brickSOC_52_3 m12: 50|14@1+ (1,0) [0|100] "%"  HVESP01
 SG_ HVESP01_brickSOC_53_3 m13: 8|14@1+ (1,0) [0|100] "%"  HVESP01
 SG_ HVESP01_brickSOC_54_3 m13: 22|14@1+ (1,0) [0|100] "%"  HVESP01
 SG_ HVESP01_brickSOC_55_3 m13: 36|14@1+ (1,0) [0|100] "%"  HVESP01
 SG_ HVESP01_brickSOC_56_3 m13: 50|14@1+ (1,0) [0|100] "%"  HVESP01
 SG_ HVESP01_brickSOC_57_3 m14: 8|14@1+ (1,0) [0|100] "%"  HVESP01
 SG_ HVESP01_brickSOC_58_3 m14: 22|14@1+ (1,0) [0|100] "%"  HVESP01
 SG_ HVESP01_brickSOC_59_3 m14: 36|14@1+ (1,0) [0|100] "%"  HVESP01
 SG_ HVESP01_brickSOC_60_3 m14: 50|14@1+ (1,0) [0|100] "%"  HVESP01
 SG_ HVESP01_brickSOC_61_3 m15: 8|14@1+ (1,0) [0|100] "%"  HVESP01
 SG_ HVESP01_brickSOC_62_3 m15: 22|14@1+ (1,0) [0|100] "%"  HVESP01
 SG_ HVESP01_brickSOC_63_3 m15: 36|14@1+ (1,0) [0|100] "%"  HVESP01
 SG_ HVESP01_brickSOC_64_3 m15: 50|14@1+ (1,0) [0|100] "%"  HVESP01
 SG_ HVESP01_brickSOC_65_3 m16: 8|14@1+ (1,0) [0|100] "%"  HVESP01
 SG_ HVESP01_brickSOC_66_3 m16: 22|14@1+ (1,0) [0|100] "%"  HVESP01
 SG_ HVESP01_brickSOC_67_3 m16: 36|14@1+ (1,0) [0|100] "%"  HVESP01
 SG_ HVESP01_brickSOC_68_3 m16: 50|14@1+ (1,0) [0|100] "%"  HVESP01
 SG_ HVESP01_brickSOC_69_3 m17: 8|14@1+ (1,0) [0|100] "%"  HVESP01
 SG_ HVESP01_brickSOC_70_3 m17: 22|14@1+ (1,0) [0|100] "%"  HVESP01
 SG_ HVESP01_brickSOC_71_3 m17: 36|14@1+ (1,0) [0|100] "%"  HVESP01
 SG_ HVESP01_brickSOC_72_3 m17: 50|14@1+ (1,0) [0|100] "%"  HVESP01
 SG_ HVESP01_brickSOC_73_3 m18: 8|14@1+ (1,0) [0|100] "%"  HVESP01
 SG_ HVESP01_brickSOC_74_3 m18: 22|14@1+ (1,0) [0|100] "%"  HVESP01
 SG_ HVESP01_brickSOC_75_3 m18: 36|14@1+ (1,0) [0|100] "%"  HVESP01
 SG_ HVESP01_brickSOC_76_3 m18: 50|14@1+ (1,0) [0|100] "%"  HVESP01
 SG_ HVESP01_brickSOC_77_3 m19: 8|14@1+ (1,0) [0|100] "%"  HVESP01
 SG_ HVESP01_brickSOC_78_3 m19: 22|14@1+ (1,0) [0|100] "%"  HVESP01
 SG_ HVESP01_brickSOC_79_3 m19: 36|14@1+ (1,0) [0|100] "%"  HVESP01
 SG_ HVESP01_brickSOC_80_3 m19: 50|14@1+ (1,0) [0|100] "%"  HVESP01
 SG_ HVESP01_brickSOC_81_3 m20: 8|14@1+ (1,0) [0|100] "%"  HVESP01
 SG_ HVESP01_brickSOC_82_3 m20: 22|14@1+ (1,0) [0|100] "%"  HVESP01
 SG_ HVESP01_brickSOC_83_3 m20: 36|14@1+ (1,0) [0|100] "%"  HVESP01
 SG_ HVESP01_brickSOC_84_3 m20: 50|14@1+ (1,0) [0|100] "%"  HVESP01
 SG_ HVESP01_brickSOC_85_3 m21: 8|14@1+ (1,0) [0|100] "%"  HVESP01
 SG_ HVESP01_brickSOC_86_3 m21: 22|14@1+ (1,0) [0|100] "%"  HVESP01
 SG_ HVESP01_brickSOC_87_3 m21: 36|14@1+ (1,0) [0|100] "%"  HVESP01
 SG_ HVESP01_brickSOC_88_3 m21: 50|14@1+ (1,0) [0|100] "%"  HVESP01
 SG_ HVESP01_brickSOC_89_3 m22: 8|14@1+ (1,0) [0|100] "%"  HVESP01
 SG_ HVESP01_brickSOC_90_3 m22: 22|14@1+ (1,0) [0|100] "%"  HVESP01
 SG_ HVESP01_brickSOC_91_3 m22: 36|14@1+ (1,0) [0|100] "%"  HVESP01
 SG_ HVESP01_brickSOC_92_3 m22: 50|14@1+ (1,0) [0|100] "%"  HVESP01
 SG_ HVESP01_brickSOC_93_3 m23: 8|14@1+ (1,0) [0|100] "%"  HVESP01
 SG_ HVESP01_brickSOC_94_3 m23: 22|14@1+ (1,0) [0|100] "%"  HVESP01
 SG_ HVESP01_brickSOC_95_3 m23: 36|14@1+ (1,0) [0|100] "%"  HVESP01
 SG_ HVESP01_brickSOC_96_3 m23: 50|14@1+ (1,0) [0|100] "%"  HVESP01
 SG_ HVESP01_brickSOC_97_3 m24: 8|14@1+ (1,0) [0|100] "%"  HVESP01
 SG_ HVESP01_brickSOC_98_3 m24: 22|14@1+ (1,0) [0|100] "%"  HVESP01
 SG_ HVESP01_brickSOC_99_3 m24: 36|14@1+ (1,0) [0|100] "%"  HVESP01
 SG_ HVESP01_brickSOC_100_3 m24: 50|14@1+ (1,0) [0|100] "%"  HVESP01
 SG_ HVESP01_brickSOC_101_3 m25: 8|14@1+ (1,0) [0|100] "%"  HVESP01
 SG_ HVESP01_brickSOC_102_3 m25: 22|14@1+ (1,0) [0|100] "%"  HVESP01
 SG_ HVESP01_brickSOC_103_3 m25: 36|14@1+ (1,0) [0|100] "%"  HVESP01
 SG_ HVESP01_brickSOC_104_3 m25: 50|14@1+ (1,0) [0|100] "%"  HVESP01
 SG_ HVESP01_brickSOC_105_3 m26: 8|14@1+ (1,0) [0|100] "%"  HVESP01
 SG_ HVESP01_brickSOC_106_3 m26: 22|14@1+ (1,0) [0|100] "%"  HVESP01
 SG_ HVESP01_brickSOC_107_3 m26: 36|14@1+ (1,0) [0|100] "%"  HVESP01
 SG_ HVESP01_brickSOC_108_3 m26: 50|14@1+ (1,0) [0|100] "%"  HVESP01
 SG_ HVESP01_brickSOC_109_3 m27: 8|14@1+ (1,0) [0|100] "%"  HVESP01
 SG_ HVESP01_brickSOC_110_3 m27: 22|14@1+ (1,0) [0|100] "%"  HVESP01
 SG_ HVESP01_brickSOC_111_3 m27: 36|14@1+ (1,0) [0|100] "%"  HVESP01
 SG_ HVESP01_brickSOC_112_3 m27: 50|14@1+ (1,0) [0|100] "%"  HVESP01
 SG_ HVESP01_brickSOC_113_3 m28: 8|14@1+ (1,0) [0|100] "%"  HVESP01
 SG_ HVESP01_brickSOC_114_3 m28: 22|14@1+ (1,0) [0|100] "%"  HVESP01
 SG_ HVESP01_brickSOC_115_3 m28: 36|14@1+ (1,0) [0|100] "%"  HVESP01
 SG_ HVESP01_brickSOC_116_3 m28: 50|14@1+ (1,0) [0|100] "%"  HVESP01
 SG_ HVESP01_brickSOC_117_3 m29: 8|14@1+ (1,0) [0|100] "%"  HVESP01
 SG_ HVESP01_brickSOC_118_3 m29: 22|14@1+ (1,0) [0|100] "%"  HVESP01
 SG_ HVESP01_brickSOC_119_3 m29: 36|14@1+ (1,0) [0|100] "%"  HVESP01
 SG_ HVESP01_brickSOC_120_3 m29: 50|14@1+ (1,0) [0|100] "%"  HVESP01
 SG_ HVESP01_brickSOC_121_3 m30: 8|14@1+ (1,0) [0|100] "%"  HVESP01
 SG_ HVESP01_brickSOC_122_3 m30: 22|14@1+ (1,0) [0|100] "%"  HVESP01
 SG_ HVESP01_brickSOC_123_3 m30: 36|14@1+ (1,0) [0|100] "%"  HVESP01
 SG_ HVESP01_brickSOC_124_3 m30: 50|14@1+ (1,0) [0|100] "%"  HVESP01
 SG_ HVESP01_brickSOC_125_3 m31: 8|14@1+ (1,0) [0|100] "%"  HVESP01
 SG_ HVESP01_brickSOC_126_3 m31: 22|14@1+ (1,0) [0|100] "%"  HVESP01
 SG_ HVESP01_brickSOC_127_3 m31: 36|14@1+ (1,0) [0|100] "%"  HVESP01
 SG_ HVESP01_brickSOC_128_3 m31: 50|14@1+ (1,0) [0|100] "%"  HVESP01
 SG_ HVESP01_brickSOC_129_3 m32: 8|14@1+ (1,0) [0|100] "%"  HVESP01
 SG_ HVESP01_brickSOC_130_3 m32: 22|14@1+ (1,0) [0|100] "%"  HVESP01
 SG_ HVESP01_brickSOC_131_3 m32: 36|14@1+ (1,0) [0|100] "%"  HVESP01
 SG_ HVESP01_brickSOC_132_3 m32: 50|14@1+ (1,0) [0|100] "%"  HVESP01
 SG_ HVESP01_brickSOC_133_3 m33: 8|14@1+ (1,0) [0|100] "%"  HVESP01
 SG_ HVESP01_brickSOC_134_3 m33: 22|14@1+ (1,0) [0|100] "%"  HVESP01
 SG_ HVESP01_brickSOC_135_3 m33: 36|14@1+ (1,0) [0|100] "%"  HVESP01
 SG_ HVESP01_brickSOC_136_3 m33: 50|14@1+ (1,0) [0|100] "%"  HVESP01
 SG_ HVESP01_brickSOC_137_3 m34: 8|14@1+ (1,0) [0|100] "%"  HVESP01
 SG_ HVESP01_brickSOC_138_3 m34: 22|14@1+ (1,0) [0|100] "%"  HVESP01
 SG_ HVESP01_brickSOC_139_3 m34: 36|14@1+ (1,0) [0|100] "%"  HVESP01
 SG_ HVESP01_brickSOC_140_3 m34: 50|14@1+ (1,0) [0|100] "%"  HVESP01
 SG_ HVESP01_brickSOC_141_3 m35: 8|14@1+ (1,0) [0|100] "%"  HVESP01
 SG_ HVESP01_brickSOC_142_3 m35: 22|14@1+ (1,0) [0|100] "%"  HVESP01
 SG_ HVESP01_brickSOC_143_3 m35: 36|14@1+ (1,0) [0|100] "%"  HVESP01
 SG_ HVESP01_brickSOC_144_3 m35: 50|14@1+ (1,0) [0|100] "%"  HVESP01
 SG_ HVESP01_brickSOC_145_3 m36: 8|14@1+ (1,0) [0|100] "%"  HVESP01
 SG_ HVESP01_brickSOC_146_3 m36: 22|14@1+ (1,0) [0|100] "%"  HVESP01
 SG_ HVESP01_brickSOC_147_3 m36: 36|14@1+ (1,0) [0|100] "%"  HVESP01
 SG_ HVESP01_brickSOC_148_3 m36: 50|14@1+ (1,0) [0|100] "%"  HVESP01
 SG_ HVESP01_brickSOC_149_3 m37: 8|14@1+ (1,0) [0|100] "%"  HVESP01
 SG_ HVESP01_brickSOC_150_3 m37: 22|14@1+ (1,0) [0|100] "%"  HVESP01
 SG_ HVESP01_brickSOC_151_3 m37: 36|14@1+ (1,0) [0|100] "%"  HVESP01
 SG_ HVESP01_brickSOC_152_3 m37: 50|14@1+ (1,0) [0|100] "%"  HVESP01
 SG_ HVESP01_brickSOC_153_3 m38: 8|14@1+ (1,0) [0|100] "%"  HVESP01
 SG_ HVESP01_brickSOC_154_3 m38: 22|14@1+ (1,0) [0|100] "%"  HVESP01
 SG_ HVESP01_brickSOC_155_3 m38: 36|14@1+ (1,0) [0|100] "%"  HVESP01
 SG_ HVESP01_brickSOC_156_3 m38: 50|14@1+ (1,0) [0|100] "%"  HVESP01
 SG_ HVESP01_brickSOC_157_3 m39: 8|14@1+ (1,0) [0|100] "%"  HVESP01
 SG_ HVESP01_brickSOC_158_3 m39: 22|14@1+ (1,0) [0|100] "%"  HVESP01
 SG_ HVESP01_brickSOC_159_3 m39: 36|14@1+ (1,0) [0|100] "%"  HVESP01
 SG_ HVESP01_brickSOC_160_3 m39: 50|14@1+ (1,0) [0|100] "%"  HVESP01
 SG_ HVESP01_brickSOC_161_3 m40: 8|14@1+ (1,0) [0|100] "%"  HVESP01
 SG_ HVESP01_brickSOC_162_3 m40: 22|14@1+ (1,0) [0|100] "%"  HVESP01
 SG_ HVESP01_brickSOC_163_3 m40: 36|14@1+ (1,0) [0|100] "%"  HVESP01
 SG_ HVESP01_brickSOC_164_3 m40: 50|14@1+ (1,0) [0|100] "%"  HVESP01
 SG_ HVESP01_brickSOC_165_3 m41: 8|14@1+ (1,0) [0|100] "%"  HVESP01
 SG_ HVESP01_brickSOC_166_3 m41: 22|14@1+ (1,0) [0|100] "%"  HVESP01
 SG_ HVESP01_brickSOC_167_3 m41: 36|14@1+ (1,0) [0|100] "%"  HVESP01
 SG_ HVESP01_brickSOC_168_3 m41: 50|14@1+ (1,0) [0|100] "%"  HVESP01
 SG_ HVESP01_brickSOC_169_3 m42: 8|14@1+ (1,0) [0|100] "%"  HVESP01
 SG_ HVESP01_brickSOC_170_3 m42: 22|14@1+ (1,0) [0|100] "%"  HVESP01
 SG_ HVESP01_brickSOC_171_3 m42: 36|14@1+ (1,0) [0|100] "%"  HVESP01
 SG_ HVESP01_brickSOC_172_3 m42: 50|14@1+ (1,0) [0|100] "%"  HVESP01
 SG_ HVESP01_brickSOC_173_3 m43: 8|14@1+ (1,0) [0|100] "%"  HVESP01
 SG_ HVESP01_brickSOC_174_3 m43: 22|14@1+ (1,0) [0|100] "%"  HVESP01
 SG_ HVESP01_brickSOC_175_3 m43: 36|14@1+ (1,0) [0|100] "%"  HVESP01
 SG_ HVESP01_brickSOC_176_3 m43: 50|14@1+ (1,0) [0|100] "%"  HVESP01
 SG_ HVESP01_brickSOC_177_3 m44: 8|14@1+ (1,0) [0|100] "%"  HVESP01
 SG_ HVESP01_brickSOC_178_3 m44: 22|14@1+ (1,0) [0|100] "%"  HVESP01
 SG_ HVESP01_brickSOC_179_3 m44: 36|14@1+ (1,0) [0|100] "%"  HVESP01
 SG_ HVESP01_brickSOC_180_3 m44: 50|14@1+ (1,0) [0|100] "%"  HVESP01
 SG_ HVESP01_brickSOC_181_3 m45: 8|14@1+ (1,0) [0|100] "%"  HVESP01
 SG_ HVESP01_brickSOC_182_3 m45: 22|14@1+ (1,0) [0|100] "%"  HVESP01
 SG_ HVESP01_brickSOC_183_3 m45: 36|14@1+ (1,0) [0|100] "%"  HVESP01
 SG_ HVESP01_brickSOC_184_3 m45: 50|14@1+ (1,0) [0|100] "%"  HVESP01
 SG_ HVESP01_brickSOC_185_3 m46: 8|14@1+ (1,0) [0|100] "%"  HVESP01
 SG_ HVESP01_brickSOC_186_3 m46: 22|14@1+ (1,0) [0|100] "%"  HVESP01
 SG_ HVESP01_brickSOC_187_3 m46: 36|14@1+ (1,0) [0|100] "%"  HVESP01
 SG_ HVESP01_brickSOC_188_3 m46: 50|14@1+ (1,0) [0|100] "%"  HVESP01
 SG_ HVESP01_brickSOC_189_3 m47: 8|14@1+ (1,0) [0|100] "%"  HVESP01
 SG_ HVESP01_brickSOC_190_3 m47: 22|14@1+ (1,0) [0|100] "%"  HVESP01
 SG_ HVESP01_brickSOC_191_3 m47: 36|14@1+ (1,0) [0|100] "%"  HVESP01
 SG_ HVESP01_brickSOC_192_3 m47: 50|14@1+ (1,0) [0|100] "%"  HVESP01
 SG_ multiplexorsoc_3 M: 0|8@1+ (1,0) [0|255] ""  HVESP01

BO_ 2499741032 HVESP01_brickSOC_4: 8 HVESP01
 SG_ HVESP01_brickSOC_01_4 m0: 8|14@1+ (1,0) [0|100] "%"  HVESP01
 SG_ HVESP01_brickSOC_02_4 m0: 22|14@1+ (1,0) [0|100] "%"  HVESP01
 SG_ HVESP01_brickSOC_03_4 m0: 36|14@1+ (1,0) [0|100] "%"  HVESP01
 SG_ HVESP01_brickSOC_04_4 m0: 50|14@1+ (1,0) [0|100] "%"  HVESP01
 SG_ HVESP01_brickSOC_05_4 m1: 8|14@1+ (1,0) [0|100] "%"  HVESP01
 SG_ HVESP01_brickSOC_06_4 m1: 22|14@1+ (1,0) [0|100] "%"  HVESP01
 SG_ HVESP01_brickSOC_07_4 m1: 36|14@1+ (1,0) [0|100] "%"  HVESP01
 SG_ HVESP01_brickSOC_08_4 m1: 50|14@1+ (1,0) [0|100] "%"  HVESP01
 SG_ HVESP01_brickSOC_09_4 m2: 8|14@1+ (1,0) [0|100] "%"  HVESP01
 SG_ HVESP01_brickSOC_10_4 m2: 22|14@1+ (1,0) [0|100] "%"  HVESP01
 SG_ HVESP01_brickSOC_11_4 m2: 36|14@1+ (1,0) [0|100] "%"  HVESP01
 SG_ HVESP01_brickSOC_12_4 m2: 50|14@1+ (1,0) [0|100] "%"  HVESP01
 SG_ HVESP01_brickSOC_13_4 m3: 8|14@1+ (1,0) [0|100] "%"  HVESP01
 SG_ HVESP01_brickSOC_14_4 m3: 22|14@1+ (1,0) [0|100] "%"  HVESP01
 SG_ HVESP01_brickSOC_15_4 m3: 36|14@1+ (1,0) [0|100] "%"  HVESP01
 SG_ HVESP01_brickSOC_16_4 m3: 50|14@1+ (1,0) [0|100] "%"  HVESP01
 SG_ HVESP01_brickSOC_17_4 m4: 8|14@1+ (1,0) [0|100] "%"  HVESP01
 SG_ HVESP01_brickSOC_18_4 m4: 22|14@1+ (1,0) [0|100] "%"  HVESP01
 SG_ HVESP01_brickSOC_19_4 m4: 36|14@1+ (1,0) [0|100] "%"  HVESP01
 SG_ HVESP01_brickSOC_20_4 m4: 50|14@1+ (1,0) [0|100] "%"  HVESP01
 SG_ HVESP01_brickSOC_21_4 m5: 8|14@1+ (1,0) [0|100] "%"  HVESP01
 SG_ HVESP01_brickSOC_22_4 m5: 22|14@1+ (1,0) [0|100] "%"  HVESP01
 SG_ HVESP01_brickSOC_23_4 m5: 36|14@1+ (1,0) [0|100] "%"  HVESP01
 SG_ HVESP01_brickSOC_24_4 m5: 50|14@1+ (1,0) [0|100] "%"  HVESP01
 SG_ HVESP01_brickSOC_25_4 m6: 8|14@1+ (1,0) [0|100] "%"  HVESP01
 SG_ HVESP01_brickSOC_26_4 m6: 22|14@1+ (1,0) [0|100] "%"  HVESP01
 SG_ HVESP01_brickSOC_27_4 m6: 36|14@1+ (1,0) [0|100] "%"  HVESP01
 SG_ HVESP01_brickSOC_28_4 m6: 50|14@1+ (1,0) [0|100] "%"  HVESP01
 SG_ HVESP01_brickSOC_29_4 m7: 8|14@1+ (1,0) [0|100] "%"  HVESP01
 SG_ HVESP01_brickSOC_30_4 m7: 22|14@1+ (1,0) [0|100] "%"  HVESP01
 SG_ HVESP01_brickSOC_31_4 m7: 36|14@1+ (1,0) [0|100] "%"  HVESP01
 SG_ HVESP01_brickSOC_32_4 m7: 50|14@1+ (1,0) [0|100] "%"  HVESP01
 SG_ HVESP01_brickSOC_33_4 m8: 8|14@1+ (1,0) [0|100] "%"  HVESP01
 SG_ HVESP01_brickSOC_34_4 m8: 22|14@1+ (1,0) [0|100] "%"  HVESP01
 SG_ HVESP01_brickSOC_35_4 m8: 36|14@1+ (1,0) [0|100] "%"  HVESP01
 SG_ HVESP01_brickSOC_36_4 m8: 50|14@1+ (1,0) [0|100] "%"  HVESP01
 SG_ HVESP01_brickSOC_37_4 m9: 8|14@1+ (1,0) [0|100] "%"  HVESP01
 SG_ HVESP01_brickSOC_38_4 m9: 22|14@1+ (1,0) [0|100] "%"  HVESP01
 SG_ HVESP01_brickSOC_39_4 m9: 36|14@1+ (1,0) [0|100] "%"  HVESP01
 SG_ HVESP01_brickSOC_40_4 m9: 50|14@1+ (1,0) [0|100] "%"  HVESP01
 SG_ HVESP01_brickSOC_41_4 m10: 8|14@1+ (1,0) [0|100] "%"  HVESP01
 SG_ HVESP01_brickSOC_42_4 m10: 22|14@1+ (1,0) [0|100] "%"  HVESP01
 SG_ HVESP01_brickSOC_43_4 m10: 36|14@1+ (1,0) [0|100] "%"  HVESP01
 SG_ HVESP01_brickSOC_44_4 m10: 50|14@1+ (1,0) [0|100] "%"  HVESP01
 SG_ HVESP01_brickSOC_45_4 m11: 8|14@1+ (1,0) [0|100] "%"  HVESP01
 SG_ HVESP01_brickSOC_46_4 m11: 22|14@1+ (1,0) [0|100] "%"  HVESP01
 SG_ HVESP01_brickSOC_47_4 m11: 36|14@1+ (1,0) [0|100] "%"  HVESP01
 SG_ HVESP01_brickSOC_48_4 m11: 50|14@1+ (1,0) [0|100] "%"  HVESP01
 SG_ HVESP01_brickSOC_49_4 m12: 8|14@1+ (1,0) [0|100] "%"  HVESP01
 SG_ HVESP01_brickSOC_50_4 m12: 22|14@1+ (1,0) [0|100] "%"  HVESP01
 SG_ HVESP01_brickSOC_51_4 m12: 36|14@1+ (1,0) [0|100] "%"  HVESP01
 SG_ HVESP01_brickSOC_52_4 m12: 50|14@1+ (1,0) [0|100] "%"  HVESP01
 SG_ HVESP01_brickSOC_53_4 m13: 8|14@1+ (1,0) [0|100] "%"  HVESP01
 SG_ HVESP01_brickSOC_54_4 m13: 22|14@1+ (1,0) [0|100] "%"  HVESP01
 SG_ HVESP01_brickSOC_55_4 m13: 36|14@1+ (1,0) [0|100] "%"  HVESP01
 SG_ HVESP01_brickSOC_56_4 m13: 50|14@1+ (1,0) [0|100] "%"  HVESP01
 SG_ HVESP01_brickSOC_57_4 m14: 8|14@1+ (1,0) [0|100] "%"  HVESP01
 SG_ HVESP01_brickSOC_58_4 m14: 22|14@1+ (1,0) [0|100] "%"  HVESP01
 SG_ HVESP01_brickSOC_59_4 m14: 36|14@1+ (1,0) [0|100] "%"  HVESP01
 SG_ HVESP01_brickSOC_60_4 m14: 50|14@1+ (1,0) [0|100] "%"  HVESP01
 SG_ HVESP01_brickSOC_61_4 m15: 8|14@1+ (1,0) [0|100] "%"  HVESP01
 SG_ HVESP01_brickSOC_62_4 m15: 22|14@1+ (1,0) [0|100] "%"  HVESP01
 SG_ HVESP01_brickSOC_63_4 m15: 36|14@1+ (1,0) [0|100] "%"  HVESP01
 SG_ HVESP01_brickSOC_64_4 m15: 50|14@1+ (1,0) [0|100] "%"  HVESP01
 SG_ HVESP01_brickSOC_65_4 m16: 8|14@1+ (1,0) [0|100] "%"  HVESP01
 SG_ HVESP01_brickSOC_66_4 m16: 22|14@1+ (1,0) [0|100] "%"  HVESP01
 SG_ HVESP01_brickSOC_67_4 m16: 36|14@1+ (1,0) [0|100] "%"  HVESP01
 SG_ HVESP01_brickSOC_68_4 m16: 50|14@1+ (1,0) [0|100] "%"  HVESP01
 SG_ HVESP01_brickSOC_69_4 m17: 8|14@1+ (1,0) [0|100] "%"  HVESP01
 SG_ HVESP01_brickSOC_70_4 m17: 22|14@1+ (1,0) [0|100] "%"  HVESP01
 SG_ HVESP01_brickSOC_71_4 m17: 36|14@1+ (1,0) [0|100] "%"  HVESP01
 SG_ HVESP01_brickSOC_72_4 m17: 50|14@1+ (1,0) [0|100] "%"  HVESP01
 SG_ HVESP01_brickSOC_73_4 m18: 8|14@1+ (1,0) [0|100] "%"  HVESP01
 SG_ HVESP01_brickSOC_74_4 m18: 22|14@1+ (1,0) [0|100] "%"  HVESP01
 SG_ HVESP01_brickSOC_75_4 m18: 36|14@1+ (1,0) [0|100] "%"  HVESP01
 SG_ HVESP01_brickSOC_76_4 m18: 50|14@1+ (1,0) [0|100] "%"  HVESP01
 SG_ HVESP01_brickSOC_77_4 m19: 8|14@1+ (1,0) [0|100] "%"  HVESP01
 SG_ HVESP01_brickSOC_78_4 m19: 22|14@1+ (1,0) [0|100] "%"  HVESP01
 SG_ HVESP01_brickSOC_79_4 m19: 36|14@1+ (1,0) [0|100] "%"  HVESP01
 SG_ HVESP01_brickSOC_80_4 m19: 50|14@1+ (1,0) [0|100] "%"  HVESP01
 SG_ HVESP01_brickSOC_81_4 m20: 8|14@1+ (1,0) [0|100] "%"  HVESP01
 SG_ HVESP01_brickSOC_82_4 m20: 22|14@1+ (1,0) [0|100] "%"  HVESP01
 SG_ HVESP01_brickSOC_83_4 m20: 36|14@1+ (1,0) [0|100] "%"  HVESP01
 SG_ HVESP01_brickSOC_84_4 m20: 50|14@1+ (1,0) [0|100] "%"  HVESP01
 SG_ HVESP01_brickSOC_85_4 m21: 8|14@1+ (1,0) [0|100] "%"  HVESP01
 SG_ HVESP01_brickSOC_86_4 m21: 22|14@1+ (1,0) [0|100] "%"  HVESP01
 SG_ HVESP01_brickSOC_87_4 m21: 36|14@1+ (1,0) [0|100] "%"  HVESP01
 SG_ HVESP01_brickSOC_88_4 m21: 50|14@1+ (1,0) [0|100] "%"  HVESP01
 SG_ HVESP01_brickSOC_89_4 m22: 8|14@1+ (1,0) [0|100] "%"  HVESP01
 SG_ HVESP01_brickSOC_90_4 m22: 22|14@1+ (1,0) [0|100] "%"  HVESP01
 SG_ HVESP01_brickSOC_91_4 m22: 36|14@1+ (1,0) [0|100] "%"  HVESP01
 SG_ HVESP01_brickSOC_92_4 m22: 50|14@1+ (1,0) [0|100] "%"  HVESP01
 SG_ HVESP01_brickSOC_93_4 m23: 8|14@1+ (1,0) [0|100] "%"  HVESP01
 SG_ HVESP01_brickSOC_94_4 m23: 22|14@1+ (1,0) [0|100] "%"  HVESP01
 SG_ HVESP01_brickSOC_95_4 m23: 36|14@1+ (1,0) [0|100] "%"  HVESP01
 SG_ HVESP01_brickSOC_96_4 m23: 50|14@1+ (1,0) [0|100] "%"  HVESP01
 SG_ HVESP01_brickSOC_97_4 m24: 8|14@1+ (1,0) [0|100] "%"  HVESP01
 SG_ HVESP01_brickSOC_98_4 m24: 22|14@1+ (1,0) [0|100] "%"  HVESP01
 SG_ HVESP01_brickSOC_99_4 m24: 36|14@1+ (1,0) [0|100] "%"  HVESP01
 SG_ HVESP01_brickSOC_100_4 m24: 50|14@1+ (1,0) [0|100] "%"  HVESP01
 SG_ HVESP01_brickSOC_101_4 m25: 8|14@1+ (1,0) [0|100] "%"  HVESP01
 SG_ HVESP01_brickSOC_102_4 m25: 22|14@1+ (1,0) [0|100] "%"  HVESP01
 SG_ HVESP01_brickSOC_103_4 m25: 36|14@1+ (1,0) [0|100] "%"  HVESP01
 SG_ HVESP01_brickSOC_104_4 m25: 50|14@1+ (1,0) [0|100] "%"  HVESP01
 SG_ HVESP01_brickSOC_105_4 m26: 8|14@1+ (1,0) [0|100] "%"  HVESP01
 SG_ HVESP01_brickSOC_106_4 m26: 22|14@1+ (1,0) [0|100] "%"  HVESP01
 SG_ HVESP01_brickSOC_107_4 m26: 36|14@1+ (1,0) [0|100] "%"  HVESP01
 SG_ HVESP01_brickSOC_108_4 m26: 50|14@1+ (1,0) [0|100] "%"  HVESP01
 SG_ HVESP01_brickSOC_109_4 m27: 8|14@1+ (1,0) [0|100] "%"  HVESP01
 SG_ HVESP01_brickSOC_110_4 m27: 22|14@1+ (1,0) [0|100] "%"  HVESP01
 SG_ HVESP01_brickSOC_111_4 m27: 36|14@1+ (1,0) [0|100] "%"  HVESP01
 SG_ HVESP01_brickSOC_112_4 m27: 50|14@1+ (1,0) [0|100] "%"  HVESP01
 SG_ HVESP01_brickSOC_113_4 m28: 8|14@1+ (1,0) [0|100] "%"  HVESP01
 SG_ HVESP01_brickSOC_114_4 m28: 22|14@1+ (1,0) [0|100] "%"  HVESP01
 SG_ HVESP01_brickSOC_115_4 m28: 36|14@1+ (1,0) [0|100] "%"  HVESP01
 SG_ HVESP01_brickSOC_116_4 m28: 50|14@1+ (1,0) [0|100] "%"  HVESP01
 SG_ HVESP01_brickSOC_117_4 m29: 8|14@1+ (1,0) [0|100] "%"  HVESP01
 SG_ HVESP01_brickSOC_118_4 m29: 22|14@1+ (1,0) [0|100] "%"  HVESP01
 SG_ HVESP01_brickSOC_119_4 m29: 36|14@1+ (1,0) [0|100] "%"  HVESP01
 SG_ HVESP01_brickSOC_120_4 m29: 50|14@1+ (1,0) [0|100] "%"  HVESP01
 SG_ HVESP01_brickSOC_121_4 m30: 8|14@1+ (1,0) [0|100] "%"  HVESP01
 SG_ HVESP01_brickSOC_122_4 m30: 22|14@1+ (1,0) [0|100] "%"  HVESP01
 SG_ HVESP01_brickSOC_123_4 m30: 36|14@1+ (1,0) [0|100] "%"  HVESP01
 SG_ HVESP01_brickSOC_124_4 m30: 50|14@1+ (1,0) [0|100] "%"  HVESP01
 SG_ HVESP01_brickSOC_125_4 m31: 8|14@1+ (1,0) [0|100] "%"  HVESP01
 SG_ HVESP01_brickSOC_126_4 m31: 22|14@1+ (1,0) [0|100] "%"  HVESP01
 SG_ HVESP01_brickSOC_127_4 m31: 36|14@1+ (1,0) [0|100] "%"  HVESP01
 SG_ HVESP01_brickSOC_128_4 m31: 50|14@1+ (1,0) [0|100] "%"  HVESP01
 SG_ HVESP01_brickSOC_129_4 m32: 8|14@1+ (1,0) [0|100] "%"  HVESP01
 SG_ HVESP01_brickSOC_130_4 m32: 22|14@1+ (1,0) [0|100] "%"  HVESP01
 SG_ HVESP01_brickSOC_131_4 m32: 36|14@1+ (1,0) [0|100] "%"  HVESP01
 SG_ HVESP01_brickSOC_132_4 m32: 50|14@1+ (1,0) [0|100] "%"  HVESP01
 SG_ HVESP01_brickSOC_133_4 m33: 8|14@1+ (1,0) [0|100] "%"  HVESP01
 SG_ HVESP01_brickSOC_134_4 m33: 22|14@1+ (1,0) [0|100] "%"  HVESP01
 SG_ HVESP01_brickSOC_135_4 m33: 36|14@1+ (1,0) [0|100] "%"  HVESP01
 SG_ HVESP01_brickSOC_136_4 m33: 50|14@1+ (1,0) [0|100] "%"  HVESP01
 SG_ HVESP01_brickSOC_137_4 m34: 8|14@1+ (1,0) [0|100] "%"  HVESP01
 SG_ HVESP01_brickSOC_138_4 m34: 22|14@1+ (1,0) [0|100] "%"  HVESP01
 SG_ HVESP01_brickSOC_139_4 m34: 36|14@1+ (1,0) [0|100] "%"  HVESP01
 SG_ HVESP01_brickSOC_140_4 m34: 50|14@1+ (1,0) [0|100] "%"  HVESP01
 SG_ HVESP01_brickSOC_141_4 m35: 8|14@1+ (1,0) [0|100] "%"  HVESP01
 SG_ HVESP01_brickSOC_142_4 m35: 22|14@1+ (1,0) [0|100] "%"  HVESP01
 SG_ HVESP01_brickSOC_143_4 m35: 36|14@1+ (1,0) [0|100] "%"  HVESP01
 SG_ HVESP01_brickSOC_144_4 m35: 50|14@1+ (1,0) [0|100] "%"  HVESP01
 SG_ HVESP01_brickSOC_145_4 m36: 8|14@1+ (1,0) [0|100] "%"  HVESP01
 SG_ HVESP01_brickSOC_146_4 m36: 22|14@1+ (1,0) [0|100] "%"  HVESP01
 SG_ HVESP01_brickSOC_147_4 m36: 36|14@1+ (1,0) [0|100] "%"  HVESP01
 SG_ HVESP01_brickSOC_148_4 m36: 50|14@1+ (1,0) [0|100] "%"  HVESP01
 SG_ HVESP01_brickSOC_149_4 m37: 8|14@1+ (1,0) [0|100] "%"  HVESP01
 SG_ HVESP01_brickSOC_150_4 m37: 22|14@1+ (1,0) [0|100] "%"  HVESP01
 SG_ HVESP01_brickSOC_151_4 m37: 36|14@1+ (1,0) [0|100] "%"  HVESP01
 SG_ HVESP01_brickSOC_152_4 m37: 50|14@1+ (1,0) [0|100] "%"  HVESP01
 SG_ HVESP01_brickSOC_153_4 m38: 8|14@1+ (1,0) [0|100] "%"  HVESP01
 SG_ HVESP01_brickSOC_154_4 m38: 22|14@1+ (1,0) [0|100] "%"  HVESP01
 SG_ HVESP01_brickSOC_155_4 m38: 36|14@1+ (1,0) [0|100] "%"  HVESP01
 SG_ HVESP01_brickSOC_156_4 m38: 50|14@1+ (1,0) [0|100] "%"  HVESP01
 SG_ HVESP01_brickSOC_157_4 m39: 8|14@1+ (1,0) [0|100] "%"  HVESP01
 SG_ HVESP01_brickSOC_158_4 m39: 22|14@1+ (1,0) [0|100] "%"  HVESP01
 SG_ HVESP01_brickSOC_159_4 m39: 36|14@1+ (1,0) [0|100] "%"  HVESP01
 SG_ HVESP01_brickSOC_160_4 m39: 50|14@1+ (1,0) [0|100] "%"  HVESP01
 SG_ HVESP01_brickSOC_161_4 m40: 8|14@1+ (1,0) [0|100] "%"  HVESP01
 SG_ HVESP01_brickSOC_162_4 m40: 22|14@1+ (1,0) [0|100] "%"  HVESP01
 SG_ HVESP01_brickSOC_163_4 m40: 36|14@1+ (1,0) [0|100] "%"  HVESP01
 SG_ HVESP01_brickSOC_164_4 m40: 50|14@1+ (1,0) [0|100] "%"  HVESP01
 SG_ HVESP01_brickSOC_165_4 m41: 8|14@1+ (1,0) [0|100] "%"  HVESP01
 SG_ HVESP01_brickSOC_166_4 m41: 22|14@1+ (1,0) [0|100] "%"  HVESP01
 SG_ HVESP01_brickSOC_167_4 m41: 36|14@1+ (1,0) [0|100] "%"  HVESP01
 SG_ HVESP01_brickSOC_168_4 m41: 50|14@1+ (1,0) [0|100] "%"  HVESP01
 SG_ HVESP01_brickSOC_169_4 m42: 8|14@1+ (1,0) [0|100] "%"  HVESP01
 SG_ HVESP01_brickSOC_170_4 m42: 22|14@1+ (1,0) [0|100] "%"  HVESP01
 SG_ HVESP01_brickSOC_171_4 m42: 36|14@1+ (1,0) [0|100] "%"  HVESP01
 SG_ HVESP01_brickSOC_172_4 m42: 50|14@1+ (1,0) [0|100] "%"  HVESP01
 SG_ HVESP01_brickSOC_173_4 m43: 8|14@1+ (1,0) [0|100] "%"  HVESP01
 SG_ HVESP01_brickSOC_174_4 m43: 22|14@1+ (1,0) [0|100] "%"  HVESP01
 SG_ HVESP01_brickSOC_175_4 m43: 36|14@1+ (1,0) [0|100] "%"  HVESP01
 SG_ HVESP01_brickSOC_176_4 m43: 50|14@1+ (1,0) [0|100] "%"  HVESP01
 SG_ HVESP01_brickSOC_177_4 m44: 8|14@1+ (1,0) [0|100] "%"  HVESP01
 SG_ HVESP01_brickSOC_178_4 m44: 22|14@1+ (1,0) [0|100] "%"  HVESP01
 SG_ HVESP01_brickSOC_179_4 m44: 36|14@1+ (1,0) [0|100] "%"  HVESP01
 SG_ HVESP01_brickSOC_180_4 m44: 50|14@1+ (1,0) [0|100] "%"  HVESP01
 SG_ HVESP01_brickSOC_181_4 m45: 8|14@1+ (1,0) [0|100] "%"  HVESP01
 SG_ HVESP01_brickSOC_182_4 m45: 22|14@1+ (1,0) [0|100] "%"  HVESP01
 SG_ HVESP01_brickSOC_183_4 m45: 36|14@1+ (1,0) [0|100] "%"  HVESP01
 SG_ HVESP01_brickSOC_184_4 m45: 50|14@1+ (1,0) [0|100] "%"  HVESP01
 SG_ HVESP01_brickSOC_185_4 m46: 8|14@1+ (1,0) [0|100] "%"  HVESP01
 SG_ HVESP01_brickSOC_186_4 m46: 22|14@1+ (1,0) [0|100] "%"  HVESP01
 SG_ HVESP01_brickSOC_187_4 m46: 36|14@1+ (1,0) [0|100] "%"  HVESP01
 SG_ HVESP01_brickSOC_188_4 m46: 50|14@1+ (1,0) [0|100] "%"  HVESP01
 SG_ HVESP01_brickSOC_189_4 m47: 8|14@1+ (1,0) [0|100] "%"  HVESP01
 SG_ HVESP01_brickSOC_190_4 m47: 22|14@1+ (1,0) [0|100] "%"  HVESP01
 SG_ HVESP01_brickSOC_191_4 m47: 36|14@1+ (1,0) [0|100] "%"  HVESP01
 SG_ HVESP01_brickSOC_192_4 m47: 50|14@1+ (1,0) [0|100] "%"  HVESP01
 SG_ multiplexorsoc_4 M: 0|8@1+ (1,0) [0|255] ""  HVESP01

BO_ 2499741033 HVESP01_brickSOC_5: 8 HVESP01
 SG_ HVESP01_brickSOC_01_5 m0: 8|14@1+ (1,0) [0|100] "%"  HVESP01
 SG_ HVESP01_brickSOC_02_5 m0: 22|14@1+ (1,0) [0|100] "%"  HVESP01
 SG_ HVESP01_brickSOC_03_5 m0: 36|14@1+ (1,0) [0|100] "%"  HVESP01
 SG_ HVESP01_brickSOC_04_5 m0: 50|14@1+ (1,0) [0|100] "%"  HVESP01
 SG_ HVESP01_brickSOC_05_5 m1: 8|14@1+ (1,0) [0|100] "%"  HVESP01
 SG_ HVESP01_brickSOC_06_5 m1: 22|14@1+ (1,0) [0|100] "%"  HVESP01
 SG_ HVESP01_brickSOC_07_5 m1: 36|14@1+ (1,0) [0|100] "%"  HVESP01
 SG_ HVESP01_brickSOC_08_5 m1: 50|14@1+ (1,0) [0|100] "%"  HVESP01
 SG_ HVESP01_brickSOC_09_5 m2: 8|14@1+ (1,0) [0|100] "%"  HVESP01
 SG_ HVESP01_brickSOC_10_5 m2: 22|14@1+ (1,0) [0|100] "%"  HVESP01
 SG_ HVESP01_brickSOC_11_5 m2: 36|14@1+ (1,0) [0|100] "%"  HVESP01
 SG_ HVESP01_brickSOC_12_5 m2: 50|14@1+ (1,0) [0|100] "%"  HVESP01
 SG_ HVESP01_brickSOC_13_5 m3: 8|14@1+ (1,0) [0|100] "%"  HVESP01
 SG_ HVESP01_brickSOC_14_5 m3: 22|14@1+ (1,0) [0|100] "%"  HVESP01
 SG_ HVESP01_brickSOC_15_5 m3: 36|14@1+ (1,0) [0|100] "%"  HVESP01
 SG_ HVESP01_brickSOC_16_5 m3: 50|14@1+ (1,0) [0|100] "%"  HVESP01
 SG_ HVESP01_brickSOC_17_5 m4: 8|14@1+ (1,0) [0|100] "%"  HVESP01
 SG_ HVESP01_brickSOC_18_5 m4: 22|14@1+ (1,0) [0|100] "%"  HVESP01
 SG_ HVESP01_brickSOC_19_5 m4: 36|14@1+ (1,0) [0|100] "%"  HVESP01
 SG_ HVESP01_brickSOC_20_5 m4: 50|14@1+ (1,0) [0|100] "%"  HVESP01
 SG_ HVESP01_brickSOC_21_5 m5: 8|14@1+ (1,0) [0|100] "%"  HVESP01
 SG_ HVESP01_brickSOC_22_5 m5: 22|14@1+ (1,0) [0|100] "%"  HVESP01
 SG_ HVESP01_brickSOC_23_5 m5: 36|14@1+ (1,0) [0|100] "%"  HVESP01
 SG_ HVESP01_brickSOC_24_5 m5: 50|14@1+ (1,0) [0|100] "%"  HVESP01
 SG_ HVESP01_brickSOC_25_5 m6: 8|14@1+ (1,0) [0|100] "%"  HVESP01
 SG_ HVESP01_brickSOC_26_5 m6: 22|14@1+ (1,0) [0|100] "%"  HVESP01
 SG_ HVESP01_brickSOC_27_5 m6: 36|14@1+ (1,0) [0|100] "%"  HVESP01
 SG_ HVESP01_brickSOC_28_5 m6: 50|14@1+ (1,0) [0|100] "%"  HVESP01
 SG_ HVESP01_brickSOC_29_5 m7: 8|14@1+ (1,0) [0|100] "%"  HVESP01
 SG_ HVESP01_brickSOC_30_5 m7: 22|14@1+ (1,0) [0|100] "%"  HVESP01
 SG_ HVESP01_brickSOC_31_5 m7: 36|14@1+ (1,0) [0|100] "%"  HVESP01
 SG_ HVESP01_brickSOC_32_5 m7: 50|14@1+ (1,0) [0|100] "%"  HVESP01
 SG_ HVESP01_brickSOC_33_5 m8: 8|14@1+ (1,0) [0|100] "%"  HVESP01
 SG_ HVESP01_brickSOC_34_5 m8: 22|14@1+ (1,0) [0|100] "%"  HVESP01
 SG_ HVESP01_brickSOC_35_5 m8: 36|14@1+ (1,0) [0|100] "%"  HVESP01
 SG_ HVESP01_brickSOC_36_5 m8: 50|14@1+ (1,0) [0|100] "%"  HVESP01
 SG_ HVESP01_brickSOC_37_5 m9: 8|14@1+ (1,0) [0|100] "%"  HVESP01
 SG_ HVESP01_brickSOC_38_5 m9: 22|14@1+ (1,0) [0|100] "%"  HVESP01
 SG_ HVESP01_brickSOC_39_5 m9: 36|14@1+ (1,0) [0|100] "%"  HVESP01
 SG_ HVESP01_brickSOC_40_5 m9: 50|14@1+ (1,0) [0|100] "%"  HVESP01
 SG_ HVESP01_brickSOC_41_5 m10: 8|14@1+ (1,0) [0|100] "%"  HVESP01
 SG_ HVESP01_brickSOC_42_5 m10: 22|14@1+ (1,0) [0|100] "%"  HVESP01
 SG_ HVESP01_brickSOC_43_5 m10: 36|14@1+ (1,0) [0|100] "%"  HVESP01
 SG_ HVESP01_brickSOC_44_5 m10: 50|14@1+ (1,0) [0|100] "%"  HVESP01
 SG_ HVESP01_brickSOC_45_5 m11: 8|14@1+ (1,0) [0|100] "%"  HVESP01
 SG_ HVESP01_brickSOC_46_5 m11: 22|14@1+ (1,0) [0|100] "%"  HVESP01
 SG_ HVESP01_brickSOC_47_5 m11: 36|14@1+ (1,0) [0|100] "%"  HVESP01
 SG_ HVESP01_brickSOC_48_5 m11: 50|14@1+ (1,0) [0|100] "%"  HVESP01
 SG_ HVESP01_brickSOC_49_5 m12: 8|14@1+ (1,0) [0|100] "%"  HVESP01
 SG_ HVESP01_brickSOC_50_5 m12: 22|14@1+ (1,0) [0|100] "%"  HVESP01
 SG_ HVESP01_brickSOC_51_5 m12: 36|14@1+ (1,0) [0|100] "%"  HVESP01
 SG_ HVESP01_brickSOC_52_5 m12: 50|14@1+ (1,0) [0|100] "%"  HVESP01
 SG_ HVESP01_brickSOC_53_5 m13: 8|14@1+ (1,0) [0|100] "%"  HVESP01
 SG_ HVESP01_brickSOC_54_5 m13: 22|14@1+ (1,0) [0|100] "%"  HVESP01
 SG_ HVESP01_brickSOC_55_5 m13: 36|14@1+ (1,0) [0|100] "%"  HVESP01
 SG_ HVESP01_brickSOC_56_5 m13: 50|14@1+ (1,0) [0|100] "%"  HVESP01
 SG_ HVESP01_brickSOC_57_5 m14: 8|14@1+ (1,0) [0|100] "%"  HVESP01
 SG_ HVESP01_brickSOC_58_5 m14: 22|14@1+ (1,0) [0|100] "%"  HVESP01
 SG_ HVESP01_brickSOC_59_5 m14: 36|14@1+ (1,0) [0|100] "%"  HVESP01
 SG_ HVESP01_brickSOC_60_5 m14: 50|14@1+ (1,0) [0|100] "%"  HVESP01
 SG_ HVESP01_brickSOC_61_5 m15: 8|14@1+ (1,0) [0|100] "%"  HVESP01
 SG_ HVESP01_brickSOC_62_5 m15: 22|14@1+ (1,0) [0|100] "%"  HVESP01
 SG_ HVESP01_brickSOC_63_5 m15: 36|14@1+ (1,0) [0|100] "%"  HVESP01
 SG_ HVESP01_brickSOC_64_5 m15: 50|14@1+ (1,0) [0|100] "%"  HVESP01
 SG_ HVESP01_brickSOC_65_5 m16: 8|14@1+ (1,0) [0|100] "%"  HVESP01
 SG_ HVESP01_brickSOC_66_5 m16: 22|14@1+ (1,0) [0|100] "%"  HVESP01
 SG_ HVESP01_brickSOC_67_5 m16: 36|14@1+ (1,0) [0|100] "%"  HVESP01
 SG_ HVESP01_brickSOC_68_5 m16: 50|14@1+ (1,0) [0|100] "%"  HVESP01
 SG_ HVESP01_brickSOC_69_5 m17: 8|14@1+ (1,0) [0|100] "%"  HVESP01
 SG_ HVESP01_brickSOC_70_5 m17: 22|14@1+ (1,0) [0|100] "%"  HVESP01
 SG_ HVESP01_brickSOC_71_5 m17: 36|14@1+ (1,0) [0|100] "%"  HVESP01
 SG_ HVESP01_brickSOC_72_5 m17: 50|14@1+ (1,0) [0|100] "%"  HVESP01
 SG_ HVESP01_brickSOC_73_5 m18: 8|14@1+ (1,0) [0|100] "%"  HVESP01
 SG_ HVESP01_brickSOC_74_5 m18: 22|14@1+ (1,0) [0|100] "%"  HVESP01
 SG_ HVESP01_brickSOC_75_5 m18: 36|14@1+ (1,0) [0|100] "%"  HVESP01
 SG_ HVESP01_brickSOC_76_5 m18: 50|14@1+ (1,0) [0|100] "%"  HVESP01
 SG_ HVESP01_brickSOC_77_5 m19: 8|14@1+ (1,0) [0|100] "%"  HVESP01
 SG_ HVESP01_brickSOC_78_5 m19: 22|14@1+ (1,0) [0|100] "%"  HVESP01
 SG_ HVESP01_brickSOC_79_5 m19: 36|14@1+ (1,0) [0|100] "%"  HVESP01
 SG_ HVESP01_brickSOC_80_5 m19: 50|14@1+ (1,0) [0|100] "%"  HVESP01
 SG_ HVESP01_brickSOC_81_5 m20: 8|14@1+ (1,0) [0|100] "%"  HVESP01
 SG_ HVESP01_brickSOC_82_5 m20: 22|14@1+ (1,0) [0|100] "%"  HVESP01
 SG_ HVESP01_brickSOC_83_5 m20: 36|14@1+ (1,0) [0|100] "%"  HVESP01
 SG_ HVESP01_brickSOC_84_5 m20: 50|14@1+ (1,0) [0|100] "%"  HVESP01
 SG_ HVESP01_brickSOC_85_5 m21: 8|14@1+ (1,0) [0|100] "%"  HVESP01
 SG_ HVESP01_brickSOC_86_5 m21: 22|14@1+ (1,0) [0|100] "%"  HVESP01
 SG_ HVESP01_brickSOC_87_5 m21: 36|14@1+ (1,0) [0|100] "%"  HVESP01
 SG_ HVESP01_brickSOC_88_5 m21: 50|14@1+ (1,0) [0|100] "%"  HVESP01
 SG_ HVESP01_brickSOC_89_5 m22: 8|14@1+ (1,0) [0|100] "%"  HVESP01
 SG_ HVESP01_brickSOC_90_5 m22: 22|14@1+ (1,0) [0|100] "%"  HVESP01
 SG_ HVESP01_brickSOC_91_5 m22: 36|14@1+ (1,0) [0|100] "%"  HVESP01
 SG_ HVESP01_brickSOC_92_5 m22: 50|14@1+ (1,0) [0|100] "%"  HVESP01
 SG_ HVESP01_brickSOC_93_5 m23: 8|14@1+ (1,0) [0|100] "%"  HVESP01
 SG_ HVESP01_brickSOC_94_5 m23: 22|14@1+ (1,0) [0|100] "%"  HVESP01
 SG_ HVESP01_brickSOC_95_5 m23: 36|14@1+ (1,0) [0|100] "%"  HVESP01
 SG_ HVESP01_brickSOC_96_5 m23: 50|14@1+ (1,0) [0|100] "%"  HVESP01
 SG_ HVESP01_brickSOC_97_5 m24: 8|14@1+ (1,0) [0|100] "%"  HVESP01
 SG_ HVESP01_brickSOC_98_5 m24: 22|14@1+ (1,0) [0|100] "%"  HVESP01
 SG_ HVESP01_brickSOC_99_5 m24: 36|14@1+ (1,0) [0|100] "%"  HVESP01
 SG_ HVESP01_brickSOC_100_5 m24: 50|14@1+ (1,0) [0|100] "%"  HVESP01
 SG_ HVESP01_brickSOC_101_5 m25: 8|14@1+ (1,0) [0|100] "%"  HVESP01
 SG_ HVESP01_brickSOC_102_5 m25: 22|14@1+ (1,0) [0|100] "%"  HVESP01
 SG_ HVESP01_brickSOC_103_5 m25: 36|14@1+ (1,0) [0|100] "%"  HVESP01
 SG_ HVESP01_brickSOC_104_5 m25: 50|14@1+ (1,0) [0|100] "%"  HVESP01
 SG_ HVESP01_brickSOC_105_5 m26: 8|14@1+ (1,0) [0|100] "%"  HVESP01
 SG_ HVESP01_brickSOC_106_5 m26: 22|14@1+ (1,0) [0|100] "%"  HVESP01
 SG_ HVESP01_brickSOC_107_5 m26: 36|14@1+ (1,0) [0|100] "%"  HVESP01
 SG_ HVESP01_brickSOC_108_5 m26: 50|14@1+ (1,0) [0|100] "%"  HVESP01
 SG_ HVESP01_brickSOC_109_5 m27: 8|14@1+ (1,0) [0|100] "%"  HVESP01
 SG_ HVESP01_brickSOC_110_5 m27: 22|14@1+ (1,0) [0|100] "%"  HVESP01
 SG_ HVESP01_brickSOC_111_5 m27: 36|14@1+ (1,0) [0|100] "%"  HVESP01
 SG_ HVESP01_brickSOC_112_5 m27: 50|14@1+ (1,0) [0|100] "%"  HVESP01
 SG_ HVESP01_brickSOC_113_5 m28: 8|14@1+ (1,0) [0|100] "%"  HVESP01
 SG_ HVESP01_brickSOC_114_5 m28: 22|14@1+ (1,0) [0|100] "%"  HVESP01
 SG_ HVESP01_brickSOC_115_5 m28: 36|14@1+ (1,0) [0|100] "%"  HVESP01
 SG_ HVESP01_brickSOC_116_5 m28: 50|14@1+ (1,0) [0|100] "%"  HVESP01
 SG_ HVESP01_brickSOC_117_5 m29: 8|14@1+ (1,0) [0|100] "%"  HVESP01
 SG_ HVESP01_brickSOC_118_5 m29: 22|14@1+ (1,0) [0|100] "%"  HVESP01
 SG_ HVESP01_brickSOC_119_5 m29: 36|14@1+ (1,0) [0|100] "%"  HVESP01
 SG_ HVESP01_brickSOC_120_5 m29: 50|14@1+ (1,0) [0|100] "%"  HVESP01
 SG_ HVESP01_brickSOC_121_5 m30: 8|14@1+ (1,0) [0|100] "%"  HVESP01
 SG_ HVESP01_brickSOC_122_5 m30: 22|14@1+ (1,0) [0|100] "%"  HVESP01
 SG_ HVESP01_brickSOC_123_5 m30: 36|14@1+ (1,0) [0|100] "%"  HVESP01
 SG_ HVESP01_brickSOC_124_5 m30: 50|14@1+ (1,0) [0|100] "%"  HVESP01
 SG_ HVESP01_brickSOC_125_5 m31: 8|14@1+ (1,0) [0|100] "%"  HVESP01
 SG_ HVESP01_brickSOC_126_5 m31: 22|14@1+ (1,0) [0|100] "%"  HVESP01
 SG_ HVESP01_brickSOC_127_5 m31: 36|14@1+ (1,0) [0|100] "%"  HVESP01
 SG_ HVESP01_brickSOC_128_5 m31: 50|14@1+ (1,0) [0|100] "%"  HVESP01
 SG_ HVESP01_brickSOC_129_5 m32: 8|14@1+ (1,0) [0|100] "%"  HVESP01
 SG_ HVESP01_brickSOC_130_5 m32: 22|14@1+ (1,0) [0|100] "%"  HVESP01
 SG_ HVESP01_brickSOC_131_5 m32: 36|14@1+ (1,0) [0|100] "%"  HVESP01
 SG_ HVESP01_brickSOC_132_5 m32: 50|14@1+ (1,0) [0|100] "%"  HVESP01
 SG_ HVESP01_brickSOC_133_5 m33: 8|14@1+ (1,0) [0|100] "%"  HVESP01
 SG_ HVESP01_brickSOC_134_5 m33: 22|14@1+ (1,0) [0|100] "%"  HVESP01
 SG_ HVESP01_brickSOC_135_5 m33: 36|14@1+ (1,0) [0|100] "%"  HVESP01
 SG_ HVESP01_brickSOC_136_5 m33: 50|14@1+ (1,0) [0|100] "%"  HVESP01
 SG_ HVESP01_brickSOC_137_5 m34: 8|14@1+ (1,0) [0|100] "%"  HVESP01
 SG_ HVESP01_brickSOC_138_5 m34: 22|14@1+ (1,0) [0|100] "%"  HVESP01
 SG_ HVESP01_brickSOC_139_5 m34: 36|14@1+ (1,0) [0|100] "%"  HVESP01
 SG_ HVESP01_brickSOC_140_5 m34: 50|14@1+ (1,0) [0|100] "%"  HVESP01
 SG_ HVESP01_brickSOC_141_5 m35: 8|14@1+ (1,0) [0|100] "%"  HVESP01
 SG_ HVESP01_brickSOC_142_5 m35: 22|14@1+ (1,0) [0|100] "%"  HVESP01
 SG_ HVESP01_brickSOC_143_5 m35: 36|14@1+ (1,0) [0|100] "%"  HVESP01
 SG_ HVESP01_brickSOC_144_5 m35: 50|14@1+ (1,0) [0|100] "%"  HVESP01
 SG_ HVESP01_brickSOC_145_5 m36: 8|14@1+ (1,0) [0|100] "%"  HVESP01
 SG_ HVESP01_brickSOC_146_5 m36: 22|14@1+ (1,0) [0|100] "%"  HVESP01
 SG_ HVESP01_brickSOC_147_5 m36: 36|14@1+ (1,0) [0|100] "%"  HVESP01
 SG_ HVESP01_brickSOC_148_5 m36: 50|14@1+ (1,0) [0|100] "%"  HVESP01
 SG_ HVESP01_brickSOC_149_5 m37: 8|14@1+ (1,0) [0|100] "%"  HVESP01
 SG_ HVESP01_brickSOC_150_5 m37: 22|14@1+ (1,0) [0|100] "%"  HVESP01
 SG_ HVESP01_brickSOC_151_5 m37: 36|14@1+ (1,0) [0|100] "%"  HVESP01
 SG_ HVESP01_brickSOC_152_5 m37: 50|14@1+ (1,0) [0|100] "%"  HVESP01
 SG_ HVESP01_brickSOC_153_5 m38: 8|14@1+ (1,0) [0|100] "%"  HVESP01
 SG_ HVESP01_brickSOC_154_5 m38: 22|14@1+ (1,0) [0|100] "%"  HVESP01
 SG_ HVESP01_brickSOC_155_5 m38: 36|14@1+ (1,0) [0|100] "%"  HVESP01
 SG_ HVESP01_brickSOC_156_5 m38: 50|14@1+ (1,0) [0|100] "%"  HVESP01
 SG_ HVESP01_brickSOC_157_5 m39: 8|14@1+ (1,0) [0|100] "%"  HVESP01
 SG_ HVESP01_brickSOC_158_5 m39: 22|14@1+ (1,0) [0|100] "%"  HVESP01
 SG_ HVESP01_brickSOC_159_5 m39: 36|14@1+ (1,0) [0|100] "%"  HVESP01
 SG_ HVESP01_brickSOC_160_5 m39: 50|14@1+ (1,0) [0|100] "%"  HVESP01
 SG_ HVESP01_brickSOC_161_5 m40: 8|14@1+ (1,0) [0|100] "%"  HVESP01
 SG_ HVESP01_brickSOC_162_5 m40: 22|14@1+ (1,0) [0|100] "%"  HVESP01
 SG_ HVESP01_brickSOC_163_5 m40: 36|14@1+ (1,0) [0|100] "%"  HVESP01
 SG_ HVESP01_brickSOC_164_5 m40: 50|14@1+ (1,0) [0|100] "%"  HVESP01
 SG_ HVESP01_brickSOC_165_5 m41: 8|14@1+ (1,0) [0|100] "%"  HVESP01
 SG_ HVESP01_brickSOC_166_5 m41: 22|14@1+ (1,0) [0|100] "%"  HVESP01
 SG_ HVESP01_brickSOC_167_5 m41: 36|14@1+ (1,0) [0|100] "%"  HVESP01
 SG_ HVESP01_brickSOC_168_5 m41: 50|14@1+ (1,0) [0|100] "%"  HVESP01
 SG_ HVESP01_brickSOC_169_5 m42: 8|14@1+ (1,0) [0|100] "%"  HVESP01
 SG_ HVESP01_brickSOC_170_5 m42: 22|14@1+ (1,0) [0|100] "%"  HVESP01
 SG_ HVESP01_brickSOC_171_5 m42: 36|14@1+ (1,0) [0|100] "%"  HVESP01
 SG_ HVESP01_brickSOC_172_5 m42: 50|14@1+ (1,0) [0|100] "%"  HVESP01
 SG_ HVESP01_brickSOC_173_5 m43: 8|14@1+ (1,0) [0|100] "%"  HVESP01
 SG_ HVESP01_brickSOC_174_5 m43: 22|14@1+ (1,0) [0|100] "%"  HVESP01
 SG_ HVESP01_brickSOC_175_5 m43: 36|14@1+ (1,0) [0|100] "%"  HVESP01
 SG_ HVESP01_brickSOC_176_5 m43: 50|14@1+ (1,0) [0|100] "%"  HVESP01
 SG_ HVESP01_brickSOC_177_5 m44: 8|14@1+ (1,0) [0|100] "%"  HVESP01
 SG_ HVESP01_brickSOC_178_5 m44: 22|14@1+ (1,0) [0|100] "%"  HVESP01
 SG_ HVESP01_brickSOC_179_5 m44: 36|14@1+ (1,0) [0|100] "%"  HVESP01
 SG_ HVESP01_brickSOC_180_5 m44: 50|14@1+ (1,0) [0|100] "%"  HVESP01
 SG_ HVESP01_brickSOC_181_5 m45: 8|14@1+ (1,0) [0|100] "%"  HVESP01
 SG_ HVESP01_brickSOC_182_5 m45: 22|14@1+ (1,0) [0|100] "%"  HVESP01
 SG_ HVESP01_brickSOC_183_5 m45: 36|14@1+ (1,0) [0|100] "%"  HVESP01
 SG_ HVESP01_brickSOC_184_5 m45: 50|14@1+ (1,0) [0|100] "%"  HVESP01
 SG_ HVESP01_brickSOC_185_5 m46: 8|14@1+ (1,0) [0|100] "%"  HVESP01
 SG_ HVESP01_brickSOC_186_5 m46: 22|14@1+ (1,0) [0|100] "%"  HVESP01
 SG_ HVESP01_brickSOC_187_5 m46: 36|14@1+ (1,0) [0|100] "%"  HVESP01
 SG_ HVESP01_brickSOC_188_5 m46: 50|14@1+ (1,0) [0|100] "%"  HVESP01
 SG_ HVESP01_brickSOC_189_5 m47: 8|14@1+ (1,0) [0|100] "%"  HVESP01
 SG_ HVESP01_brickSOC_190_5 m47: 22|14@1+ (1,0) [0|100] "%"  HVESP01
 SG_ HVESP01_brickSOC_191_5 m47: 36|14@1+ (1,0) [0|100] "%"  HVESP01
 SG_ HVESP01_brickSOC_192_5 m47: 50|14@1+ (1,0) [0|100] "%"  HVESP01
 SG_ multiplexorsoc_5 M: 0|8@1+ (1,0) [0|255] ""  HVESP01

BO_ 2499741034 HVESP01_brickSOC_6: 8 HVESP01
 SG_ HVESP01_brickSOC_01_6 m0: 8|14@1+ (1,0) [0|100] "%"  HVESP01
 SG_ HVESP01_brickSOC_02_6 m0: 22|14@1+ (1,0) [0|100] "%"  HVESP01
 SG_ HVESP01_brickSOC_03_6 m0: 36|14@1+ (1,0) [0|100] "%"  HVESP01
 SG_ HVESP01_brickSOC_04_6 m0: 50|14@1+ (1,0) [0|100] "%"  HVESP01
 SG_ HVESP01_brickSOC_05_6 m1: 8|14@1+ (1,0) [0|100] "%"  HVESP01
 SG_ HVESP01_brickSOC_06_6 m1: 22|14@1+ (1,0) [0|100] "%"  HVESP01
 SG_ HVESP01_brickSOC_07_6 m1: 36|14@1+ (1,0) [0|100] "%"  HVESP01
 SG_ HVESP01_brickSOC_08_6 m1: 50|14@1+ (1,0) [0|100] "%"  HVESP01
 SG_ HVESP01_brickSOC_09_6 m2: 8|14@1+ (1,0) [0|100] "%"  HVESP01
 SG_ HVESP01_brickSOC_10_6 m2: 22|14@1+ (1,0) [0|100] "%"  HVESP01
 SG_ HVESP01_brickSOC_11_6 m2: 36|14@1+ (1,0) [0|100] "%"  HVESP01
 SG_ HVESP01_brickSOC_12_6 m2: 50|14@1+ (1,0) [0|100] "%"  HVESP01
 SG_ HVESP01_brickSOC_13_6 m3: 8|14@1+ (1,0) [0|100] "%"  HVESP01
 SG_ HVESP01_brickSOC_14_6 m3: 22|14@1+ (1,0) [0|100] "%"  HVESP01
 SG_ HVESP01_brickSOC_15_6 m3: 36|14@1+ (1,0) [0|100] "%"  HVESP01
 SG_ HVESP01_brickSOC_16_6 m3: 50|14@1+ (1,0) [0|100] "%"  HVESP01
 SG_ HVESP01_brickSOC_17_6 m4: 8|14@1+ (1,0) [0|100] "%"  HVESP01
 SG_ HVESP01_brickSOC_18_6 m4: 22|14@1+ (1,0) [0|100] "%"  HVESP01
 SG_ HVESP01_brickSOC_19_6 m4: 36|14@1+ (1,0) [0|100] "%"  HVESP01
 SG_ HVESP01_brickSOC_20_6 m4: 50|14@1+ (1,0) [0|100] "%"  HVESP01
 SG_ HVESP01_brickSOC_21_6 m5: 8|14@1+ (1,0) [0|100] "%"  HVESP01
 SG_ HVESP01_brickSOC_22_6 m5: 22|14@1+ (1,0) [0|100] "%"  HVESP01
 SG_ HVESP01_brickSOC_23_6 m5: 36|14@1+ (1,0) [0|100] "%"  HVESP01
 SG_ HVESP01_brickSOC_24_6 m5: 50|14@1+ (1,0) [0|100] "%"  HVESP01
 SG_ HVESP01_brickSOC_25_6 m6: 8|14@1+ (1,0) [0|100] "%"  HVESP01
 SG_ HVESP01_brickSOC_26_6 m6: 22|14@1+ (1,0) [0|100] "%"  HVESP01
 SG_ HVESP01_brickSOC_27_6 m6: 36|14@1+ (1,0) [0|100] "%"  HVESP01
 SG_ HVESP01_brickSOC_28_6 m6: 50|14@1+ (1,0) [0|100] "%"  HVESP01
 SG_ HVESP01_brickSOC_29_6 m7: 8|14@1+ (1,0) [0|100] "%"  HVESP01
 SG_ HVESP01_brickSOC_30_6 m7: 22|14@1+ (1,0) [0|100] "%"  HVESP01
 SG_ HVESP01_brickSOC_31_6 m7: 36|14@1+ (1,0) [0|100] "%"  HVESP01
 SG_ HVESP01_brickSOC_32_6 m7: 50|14@1+ (1,0) [0|100] "%"  HVESP01
 SG_ HVESP01_brickSOC_33_6 m8: 8|14@1+ (1,0) [0|100] "%"  HVESP01
 SG_ HVESP01_brickSOC_34_6 m8: 22|14@1+ (1,0) [0|100] "%"  HVESP01
 SG_ HVESP01_brickSOC_35_6 m8: 36|14@1+ (1,0) [0|100] "%"  HVESP01
 SG_ HVESP01_brickSOC_36_6 m8: 50|14@1+ (1,0) [0|100] "%"  HVESP01
 SG_ HVESP01_brickSOC_37_6 m9: 8|14@1+ (1,0) [0|100] "%"  HVESP01
 SG_ HVESP01_brickSOC_38_6 m9: 22|14@1+ (1,0) [0|100] "%"  HVESP01
 SG_ HVESP01_brickSOC_39_6 m9: 36|14@1+ (1,0) [0|100] "%"  HVESP01
 SG_ HVESP01_brickSOC_40_6 m9: 50|14@1+ (1,0) [0|100] "%"  HVESP01
 SG_ HVESP01_brickSOC_41_6 m10: 8|14@1+ (1,0) [0|100] "%"  HVESP01
 SG_ HVESP01_brickSOC_42_6 m10: 22|14@1+ (1,0) [0|100] "%"  HVESP01
 SG_ HVESP01_brickSOC_43_6 m10: 36|14@1+ (1,0) [0|100] "%"  HVESP01
 SG_ HVESP01_brickSOC_44_6 m10: 50|14@1+ (1,0) [0|100] "%"  HVESP01
 SG_ HVESP01_brickSOC_45_6 m11: 8|14@1+ (1,0) [0|100] "%"  HVESP01
 SG_ HVESP01_brickSOC_46_6 m11: 22|14@1+ (1,0) [0|100] "%"  HVESP01
 SG_ HVESP01_brickSOC_47_6 m11: 36|14@1+ (1,0) [0|100] "%"  HVESP01
 SG_ HVESP01_brickSOC_48_6 m11: 50|14@1+ (1,0) [0|100] "%"  HVESP01
 SG_ HVESP01_brickSOC_49_6 m12: 8|14@1+ (1,0) [0|100] "%"  HVESP01
 SG_ HVESP01_brickSOC_50_6 m12: 22|14@1+ (1,0) [0|100] "%"  HVESP01
 SG_ HVESP01_brickSOC_51_6 m12: 36|14@1+ (1,0) [0|100] "%"  HVESP01
 SG_ HVESP01_brickSOC_52_6 m12: 50|14@1+ (1,0) [0|100] "%"  HVESP01
 SG_ HVESP01_brickSOC_53_6 m13: 8|14@1+ (1,0) [0|100] "%"  HVESP01
 SG_ HVESP01_brickSOC_54_6 m13: 22|14@1+ (1,0) [0|100] "%"  HVESP01
 SG_ HVESP01_brickSOC_55_6 m13: 36|14@1+ (1,0) [0|100] "%"  HVESP01
 SG_ HVESP01_brickSOC_56_6 m13: 50|14@1+ (1,0) [0|100] "%"  HVESP01
 SG_ HVESP01_brickSOC_57_6 m14: 8|14@1+ (1,0) [0|100] "%"  HVESP01
 SG_ HVESP01_brickSOC_58_6 m14: 22|14@1+ (1,0) [0|100] "%"  HVESP01
 SG_ HVESP01_brickSOC_59_6 m14: 36|14@1+ (1,0) [0|100] "%"  HVESP01
 SG_ HVESP01_brickSOC_60_6 m14: 50|14@1+ (1,0) [0|100] "%"  HVESP01
 SG_ HVESP01_brickSOC_61_6 m15: 8|14@1+ (1,0) [0|100] "%"  HVESP01
 SG_ HVESP01_brickSOC_62_6 m15: 22|14@1+ (1,0) [0|100] "%"  HVESP01
 SG_ HVESP01_brickSOC_63_6 m15: 36|14@1+ (1,0) [0|100] "%"  HVESP01
 SG_ HVESP01_brickSOC_64_6 m15: 50|14@1+ (1,0) [0|100] "%"  HVESP01
 SG_ HVESP01_brickSOC_65_6 m16: 8|14@1+ (1,0) [0|100] "%"  HVESP01
 SG_ HVESP01_brickSOC_66_6 m16: 22|14@1+ (1,0) [0|100] "%"  HVESP01
 SG_ HVESP01_brickSOC_67_6 m16: 36|14@1+ (1,0) [0|100] "%"  HVESP01
 SG_ HVESP01_brickSOC_68_6 m16: 50|14@1+ (1,0) [0|100] "%"  HVESP01
 SG_ HVESP01_brickSOC_69_6 m17: 8|14@1+ (1,0) [0|100] "%"  HVESP01
 SG_ HVESP01_brickSOC_70_6 m17: 22|14@1+ (1,0) [0|100] "%"  HVESP01
 SG_ HVESP01_brickSOC_71_6 m17: 36|14@1+ (1,0) [0|100] "%"  HVESP01
 SG_ HVESP01_brickSOC_72_6 m17: 50|14@1+ (1,0) [0|100] "%"  HVESP01
 SG_ HVESP01_brickSOC_73_6 m18: 8|14@1+ (1,0) [0|100] "%"  HVESP01
 SG_ HVESP01_brickSOC_74_6 m18: 22|14@1+ (1,0) [0|100] "%"  HVESP01
 SG_ HVESP01_brickSOC_75_6 m18: 36|14@1+ (1,0) [0|100] "%"  HVESP01
 SG_ HVESP01_brickSOC_76_6 m18: 50|14@1+ (1,0) [0|100] "%"  HVESP01
 SG_ HVESP01_brickSOC_77_6 m19: 8|14@1+ (1,0) [0|100] "%"  HVESP01
 SG_ HVESP01_brickSOC_78_6 m19: 22|14@1+ (1,0) [0|100] "%"  HVESP01
 SG_ HVESP01_brickSOC_79_6 m19: 36|14@1+ (1,0) [0|100] "%"  HVESP01
 SG_ HVESP01_brickSOC_80_6 m19: 50|14@1+ (1,0) [0|100] "%"  HVESP01
 SG_ HVESP01_brickSOC_81_6 m20: 8|14@1+ (1,0) [0|100] "%"  HVESP01
 SG_ HVESP01_brickSOC_82_6 m20: 22|14@1+ (1,0) [0|100] "%"  HVESP01
 SG_ HVESP01_brickSOC_83_6 m20: 36|14@1+ (1,0) [0|100] "%"  HVESP01
 SG_ HVESP01_brickSOC_84_6 m20: 50|14@1+ (1,0) [0|100] "%"  HVESP01
 SG_ HVESP01_brickSOC_85_6 m21: 8|14@1+ (1,0) [0|100] "%"  HVESP01
 SG_ HVESP01_brickSOC_86_6 m21: 22|14@1+ (1,0) [0|100] "%"  HVESP01
 SG_ HVESP01_brickSOC_87_6 m21: 36|14@1+ (1,0) [0|100] "%"  HVESP01
 SG_ HVESP01_brickSOC_88_6 m21: 50|14@1+ (1,0) [0|100] "%"  HVESP01
 SG_ HVESP01_brickSOC_89_6 m22: 8|14@1+ (1,0) [0|100] "%"  HVESP01
 SG_ HVESP01_brickSOC_90_6 m22: 22|14@1+ (1,0) [0|100] "%"  HVESP01
 SG_ HVESP01_brickSOC_91_6 m22: 36|14@1+ (1,0) [0|100] "%"  HVESP01
 SG_ HVESP01_brickSOC_92_6 m22: 50|14@1+ (1,0) [0|100] "%"  HVESP01
 SG_ HVESP01_brickSOC_93_6 m23: 8|14@1+ (1,0) [0|100] "%"  HVESP01
 SG_ HVESP01_brickSOC_94_6 m23: 22|14@1+ (1,0) [0|100] "%"  HVESP01
 SG_ HVESP01_brickSOC_95_6 m23: 36|14@1+ (1,0) [0|100] "%"  HVESP01
 SG_ HVESP01_brickSOC_96_6 m23: 50|14@1+ (1,0) [0|100] "%"  HVESP01
 SG_ HVESP01_brickSOC_97_6 m24: 8|14@1+ (1,0) [0|100] "%"  HVESP01
 SG_ HVESP01_brickSOC_98_6 m24: 22|14@1+ (1,0) [0|100] "%"  HVESP01
 SG_ HVESP01_brickSOC_99_6 m24: 36|14@1+ (1,0) [0|100] "%"  HVESP01
 SG_ HVESP01_brickSOC_100_6 m24: 50|14@1+ (1,0) [0|100] "%"  HVESP01
 SG_ HVESP01_brickSOC_101_6 m25: 8|14@1+ (1,0) [0|100] "%"  HVESP01
 SG_ HVESP01_brickSOC_102_6 m25: 22|14@1+ (1,0) [0|100] "%"  HVESP01
 SG_ HVESP01_brickSOC_103_6 m25: 36|14@1+ (1,0) [0|100] "%"  HVESP01
 SG_ HVESP01_brickSOC_104_6 m25: 50|14@1+ (1,0) [0|100] "%"  HVESP01
 SG_ HVESP01_brickSOC_105_6 m26: 8|14@1+ (1,0) [0|100] "%"  HVESP01
 SG_ HVESP01_brickSOC_106_6 m26: 22|14@1+ (1,0) [0|100] "%"  HVESP01
 SG_ HVESP01_brickSOC_107_6 m26: 36|14@1+ (1,0) [0|100] "%"  HVESP01
 SG_ HVESP01_brickSOC_108_6 m26: 50|14@1+ (1,0) [0|100] "%"  HVESP01
 SG_ HVESP01_brickSOC_109_6 m27: 8|14@1+ (1,0) [0|100] "%"  HVESP01
 SG_ HVESP01_brickSOC_110_6 m27: 22|14@1+ (1,0) [0|100] "%"  HVESP01
 SG_ HVESP01_brickSOC_111_6 m27: 36|14@1+ (1,0) [0|100] "%"  HVESP01
 SG_ HVESP01_brickSOC_112_6 m27: 50|14@1+ (1,0) [0|100] "%"  HVESP01
 SG_ HVESP01_brickSOC_113_6 m28: 8|14@1+ (1,0) [0|100] "%"  HVESP01
 SG_ HVESP01_brickSOC_114_6 m28: 22|14@1+ (1,0) [0|100] "%"  HVESP01
 SG_ HVESP01_brickSOC_115_6 m28: 36|14@1+ (1,0) [0|100] "%"  HVESP01
 SG_ HVESP01_brickSOC_116_6 m28: 50|14@1+ (1,0) [0|100] "%"  HVESP01
 SG_ HVESP01_brickSOC_117_6 m29: 8|14@1+ (1,0) [0|100] "%"  HVESP01
 SG_ HVESP01_brickSOC_118_6 m29: 22|14@1+ (1,0) [0|100] "%"  HVESP01
 SG_ HVESP01_brickSOC_119_6 m29: 36|14@1+ (1,0) [0|100] "%"  HVESP01
 SG_ HVESP01_brickSOC_120_6 m29: 50|14@1+ (1,0) [0|100] "%"  HVESP01
 SG_ HVESP01_brickSOC_121_6 m30: 8|14@1+ (1,0) [0|100] "%"  HVESP01
 SG_ HVESP01_brickSOC_122_6 m30: 22|14@1+ (1,0) [0|100] "%"  HVESP01
 SG_ HVESP01_brickSOC_123_6 m30: 36|14@1+ (1,0) [0|100] "%"  HVESP01
 SG_ HVESP01_brickSOC_124_6 m30: 50|14@1+ (1,0) [0|100] "%"  HVESP01
 SG_ HVESP01_brickSOC_125_6 m31: 8|14@1+ (1,0) [0|100] "%"  HVESP01
 SG_ HVESP01_brickSOC_126_6 m31: 22|14@1+ (1,0) [0|100] "%"  HVESP01
 SG_ HVESP01_brickSOC_127_6 m31: 36|14@1+ (1,0) [0|100] "%"  HVESP01
 SG_ HVESP01_brickSOC_128_6 m31: 50|14@1+ (1,0) [0|100] "%"  HVESP01
 SG_ HVESP01_brickSOC_129_6 m32: 8|14@1+ (1,0) [0|100] "%"  HVESP01
 SG_ HVESP01_brickSOC_130_6 m32: 22|14@1+ (1,0) [0|100] "%"  HVESP01
 SG_ HVESP01_brickSOC_131_6 m32: 36|14@1+ (1,0) [0|100] "%"  HVESP01
 SG_ HVESP01_brickSOC_132_6 m32: 50|14@1+ (1,0) [0|100] "%"  HVESP01
 SG_ HVESP01_brickSOC_133_6 m33: 8|14@1+ (1,0) [0|100] "%"  HVESP01
 SG_ HVESP01_brickSOC_134_6 m33: 22|14@1+ (1,0) [0|100] "%"  HVESP01
 SG_ HVESP01_brickSOC_135_6 m33: 36|14@1+ (1,0) [0|100] "%"  HVESP01
 SG_ HVESP01_brickSOC_136_6 m33: 50|14@1+ (1,0) [0|100] "%"  HVESP01
 SG_ HVESP01_brickSOC_137_6 m34: 8|14@1+ (1,0) [0|100] "%"  HVESP01
 SG_ HVESP01_brickSOC_138_6 m34: 22|14@1+ (1,0) [0|100] "%"  HVESP01
 SG_ HVESP01_brickSOC_139_6 m34: 36|14@1+ (1,0) [0|100] "%"  HVESP01
 SG_ HVESP01_brickSOC_140_6 m34: 50|14@1+ (1,0) [0|100] "%"  HVESP01
 SG_ HVESP01_brickSOC_141_6 m35: 8|14@1+ (1,0) [0|100] "%"  HVESP01
 SG_ HVESP01_brickSOC_142_6 m35: 22|14@1+ (1,0) [0|100] "%"  HVESP01
 SG_ HVESP01_brickSOC_143_6 m35: 36|14@1+ (1,0) [0|100] "%"  HVESP01
 SG_ HVESP01_brickSOC_144_6 m35: 50|14@1+ (1,0) [0|100] "%"  HVESP01
 SG_ HVESP01_brickSOC_145_6 m36: 8|14@1+ (1,0) [0|100] "%"  HVESP01
 SG_ HVESP01_brickSOC_146_6 m36: 22|14@1+ (1,0) [0|100] "%"  HVESP01
 SG_ HVESP01_brickSOC_147_6 m36: 36|14@1+ (1,0) [0|100] "%"  HVESP01
 SG_ HVESP01_brickSOC_148_6 m36: 50|14@1+ (1,0) [0|100] "%"  HVESP01
 SG_ HVESP01_brickSOC_149_6 m37: 8|14@1+ (1,0) [0|100] "%"  HVESP01
 SG_ HVESP01_brickSOC_150_6 m37: 22|14@1+ (1,0) [0|100] "%"  HVESP01
 SG_ HVESP01_brickSOC_151_6 m37: 36|14@1+ (1,0) [0|100] "%"  HVESP01
 SG_ HVESP01_brickSOC_152_6 m37: 50|14@1+ (1,0) [0|100] "%"  HVESP01
 SG_ HVESP01_brickSOC_153_6 m38: 8|14@1+ (1,0) [0|100] "%"  HVESP01
 SG_ HVESP01_brickSOC_154_6 m38: 22|14@1+ (1,0) [0|100] "%"  HVESP01
 SG_ HVESP01_brickSOC_155_6 m38: 36|14@1+ (1,0) [0|100] "%"  HVESP01
 SG_ HVESP01_brickSOC_156_6 m38: 50|14@1+ (1,0) [0|100] "%"  HVESP01
 SG_ HVESP01_brickSOC_157_6 m39: 8|14@1+ (1,0) [0|100] "%"  HVESP01
 SG_ HVESP01_brickSOC_158_6 m39: 22|14@1+ (1,0) [0|100] "%"  HVESP01
 SG_ HVESP01_brickSOC_159_6 m39: 36|14@1+ (1,0) [0|100] "%"  HVESP01
 SG_ HVESP01_brickSOC_160_6 m39: 50|14@1+ (1,0) [0|100] "%"  HVESP01
 SG_ HVESP01_brickSOC_161_6 m40: 8|14@1+ (1,0) [0|100] "%"  HVESP01
 SG_ HVESP01_brickSOC_162_6 m40: 22|14@1+ (1,0) [0|100] "%"  HVESP01
 SG_ HVESP01_brickSOC_163_6 m40: 36|14@1+ (1,0) [0|100] "%"  HVESP01
 SG_ HVESP01_brickSOC_164_6 m40: 50|14@1+ (1,0) [0|100] "%"  HVESP01
 SG_ HVESP01_brickSOC_165_6 m41: 8|14@1+ (1,0) [0|100] "%"  HVESP01
 SG_ HVESP01_brickSOC_166_6 m41: 22|14@1+ (1,0) [0|100] "%"  HVESP01
 SG_ HVESP01_brickSOC_167_6 m41: 36|14@1+ (1,0) [0|100] "%"  HVESP01
 SG_ HVESP01_brickSOC_168_6 m41: 50|14@1+ (1,0) [0|100] "%"  HVESP01
 SG_ HVESP01_brickSOC_169_6 m42: 8|14@1+ (1,0) [0|100] "%"  HVESP01
 SG_ HVESP01_brickSOC_170_6 m42: 22|14@1+ (1,0) [0|100] "%"  HVESP01
 SG_ HVESP01_brickSOC_171_6 m42: 36|14@1+ (1,0) [0|100] "%"  HVESP01
 SG_ HVESP01_brickSOC_172_6 m42: 50|14@1+ (1,0) [0|100] "%"  HVESP01
 SG_ HVESP01_brickSOC_173_6 m43: 8|14@1+ (1,0) [0|100] "%"  HVESP01
 SG_ HVESP01_brickSOC_174_6 m43: 22|14@1+ (1,0) [0|100] "%"  HVESP01
 SG_ HVESP01_brickSOC_175_6 m43: 36|14@1+ (1,0) [0|100] "%"  HVESP01
 SG_ HVESP01_brickSOC_176_6 m43: 50|14@1+ (1,0) [0|100] "%"  HVESP01
 SG_ HVESP01_brickSOC_177_6 m44: 8|14@1+ (1,0) [0|100] "%"  HVESP01
 SG_ HVESP01_brickSOC_178_6 m44: 22|14@1+ (1,0) [0|100] "%"  HVESP01
 SG_ HVESP01_brickSOC_179_6 m44: 36|14@1+ (1,0) [0|100] "%"  HVESP01
 SG_ HVESP01_brickSOC_180_6 m44: 50|14@1+ (1,0) [0|100] "%"  HVESP01
 SG_ HVESP01_brickSOC_181_6 m45: 8|14@1+ (1,0) [0|100] "%"  HVESP01
 SG_ HVESP01_brickSOC_182_6 m45: 22|14@1+ (1,0) [0|100] "%"  HVESP01
 SG_ HVESP01_brickSOC_183_6 m45: 36|14@1+ (1,0) [0|100] "%"  HVESP01
 SG_ HVESP01_brickSOC_184_6 m45: 50|14@1+ (1,0) [0|100] "%"  HVESP01
 SG_ HVESP01_brickSOC_185_6 m46: 8|14@1+ (1,0) [0|100] "%"  HVESP01
 SG_ HVESP01_brickSOC_186_6 m46: 22|14@1+ (1,0) [0|100] "%"  HVESP01
 SG_ HVESP01_brickSOC_187_6 m46: 36|14@1+ (1,0) [0|100] "%"  HVESP01
 SG_ HVESP01_brickSOC_188_6 m46: 50|14@1+ (1,0) [0|100] "%"  HVESP01
 SG_ HVESP01_brickSOC_189_6 m47: 8|14@1+ (1,0) [0|100] "%"  HVESP01
 SG_ HVESP01_brickSOC_190_6 m47: 22|14@1+ (1,0) [0|100] "%"  HVESP01
 SG_ HVESP01_brickSOC_191_6 m47: 36|14@1+ (1,0) [0|100] "%"  HVESP01
 SG_ HVESP01_brickSOC_192_6 m47: 50|14@1+ (1,0) [0|100] "%"  HVESP01
 SG_ multiplexorsoc_6 M: 0|8@1+ (1,0) [0|255] ""  HVESP01

CM_ "NF_V_1.5";
CM_ BO_ 2499740773 "Message on BATT (internal multi pack CAN bus) for backup speaker handshake";
CM_ SG_ 2499740773 HVESP01_speakerClaimFlag_1 "Active speaker will set this bit to 1.
Rest of the packs will set this value to 0.
Backup speaker will set this bit to 1 in case of _speakerClaimFlag_1
";
CM_ SG_ 2499740773 HVESP01_expectedSpeakerID_1 "Default all the packs will set this value to 1.
Pack 2 shall set this signal to 2 in case of trying to become speaker.  ";
CM_ BO_ 2499740774 "Message on BATT (internal multi pack CAN bus) for backup speaker handshake";
CM_ SG_ 2499740774 HVESP01_speakerClaimFlag_2 "Active speaker will set this bit to 1.
Rest of the packs will set this value to 0.
Backup speaker will set this bit to 1 in case of _speakerClaimFlag_1
";
CM_ SG_ 2499740774 HVESP01_expectedSpeakerID_2 "Default all the packs will set this value to 1.
Pack 2 shall set this signal to 2 in case of trying to become speaker.  ";
CM_ BO_ 2499740775 "Message on BATT (internal multi pack CAN bus) for backup speaker handshake";
CM_ SG_ 2499740775 HVESP01_speakerClaimFlag_3 "Active speaker will set this bit to 1.
Rest of the packs will set this value to 0.
Backup speaker will set this bit to 1 in case of _speakerClaimFlag_1
";
CM_ SG_ 2499740775 HVESP01_expectedSpeakerID_3 "Default all the packs will set this value to 1.
Pack 2 shall set this signal to 2 in case of trying to become speaker.  ";
CM_ BO_ 2499740776 "Message on BATT (internal multi pack CAN bus) for backup speaker handshake";
CM_ SG_ 2499740776 HVESP01_speakerClaimFlag_4 "Active speaker will set this bit to 1.
Rest of the packs will set this value to 0.
Backup speaker will set this bit to 1 in case of _speakerClaimFlag_1
";
CM_ SG_ 2499740776 HVESP01_expectedSpeakerID_4 "Default all the packs will set this value to 1.
Pack 2 shall set this signal to 2 in case of trying to become speaker.  ";
CM_ BO_ 2499740777 "Message on BATT (internal multi pack CAN bus) for backup speaker handshake";
CM_ SG_ 2499740777 HVESP01_speakerClaimFlag_5 "Active speaker will set this bit to 1.
Rest of the packs will set this value to 0.
Backup speaker will set this bit to 1 in case of _speakerClaimFlag_1
";
CM_ SG_ 2499740777 HVESP01_expectedSpeakerID_5 "Default all the packs will set this value to 1.
Pack 2 shall set this signal to 2 in case of trying to become speaker.  ";
CM_ BO_ 2499740778 "Message on BATT (internal multi pack CAN bus) for backup speaker handshake";
CM_ SG_ 2499740778 HVESP01_speakerClaimFlag_6 "Active speaker will set this bit to 1.
Rest of the packs will set this value to 0.
Backup speaker will set this bit to 1 in case of _speakerClaimFlag_1
";
CM_ SG_ 2499740778 HVESP01_expectedSpeakerID_6 "Default all the packs will set this value to 1.
Pack 2 shall set this signal to 2 in case of trying to become speaker.  ";
CM_ BO_ 2499740779 "Message on BATT (internal multi pack CAN bus) for backup speaker handshake";
CM_ SG_ 2499740779 HVESP01_speakerClaimFlag_7 "Active speaker will set this bit to 1.
Rest of the packs will set this value to 0.
Backup speaker will set this bit to 1 in case of _speakerClaimFlag_1
";
CM_ SG_ 2499740779 HVESP01_expectedSpeakerID_7 "Default all the packs will set this value to 1.
Pack 2 shall set this signal to 2 in case of trying to become speaker.  ";
CM_ BO_ 2499740780 "Message on BATT (internal multi pack CAN bus) for backup speaker handshake";
CM_ SG_ 2499740780 HVESP01_speakerClaimFlag_8 "Active speaker will set this bit to 1.
Rest of the packs will set this value to 0.
Backup speaker will set this bit to 1 in case of _speakerClaimFlag_1
";
CM_ SG_ 2499740780 HVESP01_expectedSpeakerID_8 "Default all the packs will set this value to 1.
Pack 2 shall set this signal to 2 in case of trying to become speaker.  ";

BA_DEF_ BO_  "GenMsgDiag" ENUM "No","Yes";
BA_DEF_ BU_  "GenNodeInstanceStartBit" INT 0 0;
BA_DEF_ BU_  "GenNodeInstanceBitWidth" INT 0 0;
BA_DEF_ BO_  "GenMsgInstanced" STRING ;
BA_DEF_  "NetworkSpeed" ENUM "250kBit/s","500kBit/s","1000kBit/s";
BA_DEF_ SG_  "SigType" ENUM "Default","Range","RangeSigned","ASCII","Discrete","Control","ReferencePGN","DTC","StringDelimiter","StringLength","StringLengthControl","MessageCounter","MessageChecksum";
BA_DEF_ SG_  "GenSigEVName" STRING ;
BA_DEF_ SG_  "GenSigILSupport" ENUM "No","Yes";
BA_DEF_ SG_  "GenSigSendType" ENUM "Cyclic","OnWrite","OnWriteWithRepetition","OnChange","OnChangeWithRepetition","IfActive","IfActiveWithRepetition","NoSigSendType";
BA_DEF_ BO_  "GenMsgILSupport" ENUM "No","Yes";
BA_DEF_ BU_  "NmStationAddress" INT 0 255;
BA_DEF_ BO_  "GenMsgSendType" ENUM "cyclic","NotUsed","IfActive","NotUsed","NotUsed","NotUsed","NotUsed","NotUsed","noMsgSendType";
BA_DEF_ BO_  "GenMsgRequestable" INT 0 1;
BA_DEF_ BO_  "GenMsgCycleTime" INT 0 3600000;
BA_DEF_  "DBName" STRING ;
BA_DEF_  "BusType" STRING ;
BA_DEF_  "ProtocolType" STRING ;
BA_DEF_ BO_  "VFrameFormat" ENUM "StandardCAN","ExtendedCAN","reserved","J1939PG";
BA_DEF_ SG_  "SystemSignalLongSymbol" STRING ;
BA_DEF_DEF_  "GenMsgDiag" "No";
BA_DEF_DEF_  "GenNodeInstanceStartBit" 0;
BA_DEF_DEF_  "GenNodeInstanceBitWidth" 0;
BA_DEF_DEF_  "GenMsgInstanced" "No";
BA_DEF_DEF_  "NetworkSpeed" "250kBit/s";
BA_DEF_DEF_  "SigType" "Default";
BA_DEF_DEF_  "GenSigEVName" "Env@Nodename_@Signame";
BA_DEF_DEF_  "GenSigILSupport" "Yes";
BA_DEF_DEF_  "GenSigSendType" "NoSigSendType";
BA_DEF_DEF_  "GenMsgILSupport" "Yes";
BA_DEF_DEF_  "NmStationAddress" 254;
BA_DEF_DEF_  "GenMsgSendType" "noMsgSendType";
BA_DEF_DEF_  "GenMsgRequestable" 1;
BA_DEF_DEF_  "GenMsgCycleTime" 0;
BA_DEF_DEF_  "DBName" "";
BA_DEF_DEF_  "BusType" "CAN";
BA_DEF_DEF_  "ProtocolType" "J1939";
BA_DEF_DEF_  "VFrameFormat" "J1939PG";
BA_DEF_DEF_  "SystemSignalLongSymbol" "";
BA_ "DBName" "NF_BMS_Application";
BA_ "ProtocolType" "CAN";
BA_ "GenNodeInstanceStartBit" BU_ HVESS 4;
BA_ "GenNodeInstanceBitWidth" BU_ HVESP01 8;
BA_ "GenNodeInstanceBitWidth" BU_ HVESS 8;
BA_ "GenMsgDiag" BO_ 2499741029 1;
BA_ "GenMsgDiag" BO_ 2499741030 1;
BA_ "GenMsgDiag" BO_ 2499741031 1;
BA_ "GenMsgDiag" BO_ 2499741032 1;
BA_ "GenMsgDiag" BO_ 2499741033 1;
BA_ "GenMsgDiag" BO_ 2499741034 1;
BA_ "GenMsgInstanced" BO_ 2485806436 "False";
BA_ "GenMsgInstanced" BO_ 2485806692 "False";
BA_ "GenMsgInstanced" BO_ 2485806948 "False";
BA_ "GenMsgInstanced" BO_ 2485807204 "False";
BA_ "GenMsgInstanced" BO_ 2485807460 "False";
BA_ "GenMsgInstanced" BO_ 2485807716 "False";
BA_ "GenMsgInstanced" BO_ 2485807972 "False";
BA_ "GenMsgInstanced" BO_ 2485808228 "False";
BA_ "GenMsgInstanced" BO_ 2485808484 "False";
BA_ "GenMsgInstanced" BO_ 2485808740 "False";
BA_ "GenMsgInstanced" BO_ 2498859365 "False";
BA_ "GenMsgInstanced" BO_ 2498859366 "False";
BA_ "GenMsgInstanced" BO_ 2498859367 "False";
BA_ "GenMsgInstanced" BO_ 2498859368 "False";
BA_ "GenMsgInstanced" BO_ 2498859369 "False";
BA_ "GenMsgInstanced" BO_ 2498859370 "False";
BA_ "GenMsgInstanced" BO_ 2498859371 "False";
BA_ "GenMsgInstanced" BO_ 2498859372 "False";
BA_ "GenMsgInstanced" BO_ 2498859621 "False";
BA_ "GenMsgInstanced" BO_ 2498859622 "False";
BA_ "GenMsgInstanced" BO_ 2498859623 "False";
BA_ "GenMsgInstanced" BO_ 2498859624 "False";
BA_ "GenMsgInstanced" BO_ 2498859625 "False";
BA_ "GenMsgInstanced" BO_ 2498859626 "False";
BA_ "GenMsgInstanced" BO_ 2498859627 "False";
BA_ "GenMsgInstanced" BO_ 2498859628 "False";
BA_ "GenMsgInstanced" BO_ 2498859877 "False";
BA_ "GenMsgInstanced" BO_ 2498859878 "False";
BA_ "GenMsgInstanced" BO_ 2498859879 "False";
BA_ "GenMsgInstanced" BO_ 2498859880 "False";
BA_ "GenMsgInstanced" BO_ 2498859881 "False";
BA_ "GenMsgInstanced" BO_ 2498859882 "False";
BA_ "GenMsgInstanced" BO_ 2498859883 "False";
BA_ "GenMsgInstanced" BO_ 2498859884 "False";
BA_ "GenMsgInstanced" BO_ 2498860389 "False";
BA_ "GenMsgInstanced" BO_ 2498860390 "False";
BA_ "GenMsgInstanced" BO_ 2498860391 "False";
BA_ "GenMsgInstanced" BO_ 2498860392 "False";
BA_ "GenMsgInstanced" BO_ 2498860393 "False";
BA_ "GenMsgInstanced" BO_ 2498860394 "False";
BA_ "GenMsgInstanced" BO_ 2498860395 "False";
BA_ "GenMsgInstanced" BO_ 2498860396 "False";
BA_ "GenMsgInstanced" BO_ 2498860901 "False";
BA_ "GenMsgInstanced" BO_ 2498860902 "False";
BA_ "GenMsgInstanced" BO_ 2498860903 "False";
BA_ "GenMsgInstanced" BO_ 2498860904 "False";
BA_ "GenMsgInstanced" BO_ 2498860905 "False";
BA_ "GenMsgInstanced" BO_ 2498860906 "False";
BA_ "GenMsgInstanced" BO_ 2498860907 "False";
BA_ "GenMsgInstanced" BO_ 2498860908 "False";
BA_ "GenMsgInstanced" BO_ 2498861157 "False";
BA_ "GenMsgInstanced" BO_ 2498861158 "False";
BA_ "GenMsgInstanced" BO_ 2498861159 "False";
BA_ "GenMsgInstanced" BO_ 2498861160 "False";
BA_ "GenMsgInstanced" BO_ 2498861161 "False";
BA_ "GenMsgInstanced" BO_ 2498861162 "False";
BA_ "GenMsgInstanced" BO_ 2498861163 "False";
BA_ "GenMsgInstanced" BO_ 2498861164 "False";
BA_ "GenMsgInstanced" BO_ 2498861925 "False";
BA_ "GenMsgInstanced" BO_ 2498861926 "False";
BA_ "GenMsgInstanced" BO_ 2498861927 "False";
BA_ "GenMsgInstanced" BO_ 2498861928 "False";
BA_ "GenMsgInstanced" BO_ 2498861929 "False";
BA_ "GenMsgInstanced" BO_ 2498861930 "False";
BA_ "GenMsgInstanced" BO_ 2498861931 "False";
BA_ "GenMsgInstanced" BO_ 2498861932 "False";
BA_ "GenMsgInstanced" BO_ 2498862181 "False";
BA_ "GenMsgInstanced" BO_ 2498862182 "False";
BA_ "GenMsgInstanced" BO_ 2498862183 "False";
BA_ "GenMsgInstanced" BO_ 2498862184 "False";
BA_ "GenMsgInstanced" BO_ 2498862185 "False";
BA_ "GenMsgInstanced" BO_ 2498862186 "False";
BA_ "GenMsgInstanced" BO_ 2498862187 "False";
BA_ "GenMsgInstanced" BO_ 2498862188 "False";
BA_ "GenMsgInstanced" BO_ 2498862437 "False";
BA_ "GenMsgInstanced" BO_ 2498862438 "False";
BA_ "GenMsgInstanced" BO_ 2498862439 "False";
BA_ "GenMsgInstanced" BO_ 2498862440 "False";
BA_ "GenMsgInstanced" BO_ 2498862441 "False";
BA_ "GenMsgInstanced" BO_ 2498862442 "False";
BA_ "GenMsgInstanced" BO_ 2498862443 "False";
BA_ "GenMsgInstanced" BO_ 2498862444 "False";
BA_ "GenMsgInstanced" BO_ 2499500389 "False";
BA_ "GenMsgInstanced" BO_ 2499500390 "False";
BA_ "GenMsgInstanced" BO_ 2499500391 "False";
BA_ "GenMsgInstanced" BO_ 2499500392 "False";
BA_ "GenMsgInstanced" BO_ 2499500393 "False";
BA_ "GenMsgInstanced" BO_ 2499500394 "False";
BA_ "GenMsgInstanced" BO_ 2499500395 "False";
BA_ "GenMsgInstanced" BO_ 2499500396 "False";
BA_ "GenMsgInstanced" BO_ 2499739749 "False";
BA_ "GenMsgInstanced" BO_ 2499739750 "False";
BA_ "GenMsgInstanced" BO_ 2499739751 "False";
BA_ "GenMsgInstanced" BO_ 2499739752 "False";
BA_ "GenMsgInstanced" BO_ 2499739753 "False";
BA_ "GenMsgInstanced" BO_ 2499739754 "False";
BA_ "GenMsgInstanced" BO_ 2499739755 "False";
BA_ "GenMsgInstanced" BO_ 2499739756 "False";
BA_ "GenMsgInstanced" BO_ 2499740005 "False";
BA_ "GenMsgInstanced" BO_ 2499740006 "False";
BA_ "GenMsgInstanced" BO_ 2499740007 "False";
BA_ "GenMsgInstanced" BO_ 2499740008 "False";
BA_ "GenMsgInstanced" BO_ 2499740009 "False";
BA_ "GenMsgInstanced" BO_ 2499740010 "False";
BA_ "GenMsgInstanced" BO_ 2499740011 "False";
BA_ "GenMsgInstanced" BO_ 2499740012 "False";
BA_ "GenMsgInstanced" BO_ 2499740261 "False";
BA_ "GenMsgInstanced" BO_ 2499740262 "False";
BA_ "GenMsgInstanced" BO_ 2499740263 "False";
BA_ "GenMsgInstanced" BO_ 2499740264 "False";
BA_ "GenMsgInstanced" BO_ 2499740265 "False";
BA_ "GenMsgInstanced" BO_ 2499740266 "False";
BA_ "GenMsgInstanced" BO_ 2499740267 "False";
BA_ "GenMsgInstanced" BO_ 2499740268 "False";
BA_ "GenMsgInstanced" BO_ 2499740517 "False";
BA_ "GenMsgInstanced" BO_ 2499740518 "False";
BA_ "GenMsgInstanced" BO_ 2499740519 "False";
BA_ "GenMsgInstanced" BO_ 2499740520 "False";
BA_ "GenMsgInstanced" BO_ 2499740521 "False";
BA_ "GenMsgInstanced" BO_ 2499740522 "False";
BA_ "GenMsgInstanced" BO_ 2499740523 "False";
BA_ "GenMsgInstanced" BO_ 2499740524 "False";
BA_ "GenMsgInstanced" BO_ 2499740773 "False";
BA_ "GenMsgInstanced" BO_ 2499740774 "False";
BA_ "GenMsgInstanced" BO_ 2499740775 "False";
BA_ "GenMsgInstanced" BO_ 2499740776 "False";
BA_ "GenMsgInstanced" BO_ 2499740777 "False";
BA_ "GenMsgInstanced" BO_ 2499740778 "False";
BA_ "GenMsgInstanced" BO_ 2499740779 "False";
BA_ "GenMsgInstanced" BO_ 2499740780 "False";
BA_ "GenMsgInstanced" BO_ 2499741029 "False";
BA_ "GenMsgInstanced" BO_ 2499741030 "False";
BA_ "GenMsgInstanced" BO_ 2499741031 "False";
BA_ "GenMsgInstanced" BO_ 2499741032 "False";
BA_ "GenMsgInstanced" BO_ 2499741033 "False";
BA_ "GenMsgInstanced" BO_ 2499741034 "False";
BA_ "GenMsgSendType" BO_ 2485806436 0;
BA_ "GenMsgSendType" BO_ 2498859365 0;
BA_ "GenMsgSendType" BO_ 2498859366 0;
BA_ "GenMsgSendType" BO_ 2498859367 0;
BA_ "GenMsgSendType" BO_ 2498859368 0;
BA_ "GenMsgSendType" BO_ 2498859369 0;
BA_ "GenMsgSendType" BO_ 2498859370 0;
BA_ "GenMsgSendType" BO_ 2498859371 0;
BA_ "GenMsgSendType" BO_ 2498859372 0;
BA_ "GenMsgSendType" BO_ 2498859621 0;
BA_ "GenMsgSendType" BO_ 2498859622 0;
BA_ "GenMsgSendType" BO_ 2498859623 0;
BA_ "GenMsgSendType" BO_ 2498859624 0;
BA_ "GenMsgSendType" BO_ 2498859625 0;
BA_ "GenMsgSendType" BO_ 2498859626 0;
BA_ "GenMsgSendType" BO_ 2498859627 0;
BA_ "GenMsgSendType" BO_ 2498859628 0;
BA_ "GenMsgSendType" BO_ 2498859877 0;
BA_ "GenMsgSendType" BO_ 2498859878 0;
BA_ "GenMsgSendType" BO_ 2498859879 0;
BA_ "GenMsgSendType" BO_ 2498859880 0;
BA_ "GenMsgSendType" BO_ 2498859881 0;
BA_ "GenMsgSendType" BO_ 2498859882 0;
BA_ "GenMsgSendType" BO_ 2498859883 0;
BA_ "GenMsgSendType" BO_ 2498859884 0;
BA_ "GenMsgSendType" BO_ 2498860389 0;
BA_ "GenMsgSendType" BO_ 2498860390 0;
BA_ "GenMsgSendType" BO_ 2498860391 0;
BA_ "GenMsgSendType" BO_ 2498860392 0;
BA_ "GenMsgSendType" BO_ 2498860393 0;
BA_ "GenMsgSendType" BO_ 2498860394 0;
BA_ "GenMsgSendType" BO_ 2498860395 0;
BA_ "GenMsgSendType" BO_ 2498860396 0;
BA_ "GenMsgSendType" BO_ 2498860901 0;
BA_ "GenMsgSendType" BO_ 2498860902 0;
BA_ "GenMsgSendType" BO_ 2498860903 0;
BA_ "GenMsgSendType" BO_ 2498860904 0;
BA_ "GenMsgSendType" BO_ 2498860905 0;
BA_ "GenMsgSendType" BO_ 2498860906 0;
BA_ "GenMsgSendType" BO_ 2498860907 0;
BA_ "GenMsgSendType" BO_ 2498860908 0;
BA_ "GenMsgSendType" BO_ 2498861157 0;
BA_ "GenMsgSendType" BO_ 2498861158 0;
BA_ "GenMsgSendType" BO_ 2498861159 0;
BA_ "GenMsgSendType" BO_ 2498861160 0;
BA_ "GenMsgSendType" BO_ 2498861161 0;
BA_ "GenMsgSendType" BO_ 2498861162 0;
BA_ "GenMsgSendType" BO_ 2498861163 0;
BA_ "GenMsgSendType" BO_ 2498861164 0;
BA_ "GenMsgSendType" BO_ 2498861925 0;
BA_ "GenMsgSendType" BO_ 2498861926 0;
BA_ "GenMsgSendType" BO_ 2498861927 0;
BA_ "GenMsgSendType" BO_ 2498861928 0;
BA_ "GenMsgSendType" BO_ 2498861929 0;
BA_ "GenMsgSendType" BO_ 2498861930 0;
BA_ "GenMsgSendType" BO_ 2498861931 0;
BA_ "GenMsgSendType" BO_ 2498861932 0;
BA_ "GenMsgSendType" BO_ 2498862181 0;
BA_ "GenMsgSendType" BO_ 2498862182 0;
BA_ "GenMsgSendType" BO_ 2498862183 0;
BA_ "GenMsgSendType" BO_ 2498862184 0;
BA_ "GenMsgSendType" BO_ 2498862185 0;
BA_ "GenMsgSendType" BO_ 2498862186 0;
BA_ "GenMsgSendType" BO_ 2498862187 0;
BA_ "GenMsgSendType" BO_ 2498862188 0;
BA_ "GenMsgSendType" BO_ 2498862437 0;
BA_ "GenMsgSendType" BO_ 2498862438 0;
BA_ "GenMsgSendType" BO_ 2498862439 0;
BA_ "GenMsgSendType" BO_ 2498862440 0;
BA_ "GenMsgSendType" BO_ 2498862441 0;
BA_ "GenMsgSendType" BO_ 2498862442 0;
BA_ "GenMsgSendType" BO_ 2498862443 0;
BA_ "GenMsgSendType" BO_ 2498862444 0;
BA_ "GenMsgSendType" BO_ 2499500389 0;
BA_ "GenMsgSendType" BO_ 2499500390 0;
BA_ "GenMsgSendType" BO_ 2499500391 0;
BA_ "GenMsgSendType" BO_ 2499500392 0;
BA_ "GenMsgSendType" BO_ 2499500393 0;
BA_ "GenMsgSendType" BO_ 2499500394 0;
BA_ "GenMsgSendType" BO_ 2499500395 0;
BA_ "GenMsgSendType" BO_ 2499500396 0;
BA_ "GenMsgSendType" BO_ 2499739749 0;
BA_ "GenMsgSendType" BO_ 2499739750 0;
BA_ "GenMsgSendType" BO_ 2499739751 0;
BA_ "GenMsgSendType" BO_ 2499739752 0;
BA_ "GenMsgSendType" BO_ 2499739753 0;
BA_ "GenMsgSendType" BO_ 2499739754 0;
BA_ "GenMsgSendType" BO_ 2499739755 0;
BA_ "GenMsgSendType" BO_ 2499739756 0;
BA_ "GenMsgSendType" BO_ 2499740005 0;
BA_ "GenMsgSendType" BO_ 2499740006 0;
BA_ "GenMsgSendType" BO_ 2499740007 0;
BA_ "GenMsgSendType" BO_ 2499740008 0;
BA_ "GenMsgSendType" BO_ 2499740009 0;
BA_ "GenMsgSendType" BO_ 2499740010 0;
BA_ "GenMsgSendType" BO_ 2499740011 0;
BA_ "GenMsgSendType" BO_ 2499740012 0;
BA_ "GenMsgSendType" BO_ 2499740261 0;
BA_ "GenMsgSendType" BO_ 2499740262 0;
BA_ "GenMsgSendType" BO_ 2499740263 0;
BA_ "GenMsgSendType" BO_ 2499740264 0;
BA_ "GenMsgSendType" BO_ 2499740265 0;
BA_ "GenMsgSendType" BO_ 2499740266 0;
BA_ "GenMsgSendType" BO_ 2499740267 0;
BA_ "GenMsgSendType" BO_ 2499740268 0;
BA_ "GenMsgSendType" BO_ 2499740517 0;
BA_ "GenMsgSendType" BO_ 2499740518 0;
BA_ "GenMsgSendType" BO_ 2499740519 0;
BA_ "GenMsgSendType" BO_ 2499740520 0;
BA_ "GenMsgSendType" BO_ 2499740521 0;
BA_ "GenMsgSendType" BO_ 2499740522 0;
BA_ "GenMsgSendType" BO_ 2499740523 0;
BA_ "GenMsgSendType" BO_ 2499740524 0;
BA_ "GenMsgCycleTime" BO_ 2498859365 100;
BA_ "GenMsgCycleTime" BO_ 2498859366 100;
BA_ "GenMsgCycleTime" BO_ 2498859367 100;
BA_ "GenMsgCycleTime" BO_ 2498859368 100;
BA_ "GenMsgCycleTime" BO_ 2498859369 100;
BA_ "GenMsgCycleTime" BO_ 2498859370 100;
BA_ "GenMsgCycleTime" BO_ 2498859371 100;
BA_ "GenMsgCycleTime" BO_ 2498859372 100;
BA_ "GenMsgCycleTime" BO_ 2498859621 100;
BA_ "GenMsgCycleTime" BO_ 2498859622 100;
BA_ "GenMsgCycleTime" BO_ 2498859623 100;
BA_ "GenMsgCycleTime" BO_ 2498859624 100;
BA_ "GenMsgCycleTime" BO_ 2498859625 100;
BA_ "GenMsgCycleTime" BO_ 2498859626 100;
BA_ "GenMsgCycleTime" BO_ 2498859627 100;
BA_ "GenMsgCycleTime" BO_ 2498859628 100;
BA_ "GenMsgCycleTime" BO_ 2498859877 100;
BA_ "GenMsgCycleTime" BO_ 2498859878 100;
BA_ "GenMsgCycleTime" BO_ 2498859879 100;
BA_ "GenMsgCycleTime" BO_ 2498859880 100;
BA_ "GenMsgCycleTime" BO_ 2498859881 100;
BA_ "GenMsgCycleTime" BO_ 2498859882 100;
BA_ "GenMsgCycleTime" BO_ 2498859883 100;
BA_ "GenMsgCycleTime" BO_ 2498859884 100;
BA_ "GenMsgCycleTime" BO_ 2498860389 100;
BA_ "GenMsgCycleTime" BO_ 2498860390 100;
BA_ "GenMsgCycleTime" BO_ 2498860391 100;
BA_ "GenMsgCycleTime" BO_ 2498860392 100;
BA_ "GenMsgCycleTime" BO_ 2498860393 100;
BA_ "GenMsgCycleTime" BO_ 2498860394 100;
BA_ "GenMsgCycleTime" BO_ 2498860395 100;
BA_ "GenMsgCycleTime" BO_ 2498860396 100;
BA_ "GenMsgCycleTime" BO_ 2498860901 100;
BA_ "GenMsgCycleTime" BO_ 2498860902 100;
BA_ "GenMsgCycleTime" BO_ 2498860903 100;
BA_ "GenMsgCycleTime" BO_ 2498860904 100;
BA_ "GenMsgCycleTime" BO_ 2498860905 100;
BA_ "GenMsgCycleTime" BO_ 2498860906 100;
BA_ "GenMsgCycleTime" BO_ 2498860907 100;
BA_ "GenMsgCycleTime" BO_ 2498860908 100;
BA_ "GenMsgCycleTime" BO_ 2498861157 100;
BA_ "GenMsgCycleTime" BO_ 2498861158 100;
BA_ "GenMsgCycleTime" BO_ 2498861159 100;
BA_ "GenMsgCycleTime" BO_ 2498861160 100;
BA_ "GenMsgCycleTime" BO_ 2498861161 100;
BA_ "GenMsgCycleTime" BO_ 2498861162 100;
BA_ "GenMsgCycleTime" BO_ 2498861163 100;
BA_ "GenMsgCycleTime" BO_ 2498861164 100;
BA_ "GenMsgCycleTime" BO_ 2498861925 100;
BA_ "GenMsgCycleTime" BO_ 2498861926 100;
BA_ "GenMsgCycleTime" BO_ 2498861927 100;
BA_ "GenMsgCycleTime" BO_ 2498861928 100;
BA_ "GenMsgCycleTime" BO_ 2498861929 100;
BA_ "GenMsgCycleTime" BO_ 2498861930 100;
BA_ "GenMsgCycleTime" BO_ 2498861931 100;
BA_ "GenMsgCycleTime" BO_ 2498861932 100;
BA_ "GenMsgCycleTime" BO_ 2498862181 100;
BA_ "GenMsgCycleTime" BO_ 2498862182 100;
BA_ "GenMsgCycleTime" BO_ 2498862183 100;
BA_ "GenMsgCycleTime" BO_ 2498862184 100;
BA_ "GenMsgCycleTime" BO_ 2498862185 100;
BA_ "GenMsgCycleTime" BO_ 2498862186 100;
BA_ "GenMsgCycleTime" BO_ 2498862187 100;
BA_ "GenMsgCycleTime" BO_ 2498862188 100;
BA_ "GenMsgCycleTime" BO_ 2498862437 100;
BA_ "GenMsgCycleTime" BO_ 2498862438 100;
BA_ "GenMsgCycleTime" BO_ 2498862439 100;
BA_ "GenMsgCycleTime" BO_ 2498862440 100;
BA_ "GenMsgCycleTime" BO_ 2498862441 100;
BA_ "GenMsgCycleTime" BO_ 2498862442 100;
BA_ "GenMsgCycleTime" BO_ 2498862443 100;
BA_ "GenMsgCycleTime" BO_ 2498862444 100;
BA_ "GenMsgCycleTime" BO_ 2499500389 100;
BA_ "GenMsgCycleTime" BO_ 2499500390 100;
BA_ "GenMsgCycleTime" BO_ 2499500391 100;
BA_ "GenMsgCycleTime" BO_ 2499500392 100;
BA_ "GenMsgCycleTime" BO_ 2499500393 100;
BA_ "GenMsgCycleTime" BO_ 2499500394 100;
BA_ "GenMsgCycleTime" BO_ 2499500395 100;
BA_ "GenMsgCycleTime" BO_ 2499500396 100;
BA_ "GenMsgCycleTime" BO_ 2499739749 100;
BA_ "GenMsgCycleTime" BO_ 2499739750 100;
BA_ "GenMsgCycleTime" BO_ 2499739751 100;
BA_ "GenMsgCycleTime" BO_ 2499739752 100;
BA_ "GenMsgCycleTime" BO_ 2499739753 100;
BA_ "GenMsgCycleTime" BO_ 2499739754 100;
BA_ "GenMsgCycleTime" BO_ 2499739755 100;
BA_ "GenMsgCycleTime" BO_ 2499739756 100;
BA_ "GenMsgCycleTime" BO_ 2499740005 1000;
BA_ "GenMsgCycleTime" BO_ 2499740006 1000;
BA_ "GenMsgCycleTime" BO_ 2499740007 1000;
BA_ "GenMsgCycleTime" BO_ 2499740008 1000;
BA_ "GenMsgCycleTime" BO_ 2499740009 1000;
BA_ "GenMsgCycleTime" BO_ 2499740010 1000;
BA_ "GenMsgCycleTime" BO_ 2499740011 1000;
BA_ "GenMsgCycleTime" BO_ 2499740012 1000;
BA_ "GenMsgCycleTime" BO_ 2499740261 1000;
BA_ "GenMsgCycleTime" BO_ 2499740262 1000;
BA_ "GenMsgCycleTime" BO_ 2499740263 1000;
BA_ "GenMsgCycleTime" BO_ 2499740264 1000;
BA_ "GenMsgCycleTime" BO_ 2499740265 1000;
BA_ "GenMsgCycleTime" BO_ 2499740266 1000;
BA_ "GenMsgCycleTime" BO_ 2499740267 1000;
BA_ "GenMsgCycleTime" BO_ 2499740268 1000;
BA_ "GenMsgCycleTime" BO_ 2499740517 100;
BA_ "GenMsgCycleTime" BO_ 2499740518 100;
BA_ "GenMsgCycleTime" BO_ 2499740519 100;
BA_ "GenMsgCycleTime" BO_ 2499740520 100;
BA_ "GenMsgCycleTime" BO_ 2499740521 100;
BA_ "GenMsgCycleTime" BO_ 2499740522 100;
BA_ "GenMsgCycleTime" BO_ 2499740523 100;
BA_ "GenMsgCycleTime" BO_ 2499740524 100;

VAL_ 2485806436 HVESP01_hvBusConnectCmd  3 "DontCare"  2 "EmergencyContactorClose"  1 "CloseContactor"  0 "OpenContactor"  ;
VAL_ 2485806436 HVESP01_hvBusPassveIsoTest  3 "DontCare"  2 "Reserved"  1 "PassiveIsolationTestRequested"  0 "PassiveIsolationTestNotRequested"  ;
VAL_ 2485806436 HVESP01_hvBusActiveIsoTest  3 "DontCare"  2 "Reserved"  1 "ActiveIsoTestRequested"  0 "ActiveIsoTestNotRequested"  ;
VAL_ 2485806436 HVESP01_powerDownCmd  3 "DontCare"  2 "EmergencyPowerDown"  1 "NormalPowerDown"  0 "PowerDownNotRequested"  ;
VAL_ 2485806436 HVESP01_systemHvStatus  3 "DontCare"  2 "Reserved"  1 "Active"  0 "Inactive"  ;
VAL_ 2498860901 HVESP01_operationalStatus_1  15 "NA"  14 "Error"  13 "Reserved"  12 "Reserved"  11 "Reserved"  10 "Reserved"  9 "Reserved"  8 "Reserved"  7 "Reserved"  6 "DisabledInt"  5 "DisabledExtCmd"  4 "EmergencyPowerDown"  3 "NormalPowerDown"  2 "Operational"  1 "InitComplete"  0 "InitInProcess"  ;
VAL_ 2498860901 HVESP01_hvBusConnectionStatus_1  15 "NA"  14 "Error"  13 "Reserved"  12 "Reserved"  11 "Reserved"  10 "Reserved"  9 "Reserved"  8 "Reserved"  7 "Reserved"  6 "Reserved"  5 "Reserved"  4 "DisconnectedPreChgFail"  3 "DisconnectionInProcess"  2 "ConnectionInProcess"  1 "Connected"  0 "Disconnected"  ;
VAL_ 2498860901 HVESP01_cellBalancingActive_1  3 "NA"  2 "Error"  1 "CellBalancingActive"  0 "CellBalancingNotActive"  ;
VAL_ 2498860901 HVESP01_hvilStatus_1  3 "NA"  2 "Error"  1 "HvilOpen"  0 "HvilClosed"  ;
VAL_ 2498860901 HVESP01_hvBusPassveIsoTestStatus_1  15 "NA"  14 "Error"  13 "Reserved"  12 "Reserved"  11 "Reserved"  10 "Reserved"  9 "Reserved"  8 "Reserved"  7 "Reserved"  6 "Reserved"  5 "TestCompleteFault"  4 "TestCompleteMarginal"  3 "TestCompleteAcceptable"  2 "TestInProcess"  1 "TestRequestedNotInProgress"  0 "NoTestRequested"  ;
VAL_ 2498860901 HVESP01_hvBusActiveIsoTestStatus_1  15 "NA"  14 "Error"  13 "Reserved"  12 "Reserved"  11 "Reserved"  10 "Reserved"  9 "Reserved"  8 "Reserved"  7 "Reserved"  6 "Reserved"  5 "TestCompleteFault"  4 "TestCompleteMarginal"  3 "TestCompleteAcceptable"  2 "TestInProcess"  1 "TestRequestedNotInProgress"  0 "NoTestRequested"  ;
VAL_ 2498860901 HVESP01_hvBusPrechgRelayState_1  3 "NA"  2 "Error"  1 "RelayClosed"  0 "RelayOpen"  ;
VAL_ 2498860901 HVESP01_hvBusNegContState_1  3 "NA"  2 "Error"  1 "ContactorClosed"  0 "ContactorOpen"  ;
VAL_ 2498860901 HVESP01_hvBusPosContState_1  3 "NA"  2 "Error"  1 "ContactorClosed"  0 "ContactorOpen"  ;
VAL_ 2498860902 HVESP01_operationalStatus_2  15 "NA"  14 "Error"  13 "Reserved"  12 "Reserved"  11 "Reserved"  10 "Reserved"  9 "Reserved"  8 "Reserved"  7 "Reserved"  6 "DisabledInt"  5 "DisabledExtCmd"  4 "EmergencyPowerDown"  3 "NormalPowerDown"  2 "Operational"  1 "InitComplete"  0 "InitInProcess"  ;
VAL_ 2498860902 HVESP01_hvBusConnectionStatus_2  15 "NA"  14 "Error"  13 "Reserved"  12 "Reserved"  11 "Reserved"  10 "Reserved"  9 "Reserved"  8 "Reserved"  7 "Reserved"  6 "Reserved"  5 "Reserved"  4 "DisconnectedPreChgFail"  3 "DisconnectionInProcess"  2 "ConnectionInProcess"  1 "Connected"  0 "Disconnected"  ;
VAL_ 2498860902 HVESP01_cellBalancingActive_2  3 "NA"  2 "Error"  1 "CellBalancingActive"  0 "CellBalancingNotActive"  ;
VAL_ 2498860902 HVESP01_hvilStatus_2  3 "NA"  2 "Error"  1 "HvilOpen"  0 "HvilClosed"  ;
VAL_ 2498860902 HVESP01_hvBusPassveIsoTestStatus_2  15 "NA"  14 "Error"  13 "Reserved"  12 "Reserved"  11 "Reserved"  10 "Reserved"  9 "Reserved"  8 "Reserved"  7 "Reserved"  6 "Reserved"  5 "TestCompleteFault"  4 "TestCompleteMarginal"  3 "TestCompleteAcceptable"  2 "TestInProcess"  1 "TestRequestedNotInProgress"  0 "NoTestRequested"  ;
VAL_ 2498860902 HVESP01_hvBusActiveIsoTestStatus_2  15 "NA"  14 "Error"  13 "Reserved"  12 "Reserved"  11 "Reserved"  10 "Reserved"  9 "Reserved"  8 "Reserved"  7 "Reserved"  6 "Reserved"  5 "TestCompleteFault"  4 "TestCompleteMarginal"  3 "TestCompleteAcceptable"  2 "TestInProcess"  1 "TestRequestedNotInProgress"  0 "NoTestRequested"  ;
VAL_ 2498860902 HVESP01_hvBusPrechgRelayState_2  3 "NA"  2 "Error"  1 "RelayClosed"  0 "RelayOpen"  ;
VAL_ 2498860902 HVESP01_hvBusNegContState_2  3 "NA"  2 "Error"  1 "ContactorClosed"  0 "ContactorOpen"  ;
VAL_ 2498860902 HVESP01_hvBusPosContState_2  3 "NA"  2 "Error"  1 "ContactorClosed"  0 "ContactorOpen"  ;
VAL_ 2498860903 HVESP01_operationalStatus_3  15 "NA"  14 "Error"  13 "Reserved"  12 "Reserved"  11 "Reserved"  10 "Reserved"  9 "Reserved"  8 "Reserved"  7 "Reserved"  6 "DisabledInt"  5 "DisabledExtCmd"  4 "EmergencyPowerDown"  3 "NormalPowerDown"  2 "Operational"  1 "InitComplete"  0 "InitInProcess"  ;
VAL_ 2498860903 HVESP01_hvBusConnectionStatus_3  15 "NA"  14 "Error"  13 "Reserved"  12 "Reserved"  11 "Reserved"  10 "Reserved"  9 "Reserved"  8 "Reserved"  7 "Reserved"  6 "Reserved"  5 "Reserved"  4 "DisconnectedPreChgFail"  3 "DisconnectionInProcess"  2 "ConnectionInProcess"  1 "Connected"  0 "Disconnected"  ;
VAL_ 2498860903 HVESP01_cellBalancingActive_3  3 "NA"  2 "Error"  1 "CellBalancingActive"  0 "CellBalancingNotActive"  ;
VAL_ 2498860903 HVESP01_hvilStatus_3  3 "NA"  2 "Error"  1 "HvilOpen"  0 "HvilClosed"  ;
VAL_ 2498860903 HVESP01_hvBusPassveIsoTestStatus_3  15 "NA"  14 "Error"  13 "Reserved"  12 "Reserved"  11 "Reserved"  10 "Reserved"  9 "Reserved"  8 "Reserved"  7 "Reserved"  6 "Reserved"  5 "TestCompleteFault"  4 "TestCompleteMarginal"  3 "TestCompleteAcceptable"  2 "TestInProcess"  1 "TestRequestedNotInProgress"  0 "NoTestRequested"  ;
VAL_ 2498860903 HVESP01_hvBusActiveIsoTestStatus_3  15 "NA"  14 "Error"  13 "Reserved"  12 "Reserved"  11 "Reserved"  10 "Reserved"  9 "Reserved"  8 "Reserved"  7 "Reserved"  6 "Reserved"  5 "TestCompleteFault"  4 "TestCompleteMarginal"  3 "TestCompleteAcceptable"  2 "TestInProcess"  1 "TestRequestedNotInProgress"  0 "NoTestRequested"  ;
VAL_ 2498860903 HVESP01_hvBusPrechgRelayState_3  3 "NA"  2 "Error"  1 "RelayClosed"  0 "RelayOpen"  ;
VAL_ 2498860903 HVESP01_hvBusNegContState_3  3 "NA"  2 "Error"  1 "ContactorClosed"  0 "ContactorOpen"  ;
VAL_ 2498860903 HVESP01_hvBusPosContState_3  3 "NA"  2 "Error"  1 "ContactorClosed"  0 "ContactorOpen"  ;
VAL_ 2498860904 HVESP01_operationalStatus_4  15 "NA"  14 "Error"  13 "Reserved"  12 "Reserved"  11 "Reserved"  10 "Reserved"  9 "Reserved"  8 "Reserved"  7 "Reserved"  6 "DisabledInt"  5 "DisabledExtCmd"  4 "EmergencyPowerDown"  3 "NormalPowerDown"  2 "Operational"  1 "InitComplete"  0 "InitInProcess"  ;
VAL_ 2498860904 HVESP01_hvBusConnectionStatus_4  15 "NA"  14 "Error"  13 "Reserved"  12 "Reserved"  11 "Reserved"  10 "Reserved"  9 "Reserved"  8 "Reserved"  7 "Reserved"  6 "Reserved"  5 "Reserved"  4 "DisconnectedPreChgFail"  3 "DisconnectionInProcess"  2 "ConnectionInProcess"  1 "Connected"  0 "Disconnected"  ;
VAL_ 2498860904 HVESP01_cellBalancingActive_4  3 "NA"  2 "Error"  1 "CellBalancingActive"  0 "CellBalancingNotActive"  ;
VAL_ 2498860904 HVESP01_hvilStatus_4  3 "NA"  2 "Error"  1 "HvilOpen"  0 "HvilClosed"  ;
VAL_ 2498860904 HVESP01_hvBusPassveIsoTestStatus_4  15 "NA"  14 "Error"  13 "Reserved"  12 "Reserved"  11 "Reserved"  10 "Reserved"  9 "Reserved"  8 "Reserved"  7 "Reserved"  6 "Reserved"  5 "TestCompleteFault"  4 "TestCompleteMarginal"  3 "TestCompleteAcceptable"  2 "TestInProcess"  1 "TestRequestedNotInProgress"  0 "NoTestRequested"  ;
VAL_ 2498860904 HVESP01_hvBusActiveIsoTestStatus_4  15 "NA"  14 "Error"  13 "Reserved"  12 "Reserved"  11 "Reserved"  10 "Reserved"  9 "Reserved"  8 "Reserved"  7 "Reserved"  6 "Reserved"  5 "TestCompleteFault"  4 "TestCompleteMarginal"  3 "TestCompleteAcceptable"  2 "TestInProcess"  1 "TestRequestedNotInProgress"  0 "NoTestRequested"  ;
VAL_ 2498860904 HVESP01_hvBusPrechgRelayState_4  3 "NA"  2 "Error"  1 "RelayClosed"  0 "RelayOpen"  ;
VAL_ 2498860904 HVESP01_hvBusNegContState_4  3 "NA"  2 "Error"  1 "ContactorClosed"  0 "ContactorOpen"  ;
VAL_ 2498860904 HVESP01_hvBusPosContState_4  3 "NA"  2 "Error"  1 "ContactorClosed"  0 "ContactorOpen"  ;
VAL_ 2498860905 HVESP01_operationalStatus_5  15 "NA"  14 "Error"  13 "Reserved"  12 "Reserved"  11 "Reserved"  10 "Reserved"  9 "Reserved"  8 "Reserved"  7 "Reserved"  6 "DisabledInt"  5 "DisabledExtCmd"  4 "EmergencyPowerDown"  3 "NormalPowerDown"  2 "Operational"  1 "InitComplete"  0 "InitInProcess"  ;
VAL_ 2498860905 HVESP01_hvBusConnectionStatus_5  15 "NA"  14 "Error"  13 "Reserved"  12 "Reserved"  11 "Reserved"  10 "Reserved"  9 "Reserved"  8 "Reserved"  7 "Reserved"  6 "Reserved"  5 "Reserved"  4 "DisconnectedPreChgFail"  3 "DisconnectionInProcess"  2 "ConnectionInProcess"  1 "Connected"  0 "Disconnected"  ;
VAL_ 2498860905 HVESP01_cellBalancingActive_5  3 "NA"  2 "Error"  1 "CellBalancingActive"  0 "CellBalancingNotActive"  ;
VAL_ 2498860905 HVESP01_hvilStatus_5  3 "NA"  2 "Error"  1 "HvilOpen"  0 "HvilClosed"  ;
VAL_ 2498860905 HVESP01_hvBusPassveIsoTestStatus_5  15 "NA"  14 "Error"  13 "Reserved"  12 "Reserved"  11 "Reserved"  10 "Reserved"  9 "Reserved"  8 "Reserved"  7 "Reserved"  6 "Reserved"  5 "TestCompleteFault"  4 "TestCompleteMarginal"  3 "TestCompleteAcceptable"  2 "TestInProcess"  1 "TestRequestedNotInProgress"  0 "NoTestRequested"  ;
VAL_ 2498860905 HVESP01_hvBusActiveIsoTestStatus_5  15 "NA"  14 "Error"  13 "Reserved"  12 "Reserved"  11 "Reserved"  10 "Reserved"  9 "Reserved"  8 "Reserved"  7 "Reserved"  6 "Reserved"  5 "TestCompleteFault"  4 "TestCompleteMarginal"  3 "TestCompleteAcceptable"  2 "TestInProcess"  1 "TestRequestedNotInProgress"  0 "NoTestRequested"  ;
VAL_ 2498860905 HVESP01_hvBusPrechgRelayState_5  3 "NA"  2 "Error"  1 "RelayClosed"  0 "RelayOpen"  ;
VAL_ 2498860905 HVESP01_hvBusNegContState_5  3 "NA"  2 "Error"  1 "ContactorClosed"  0 "ContactorOpen"  ;
VAL_ 2498860905 HVESP01_hvBusPosContState_5  3 "NA"  2 "Error"  1 "ContactorClosed"  0 "ContactorOpen"  ;
VAL_ 2498860906 HVESP01_operationalStatus_6  15 "NA"  14 "Error"  13 "Reserved"  12 "Reserved"  11 "Reserved"  10 "Reserved"  9 "Reserved"  8 "Reserved"  7 "Reserved"  6 "DisabledInt"  5 "DisabledExtCmd"  4 "EmergencyPowerDown"  3 "NormalPowerDown"  2 "Operational"  1 "InitComplete"  0 "InitInProcess"  ;
VAL_ 2498860906 HVESP01_hvBusConnectionStatus_6  15 "NA"  14 "Error"  13 "Reserved"  12 "Reserved"  11 "Reserved"  10 "Reserved"  9 "Reserved"  8 "Reserved"  7 "Reserved"  6 "Reserved"  5 "Reserved"  4 "DisconnectedPreChgFail"  3 "DisconnectionInProcess"  2 "ConnectionInProcess"  1 "Connected"  0 "Disconnected"  ;
VAL_ 2498860906 HVESP01_cellBalancingActive_6  3 "NA"  2 "Error"  1 "CellBalancingActive"  0 "CellBalancingNotActive"  ;
VAL_ 2498860906 HVESP01_hvilStatus_6  3 "NA"  2 "Error"  1 "HvilOpen"  0 "HvilClosed"  ;
VAL_ 2498860906 HVESP01_hvBusPassveIsoTestStatus_6  15 "NA"  14 "Error"  13 "Reserved"  12 "Reserved"  11 "Reserved"  10 "Reserved"  9 "Reserved"  8 "Reserved"  7 "Reserved"  6 "Reserved"  5 "TestCompleteFault"  4 "TestCompleteMarginal"  3 "TestCompleteAcceptable"  2 "TestInProcess"  1 "TestRequestedNotInProgress"  0 "NoTestRequested"  ;
VAL_ 2498860906 HVESP01_hvBusActiveIsoTestStatus_6  15 "NA"  14 "Error"  13 "Reserved"  12 "Reserved"  11 "Reserved"  10 "Reserved"  9 "Reserved"  8 "Reserved"  7 "Reserved"  6 "Reserved"  5 "TestCompleteFault"  4 "TestCompleteMarginal"  3 "TestCompleteAcceptable"  2 "TestInProcess"  1 "TestRequestedNotInProgress"  0 "NoTestRequested"  ;
VAL_ 2498860906 HVESP01_hvBusPrechgRelayState_6  3 "NA"  2 "Error"  1 "RelayClosed"  0 "RelayOpen"  ;
VAL_ 2498860906 HVESP01_hvBusNegContState_6  3 "NA"  2 "Error"  1 "ContactorClosed"  0 "ContactorOpen"  ;
VAL_ 2498860906 HVESP01_hvBusPosContState_6  3 "NA"  2 "Error"  1 "ContactorClosed"  0 "ContactorOpen"  ;
VAL_ 2498860907 HVESP01_operationalStatus_7  15 "NA"  14 "Error"  13 "Reserved"  12 "Reserved"  11 "Reserved"  10 "Reserved"  9 "Reserved"  8 "Reserved"  7 "Reserved"  6 "DisabledInt"  5 "DisabledExtCmd"  4 "EmergencyPowerDown"  3 "NormalPowerDown"  2 "Operational"  1 "InitComplete"  0 "InitInProcess"  ;
VAL_ 2498860907 HVESP01_hvBusConnectionStatus_7  15 "NA"  14 "Error"  13 "Reserved"  12 "Reserved"  11 "Reserved"  10 "Reserved"  9 "Reserved"  8 "Reserved"  7 "Reserved"  6 "Reserved"  5 "Reserved"  4 "DisconnectedPreChgFail"  3 "DisconnectionInProcess"  2 "ConnectionInProcess"  1 "Connected"  0 "Disconnected"  ;
VAL_ 2498860907 HVESP01_cellBalancingActive_7  3 "NA"  2 "Error"  1 "CellBalancingActive"  0 "CellBalancingNotActive"  ;
VAL_ 2498860907 HVESP01_hvilStatus_7  3 "NA"  2 "Error"  1 "HvilOpen"  0 "HvilClosed"  ;
VAL_ 2498860907 HVESP01_hvBusPassveIsoTestStatus_7  15 "NA"  14 "Error"  13 "Reserved"  12 "Reserved"  11 "Reserved"  10 "Reserved"  9 "Reserved"  8 "Reserved"  7 "Reserved"  6 "Reserved"  5 "TestCompleteFault"  4 "TestCompleteMarginal"  3 "TestCompleteAcceptable"  2 "TestInProcess"  1 "TestRequestedNotInProgress"  0 "NoTestRequested"  ;
VAL_ 2498860907 HVESP01_hvBusActiveIsoTestStatus_7  15 "NA"  14 "Error"  13 "Reserved"  12 "Reserved"  11 "Reserved"  10 "Reserved"  9 "Reserved"  8 "Reserved"  7 "Reserved"  6 "Reserved"  5 "TestCompleteFault"  4 "TestCompleteMarginal"  3 "TestCompleteAcceptable"  2 "TestInProcess"  1 "TestRequestedNotInProgress"  0 "NoTestRequested"  ;
VAL_ 2498860907 HVESP01_hvBusPrechgRelayState_7  3 "NA"  2 "Error"  1 "RelayClosed"  0 "RelayOpen"  ;
VAL_ 2498860907 HVESP01_hvBusNegContState_7  3 "NA"  2 "Error"  1 "ContactorClosed"  0 "ContactorOpen"  ;
VAL_ 2498860907 HVESP01_hvBusPosContState_7  3 "NA"  2 "Error"  1 "ContactorClosed"  0 "ContactorOpen"  ;
VAL_ 2498860908 HVESP01_operationalStatus_8  15 "NA"  14 "Error"  13 "Reserved"  12 "Reserved"  11 "Reserved"  10 "Reserved"  9 "Reserved"  8 "Reserved"  7 "Reserved"  6 "DisabledInt"  5 "DisabledExtCmd"  4 "EmergencyPowerDown"  3 "NormalPowerDown"  2 "Operational"  1 "InitComplete"  0 "InitInProcess"  ;
VAL_ 2498860908 HVESP01_hvBusConnectionStatus_8  15 "NA"  14 "Error"  13 "Reserved"  12 "Reserved"  11 "Reserved"  10 "Reserved"  9 "Reserved"  8 "Reserved"  7 "Reserved"  6 "Reserved"  5 "Reserved"  4 "DisconnectedPreChgFail"  3 "DisconnectionInProcess"  2 "ConnectionInProcess"  1 "Connected"  0 "Disconnected"  ;
VAL_ 2498860908 HVESP01_cellBalancingActive_8  3 "NA"  2 "Error"  1 "CellBalancingActive"  0 "CellBalancingNotActive"  ;
VAL_ 2498860908 HVESP01_hvilStatus_8  3 "NA"  2 "Error"  1 "HvilOpen"  0 "HvilClosed"  ;
VAL_ 2498860908 HVESP01_hvBusPassveIsoTestStatus_8  15 "NA"  14 "Error"  13 "Reserved"  12 "Reserved"  11 "Reserved"  10 "Reserved"  9 "Reserved"  8 "Reserved"  7 "Reserved"  6 "Reserved"  5 "TestCompleteFault"  4 "TestCompleteMarginal"  3 "TestCompleteAcceptable"  2 "TestInProcess"  1 "TestRequestedNotInProgress"  0 "NoTestRequested"  ;
VAL_ 2498860908 HVESP01_hvBusActiveIsoTestStatus_8  15 "NA"  14 "Error"  13 "Reserved"  12 "Reserved"  11 "Reserved"  10 "Reserved"  9 "Reserved"  8 "Reserved"  7 "Reserved"  6 "Reserved"  5 "TestCompleteFault"  4 "TestCompleteMarginal"  3 "TestCompleteAcceptable"  2 "TestInProcess"  1 "TestRequestedNotInProgress"  0 "NoTestRequested"  ;
VAL_ 2498860908 HVESP01_hvBusPrechgRelayState_8  3 "NA"  2 "Error"  1 "RelayClosed"  0 "RelayOpen"  ;
VAL_ 2498860908 HVESP01_hvBusNegContState_8  3 "NA"  2 "Error"  1 "ContactorClosed"  0 "ContactorOpen"  ;
VAL_ 2498860908 HVESP01_hvBusPosContState_8  3 "NA"  2 "Error"  1 "ContactorClosed"  0 "ContactorOpen"  ;
VAL_ 2499740773 HVESP01_SystemState_1  14 "Unknown"  13 "Disconnect"  12 "Charge"  11 "Drive"  10 "ExternalIsoTestCharge"  9 "ExternalIsoTestDrive"  8 "ConnectChargeStagger"  7 "ConnectChargeBusJoin"  6 "ConnectChargePrechg"  5 "ConnectDriveStagger"  4 "ConnectDriveBusJoin"  3 "ConnectDrivePrechg"  2 "StandbyReady"  1 "StandbyNotReady"  0 "Cooldown"  ;
VAL_ 2499740774 HVESP01_SystemState_2  14 "Unknown"  13 "Disconnect"  12 "Charge"  11 "Drive"  10 "ExternalIsoTestCharge"  9 "ExternalIsoTestDrive"  8 "ConnectChargeStagger"  7 "ConnectChargeBusJoin"  6 "ConnectChargePrechg"  5 "ConnectDriveStagger"  4 "ConnectDriveBusJoin"  3 "ConnectDrivePrechg"  2 "StandbyReady"  1 "StandbyNotReady"  0 "Cooldown"  ;
VAL_ 2499740775 HVESP01_SystemState_3  14 "Unknown"  13 "Disconnect"  12 "Charge"  11 "Drive"  10 "ExternalIsoTestCharge"  9 "ExternalIsoTestDrive"  8 "ConnectChargeStagger"  7 "ConnectChargeBusJoin"  6 "ConnectChargePrechg"  5 "ConnectDriveStagger"  4 "ConnectDriveBusJoin"  3 "ConnectDrivePrechg"  2 "StandbyReady"  1 "StandbyNotReady"  0 "Cooldown"  ;
VAL_ 2499740776 HVESP01_SystemState_4  14 "Unknown"  13 "Disconnect"  12 "Charge"  11 "Drive"  10 "ExternalIsoTestCharge"  9 "ExternalIsoTestDrive"  8 "ConnectChargeStagger"  7 "ConnectChargeBusJoin"  6 "ConnectChargePrechg"  5 "ConnectDriveStagger"  4 "ConnectDriveBusJoin"  3 "ConnectDrivePrechg"  2 "StandbyReady"  1 "StandbyNotReady"  0 "Cooldown"  ;
VAL_ 2499740777 HVESP01_SystemState_5  14 "Unknown"  13 "Disconnect"  12 "Charge"  11 "Drive"  10 "ExternalIsoTestCharge"  9 "ExternalIsoTestDrive"  8 "ConnectChargeStagger"  7 "ConnectChargeBusJoin"  6 "ConnectChargePrechg"  5 "ConnectDriveStagger"  4 "ConnectDriveBusJoin"  3 "ConnectDrivePrechg"  2 "StandbyReady"  1 "StandbyNotReady"  0 "Cooldown"  ;
VAL_ 2499740778 HVESP01_SystemState_6  14 "Unknown"  13 "Disconnect"  12 "Charge"  11 "Drive"  10 "ExternalIsoTestCharge"  9 "ExternalIsoTestDrive"  8 "ConnectChargeStagger"  7 "ConnectChargeBusJoin"  6 "ConnectChargePrechg"  5 "ConnectDriveStagger"  4 "ConnectDriveBusJoin"  3 "ConnectDrivePrechg"  2 "StandbyReady"  1 "StandbyNotReady"  0 "Cooldown"  ;
VAL_ 2499740779 HVESP01_SystemState_7  14 "Unknown"  13 "Disconnect"  12 "Charge"  11 "Drive"  10 "ExternalIsoTestCharge"  9 "ExternalIsoTestDrive"  8 "ConnectChargeStagger"  7 "ConnectChargeBusJoin"  6 "ConnectChargePrechg"  5 "ConnectDriveStagger"  4 "ConnectDriveBusJoin"  3 "ConnectDrivePrechg"  2 "StandbyReady"  1 "StandbyNotReady"  0 "Cooldown"  ;
VAL_ 2499740780 HVESP01_SystemState_8  14 "Unknown"  13 "Disconnect"  12 "Charge"  11 "Drive"  10 "ExternalIsoTestCharge"  9 "ExternalIsoTestDrive"  8 "ConnectChargeStagger"  7 "ConnectChargeBusJoin"  6 "ConnectChargePrechg"  5 "ConnectDriveStagger"  4 "ConnectDriveBusJoin"  3 "ConnectDrivePrechg"  2 "StandbyReady"  1 "StandbyNotReady"  0 "Cooldown"  ;
